VERSION ""

NS_ :

BS_:

BU_: BCMB_AUXM FCIM MRCMA_RSCM SCMJ BCMB_ALCM SCMB_PSM SCMD SCMC HVAC_RCCM MRCMB MRCMA DASM GFM_FTRM BCMB_CAPM DCMH SFMB SFMA SOBDMD_AHCM_FOH TRM GWM _delete BCMB_ABM SODL SCMF RTM RHVAC PDM DCMG DCMF DCME SCMH SCMG HSWM RSM SODR DDM RBM RGTM DSM SCME GENERIC TSTR

BO_ 2015 TesterFunctionalReq_M1: 8 TSTR
 SG_ TesterFunctionalReq : 7|64@0+ (1,0) [0|1.84467E+019] "unitless"  DASM,GFM_FTRM,FCIM,MRCMA_RSCM,SODR,BCMB_AUXM,SODL,SCMB_PSM,SCMC,SCMD,HVAC_RCCM,MRCMA,MRCMB,RHVAC,BCMB_CAPM,BCMB_ALCM,SCMJ,BCMB_ABM,DCME,DCMF,DCMG,DCMH,SFMA,SFMB,SOBDMD_AHCM_FOH,PDM,SCMG,SCMH,TRM,RSM,RTM,GWM,DDM,DSM,HSWM,RBM,RGTM,SCME,SCMF

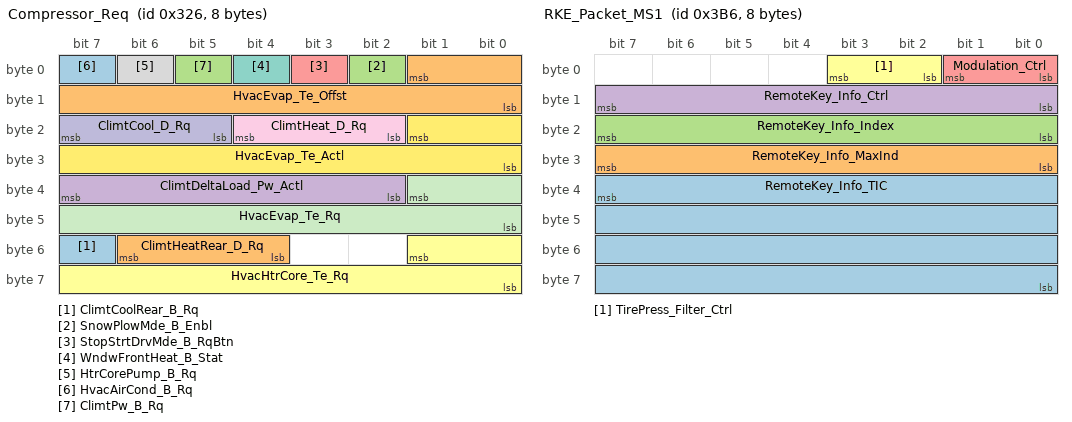
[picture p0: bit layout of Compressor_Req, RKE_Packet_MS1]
BO_ 806 Compressor_Req: 8 HVAC_RCCM
 SG_ ClimtCoolRear_B_Rq : 55|1@0+ (1,0) [0|1] "SED"  GWM
 SG_ ClimtHeatRear_D_Rq : 54|3@0+ (1,0) [0|7] "SED"  GWM
 SG_ SnowPlowMde_B_Enbl : 2|1@0+ (1,0) [0|1] "SED"  SCMG,SCMH,GWM,SCMC,SCMD
 SG_ ClimtDeltaLoad_Pw_Actl : 39|6@0+ (50,-1600) [-1600|1450] "watts"  GWM
 SG_ StopStrtDrvMde_B_RqBtn : 3|1@0+ (1,0) [0|1] "SED"  GWM
 SG_ HvacHtrCore_Te_Rq : 49|10@0+ (0.25,-50) [-50|205.75] "degC"  GWM
 SG_ WndwFrontHeat_B_Stat : 4|1@0+ (1,0) [0|1] "SED"  GWM
 SG_ HtrCorePump_B_Rq : 6|1@0+ (1,0) [0|1] "SED"  GWM
 SG_ ClimtHeat_D_Rq : 20|3@0+ (1,0) [0|7] "SED"  GWM
 SG_ ClimtCool_D_Rq : 23|3@0+ (1,0) [0|7] "SED"  GWM
 SG_ HvacEvap_Te_Rq : 33|10@0+ (0.125,-50) [-50|77.875] "Degrees C"  GWM
 SG_ HvacEvap_Te_Actl : 17|10@0+ (0.125,-50) [-50|77.75] "Degrees C"  GWM
 SG_ HvacAirCond_B_Rq : 7|1@0+ (1,0) [0|1] "SED"  GWM
 SG_ HvacEvap_Te_Offst : 1|10@0+ (0.125,-50) [-50|77.875] "Degrees C"  GWM
 SG_ ClimtPw_B_Rq : 5|1@0+ (1,0) [0|1] "SED"  GWM

BO_ 950 RKE_Packet_MS1: 8 GWM
 SG_ RemoteKey_Info_TIC : 39|32@0+ (1,0) [0|4294967295] "Unitless"  RTM
 SG_ RemoteKey_Info_MaxInd : 31|8@0+ (1,0) [0|255] "Unitless"  RTM
 SG_ RemoteKey_Info_Index : 23|8@0+ (1,0) [0|255] "Unitless"  RTM
 SG_ RemoteKey_Info_Ctrl : 15|8@0+ (1,0) [0|255] "Unitless"  GENERIC
 SG_ Modulation_Ctrl : 1|2@0+ (1,0) [0|3] "SED"  GENERIC
 SG_ TirePress_Filter_Ctrl : 3|2@0+ (1,0) [0|3] "SED"  RTM

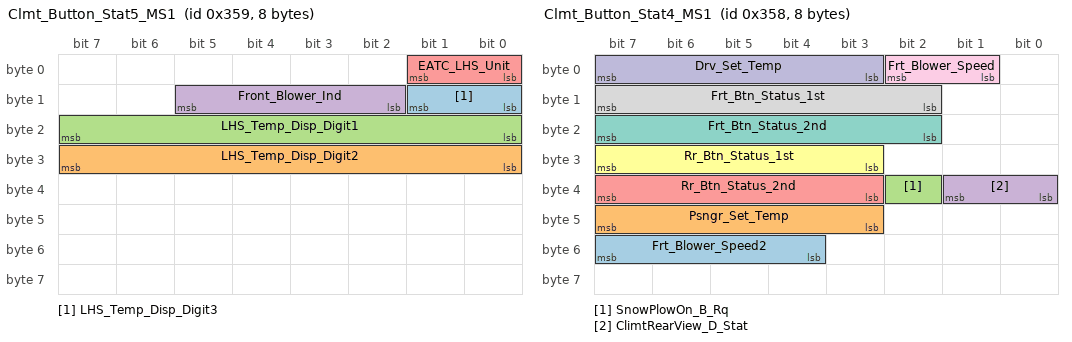
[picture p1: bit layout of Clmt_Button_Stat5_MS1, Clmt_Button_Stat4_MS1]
BO_ 857 Clmt_Button_Stat5_MS1: 8 GWM
 SG_ LHS_Temp_Disp_Digit3 : 9|2@0+ (1,0) [0|3] "SED"  FCIM,HVAC_RCCM
 SG_ LHS_Temp_Disp_Digit2 : 31|8@0+ (1,0) [0|255] "ASCII"  FCIM,HVAC_RCCM
 SG_ LHS_Temp_Disp_Digit1 : 23|8@0+ (1,0) [0|255] "ASCII"  FCIM,HVAC_RCCM
 SG_ Front_Blower_Ind : 13|4@0+ (1,0) [0|15] "SED"  FCIM,HVAC_RCCM
 SG_ EATC_LHS_Unit : 1|2@0+ (1,0) [0|3] "SED"  FCIM,HVAC_RCCM

BO_ 856 Clmt_Button_Stat4_MS1: 8 GWM
 SG_ Frt_Blower_Speed2 : 55|4@0+ (1,0) [0|15] "SED"  HVAC_RCCM,FCIM
 SG_ Psngr_Set_Temp : 47|5@0+ (1,0) [0|31] "SED"  FCIM,HVAC_RCCM
 SG_ SnowPlowOn_B_Rq : 34|1@0+ (1,0) [0|1] "SED"  HVAC_RCCM
 SG_ ClimtRearView_D_Stat : 33|2@0+ (1,0) [0|3] "SED"  FCIM,HVAC_RCCM
 SG_ Rr_Btn_Status_2nd : 39|5@0+ (1,0) [0|31] "SED"  FCIM,HVAC_RCCM
 SG_ Rr_Btn_Status_1st : 31|5@0+ (1,0) [0|31] "SED"  FCIM,HVAC_RCCM
 SG_ Frt_Btn_Status_2nd : 23|6@0+ (1,0) [0|63] "SED"  FCIM,HVAC_RCCM
 SG_ Frt_Btn_Status_1st : 15|6@0+ (1,0) [0|63] "SED"  FCIM,HVAC_RCCM
 SG_ Frt_Blower_Speed : 2|2@0+ (1,0) [0|3] "SED"  FCIM,HVAC_RCCM
 SG_ Drv_Set_Temp : 7|5@0+ (1,0) [0|31] "SED"  FCIM,HVAC_RCCM

BO_ 855 Clmt_Button_Stat3: 8 HVAC_RCCM
 SG_ Rr_Temp_Detents : 63|6@0+ (1,0) [0|63] "SED"  RHVAC,GWM
 SG_ Rr_Power_Btn_Stt : 57|2@0+ (1,0) [0|3] "SED"  RHVAC,GWM
 SG_ Rr_RH_Cond_Seat_Stat : 18|3@0+ (1,0) [0|7] "SED"  RHVAC,GWM
 SG_ Rr_Pnl_Flr_Btn_Stt : 33|2@0+ (1,0) [0|3] "SED"  RHVAC,GWM
 SG_ Rr_LH_Cond_Seat_Stat : 21|3@0+ (1,0) [0|7] "SED"  RHVAC,GWM
 SG_ CC_Rr_Stat_User_Adj : 7|4@0+ (1,0) [0|15] "SED"  RHVAC,GWM
 SG_ Rr_Set_Temp_Units : 41|2@0+ (1,0) [0|3] "SED"  RHVAC,GWM
 SG_ Rr_RHS_Set_Temp_Dig3 : 43|2@0+ (1,0) [0|3] "SED"  RHVAC,GWM
 SG_ Rr_RHS_Set_Temp_Dig2 : 51|4@0+ (1,0) [0|15] "SED"  RHVAC,GWM
 SG_ Rr_RHS_Set_Temp_Dig1 : 55|4@0+ (1,0) [0|15] "SED"  RHVAC,GWM
 SG_ Rr_RH_Htd_Seat_Btn_Stt : 45|2@0+ (1,0) [0|3] "SED"  RHVAC,GWM
 SG_ Rr_RH_Cld_Seat_Btn_Stt : 47|2@0+ (1,0) [0|3] "SED"  RHVAC,GWM
 SG_ Rr_Panel_Btn_Stt : 35|2@0+ (1,0) [0|3] "SED"  RHVAC,GWM
 SG_ Rr_On_Indicator : 2|1@0+ (1,0) [0|1] "SED"  RHVAC,GWM
 SG_ Rr_LHS_Set_Temp_Dig3 : 37|2@0+ (1,0) [0|3] "SED"  RHVAC,GWM
 SG_ Rr_LHS_Set_Temp_Dig2 : 25|4@0+ (1,0) [0|15] "SED"  RHVAC,GWM
 SG_ Rr_LHS_Set_Temp_Dig1 : 29|4@0+ (1,0) [0|15] "SED"  RHVAC,GWM
 SG_ Rr_LH_Htd_Seat_Btn_Stt : 31|2@0+ (1,0) [0|3] "SED"  RHVAC,GWM
 SG_ Rr_LH_Cld_Seat_Btn_Stt : 23|2@0+ (1,0) [0|3] "SED"  RHVAC,GWM
 SG_ Rr_Floor_Btn_Stt : 9|2@0+ (1,0) [0|3] "SED"  RHVAC,GWM
 SG_ Rr_Control_Btn_Stt : 11|2@0+ (1,0) [0|3] "SED"  RHVAC,GWM
 SG_ Rr_Blower_Indicate : 15|4@0+ (1,0) [0|15] "SED"  RHVAC,GWM
 SG_ Rr_AUTO_Btn_Stt : 1|2@0+ (1,0) [0|3] "SED"  RHVAC,GWM

BO_ 854 Clmt_Button_Stat2: 8 HVAC_RCCM
 SG_ Dsp_RotAddrBtnEv_St : 63|4@0+ (1,0) [0|15] "SED"  GWM
 SG_ SelDrvMdeButtn_B_Stat : 55|1@0+ (1,0) [0|1] "SED"  GWM
 SG_ SteEffortButtn_B_Stat : 54|1@0+ (1,0) [0|1] "SED"  GWM
 SG_ LHS_Auto_Seat_Btn_Stt : 59|2@0+ (1,0) [0|3] "SED"  GWM
 SG_ RHS_Auto_Seat_Btn_Stt : 57|2@0+ (1,0) [0|3] "SED"  GWM
 SG_ SelDrvMdeSwtch_D_Stat2 : 51|2@0+ (1,0) [0|3] "SED"  GWM
 SG_ CC_Fr_Stat_User_Adj : 6|3@0+ (1,0) [0|7] "SED"  GWM
 SG_ EngExhMdeQuiet_B_RqDrv : 52|1@0+ (1,0) [0|1] "SED"  GWM
 SG_ LnchCtlSys_B_RqDrv : 53|1@0+ (1,0) [0|1] "SED"  GWM
 SG_ Front_Blower_Indicate : 13|4@0+ (1,0) [0|15] "SED"  GWM
 SG_ CC_Diagnostics_Active : 7|1@0+ (1,0) [0|1] "SED"  GWM
 SG_ RHS_Temp_Display_Digit3 : 3|2@0+ (1,0) [0|3] "SED"  GWM
 SG_ RHS_Temp_Display_Digit2 : 47|8@0+ (1,0) [0|255] "ASCII"  GWM
 SG_ RHS_Temp_Display_Digit1 : 39|8@0+ (1,0) [0|255] "ASCII"  GWM
 SG_ LHS_Temp_Display_Digit3 : 9|2@0+ (1,0) [0|3] "SED"  GWM
 SG_ LHS_Temp_Display_Digit2 : 31|8@0+ (1,0) [0|255] "ASCII"  GWM
 SG_ LHS_Temp_Display_Digit1 : 23|8@0+ (1,0) [0|255] "ASCII"  GWM
 SG_ EATC_RHS_Units : 15|2@0+ (1,0) [0|3] "SED"  GWM
 SG_ EATC_LHS_Units : 1|2@0+ (1,0) [0|3] "SED"  GWM

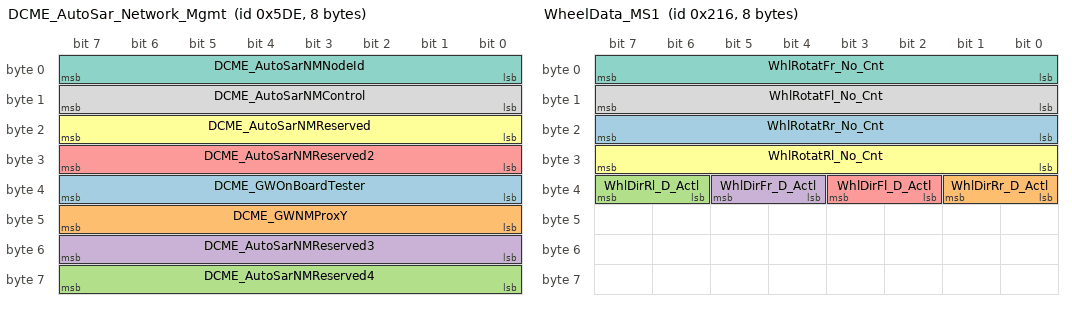
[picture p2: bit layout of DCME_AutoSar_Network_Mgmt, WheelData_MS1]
BO_ 1502 DCME_AutoSar_Network_Mgmt: 8 DCME
 SG_ DCME_GWOnBoardTester : 39|8@0+ (1,0) [0|255] "unitless"  GWM
 SG_ DCME_GWNMProxY : 47|8@0+ (1,0) [0|255] "unitless"  GWM
 SG_ DCME_AutoSarNMReserved4 : 63|8@0+ (1,0) [0|255] "unitless"  GWM
 SG_ DCME_AutoSarNMReserved3 : 55|8@0+ (1,0) [0|255] "unitless"  GWM
 SG_ DCME_AutoSarNMReserved2 : 31|8@0+ (1,0) [0|255] "unitless"  GWM
 SG_ DCME_AutoSarNMReserved : 23|8@0+ (1,0) [0|255] "unitless"  GWM
 SG_ DCME_AutoSarNMNodeId : 7|8@0+ (1,0) [0|255] "unitless"  GWM
 SG_ DCME_AutoSarNMControl : 15|8@0+ (1,0) [0|255] "unitless"  GWM

BO_ 534 WheelData_MS1: 8 GWM
 SG_ WhlRotatRr_No_Cnt : 23|8@0+ (1,0) [0|255] "Unitless"  SODR,SODL
 SG_ WhlDirRr_D_Actl : 33|2@0+ (1,0) [0|3] "SED"  SODR,SODL,GENERIC
 SG_ WhlDirRl_D_Actl : 39|2@0+ (1,0) [0|3] "SED"  SODR,SODL,GENERIC
 SG_ WhlDirFr_D_Actl : 37|2@0+ (1,0) [0|3] "SED"  SODR,SODL,GENERIC
 SG_ WhlDirFl_D_Actl : 35|2@0+ (1,0) [0|3] "SED"  SODR,SODL,GENERIC
 SG_ WhlRotatRl_No_Cnt : 31|8@0+ (1,0) [0|255] "Unitless"  SODR,SODL
 SG_ WhlRotatFr_No_Cnt : 7|8@0+ (1,0) [0|255] "Unitless"  SODR,SODL
 SG_ WhlRotatFl_No_Cnt : 15|8@0+ (1,0) [0|255] "Unitless"  SODR,SODL

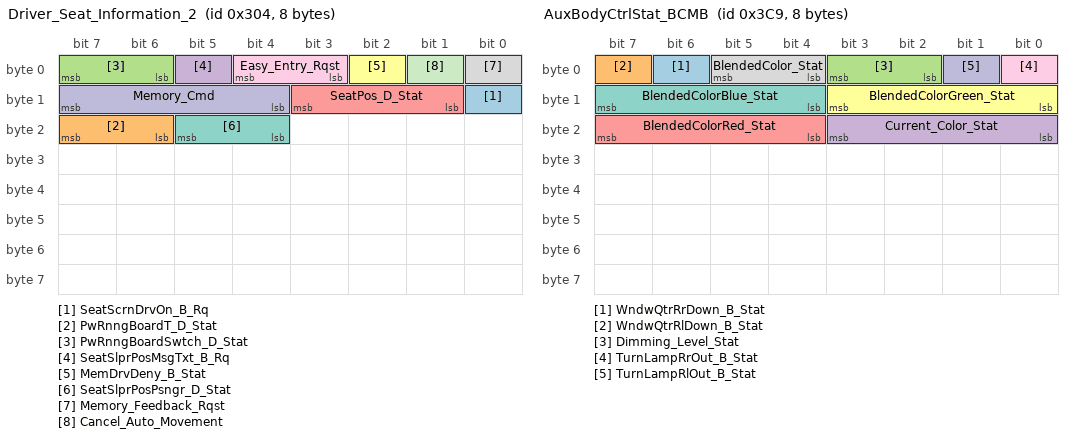
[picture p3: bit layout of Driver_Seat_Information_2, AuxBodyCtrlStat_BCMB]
BO_ 772 Driver_Seat_Information_2: 8 DSM
 SG_ SeatScrnDrvOn_B_Rq : 8|1@0+ (1,0) [0|1] "SED"  GWM
 SG_ PwRnngBoardT_D_Stat : 23|2@0+ (1,0) [0|3] "SED"  GWM
 SG_ PwRnngBoardSwtch_D_Stat : 7|2@0+ (1,0) [0|3] "SED"  GWM
 SG_ SeatSlprPosMsgTxt_B_Rq : 5|1@0+ (1,0) [0|1] "SED"  GWM
 SG_ SeatPos_D_Stat : 11|3@0+ (1,0) [0|7] "SED"  BCMB_CAPM
 SG_ MemDrvDeny_B_Stat : 2|1@0+ (1,0) [0|1] "SED"  GWM
 SG_ SeatSlprPosPsngr_D_Stat : 21|2@0+ (1,0) [0|3] "SED"  GWM
 SG_ Memory_Feedback_Rqst : 0|1@0+ (1,0) [0|1] "SED"  GWM
 SG_ Easy_Entry_Rqst : 4|2@0+ (1,0) [0|3] "SED"  BCMB_CAPM,SCMH,SCMG
 SG_ Memory_Cmd : 15|4@0+ (1,0) [0|15] "SED"  GWM,BCMB_CAPM,SCMH,DDM,PDM,SCMG
 SG_ Cancel_Auto_Movement : 1|1@0+ (1,0) [0|1] "SED"  SCMH,BCMB_CAPM,PDM,DDM,SCMG

BO_ 935 Side_Detect_R_Stat_MS1: 8 SODR
 SG_ LcwaRight_D_Stat : 52|3@0+ (1,0) [0|7] "SED"  GWM
 SG_ LcwaDetctRight1_B_Stat : 41|1@0+ (1,0) [0|1] "SED"  GWM
 SG_ SodInnrRight_D_Stat : 20|2@0+ (1,0) [0|3] "SED"  GWM,SODL
 SG_ RbaCtaRight_D_Stat : 55|3@0+ (1,0) [0|7] "SED"  GWM
 SG_ LcwaDetctRight2_B_Stat : 40|1@0+ (1,0) [0|1] "SED"  GWM
 SG_ CtaInnrRight_D_Stat : 27|2@0+ (1,0) [0|3] "SED"  GWM,SODL
 SG_ CtaAlrtRight2_D_Stat : 30|3@0+ (1,0) [0|7] "SED"  GWM
 SG_ BttRight_D_Stat : 45|3@0+ (1,0) [0|7] "SED"  GWM,SODL
 SG_ BttRight_D_RqDrv : 47|2@0+ (1,0) [0|3] "SED"  GWM,SODL
 SG_ CtaBrkRightMsgTxt_B_Rq : 42|1@0+ (1,0) [0|1] "SED"  GWM
 SG_ CtaRightBrkEnbl_B_Rq : 31|1@0+ (1,0) [0|1] "SED"  GWM,SODL
 SG_ CtaRightBrkDecel_B_Rq : 7|1@0+ (1,0) [0|1] "SED"  GWM,SODL
 SG_ Side_Detect_R_Illum : 39|8@0+ (1,0) [0|255] "Percent"  GWM,DDM,PDM
 SG_ CtaSnsRight_D_Stat : 25|2@0+ (1,0) [0|3] "SED"  GWM,SODL
 SG_ CtaAlrtRight_D_Stat : 8|1@0+ (1,0) [0|1] "SED"  GWM,DDM,PDM
 SG_ CtaRight_D_Stat : 18|3@0+ (1,0) [0|7] "SED"  GWM,SODL
 SG_ SodRight_D_Stat : 15|3@0+ (1,0) [0|7] "SED"  GWM,SODL
 SG_ SodSnsRight_D_Stat : 12|2@0+ (1,0) [0|3] "SED"  GWM,SODL,DDM,PDM
 SG_ SodAlrtRight_D_Stat : 10|2@0+ (1,0) [0|3] "SED"  GWM,DDM,PDM
 SG_ SodDetctRight_D_Stat : 23|3@0+ (1,0) [0|7] "SED"  GWM
 SG_ SodWarnRight_Prd_Rq : 6|7@0+ (1,0) [0|127] "millisecond"  GWM,DDM,PDM

BO_ 934 Side_Detect_L_Stat_MS1: 8 SODL
 SG_ RbaCtaLeft_D_Stat : 55|3@0+ (1,0) [0|7] "SED"  GWM
 SG_ SodInnrLeft_D_Stat : 20|2@0+ (1,0) [0|3] "SED"  GWM,SODR
 SG_ CtaInnrLeft_D_Stat : 27|2@0+ (1,0) [0|3] "SED"  GWM,SODR
 SG_ LcwaLeft_D_Stat : 52|3@0+ (1,0) [0|7] "SED"  GWM
 SG_ LcwaDetctLeft2_B_Stat : 40|1@0+ (1,0) [0|1] "SED"  GWM
 SG_ LcwaDetctLeft1_B_Stat : 41|1@0+ (1,0) [0|1] "SED"  GWM
 SG_ CtaAlrtLeft2_D_Stat : 30|3@0+ (1,0) [0|7] "SED"  GWM
 SG_ CtaBrkLeftMsgTxt_B_Rq : 42|1@0+ (1,0) [0|1] "SED"  GWM
 SG_ CtaLeftBrkDecel_B_Rq : 7|1@0+ (1,0) [0|1] "SED"  GWM,SODR
 SG_ CtaLeftBrkEnbl_B_Rq : 31|1@0+ (1,0) [0|1] "SED"  GWM,SODR
 SG_ Side_Detect_L_Illum : 39|8@0+ (1,0) [0|255] "Percent"  GWM,DDM,PDM
 SG_ BttLeft_D_Stat : 45|3@0+ (1,0) [0|7] "SED"  GWM,SODR
 SG_ BttLeft_D_RqDrv : 47|2@0+ (1,0) [0|3] "SED"  GWM,SODR
 SG_ CtaSnsLeft_D_Stat : 25|2@0+ (1,0) [0|3] "SED"  GWM,SODR
 SG_ SodDetctLeft_D_Stat : 23|3@0+ (1,0) [0|7] "SED"  GWM
 SG_ CtaLeft_D_Stat : 18|3@0+ (1,0) [0|7] "SED"  GWM,SODR
 SG_ CtaAlrtLeft_D_Stat : 8|1@0+ (1,0) [0|1] "SED"  GWM,DDM,PDM
 SG_ SodLeft_D_Stat : 15|3@0+ (1,0) [0|7] "SED"  GWM,SODR
 SG_ SodSnsLeft_D_Stat : 12|2@0+ (1,0) [0|3] "SED"  GWM,SODR,DDM,PDM
 SG_ SodAlrtLeft_D_Stat : 10|2@0+ (1,0) [0|3] "SED"  GWM,DDM,PDM
 SG_ SodWarnLeft_Prd_Rq : 6|7@0+ (1,0) [0|127] "millisecond"  GWM,DDM,PDM

BO_ 969 AuxBodyCtrlStat_BCMB: 8 BCMB_ABM
 SG_ WndwQtrRrDown_B_Stat : 6|1@0+ (1,0) [0|1] "SED"  GWM,MRCMA
 SG_ WndwQtrRlDown_B_Stat : 7|1@0+ (1,0) [0|1] "SED"  GWM,MRCMA
 SG_ Dimming_Level_Stat : 3|2@0+ (1,0) [0|3] "SED"  GWM
 SG_ Current_Color_Stat : 19|4@0+ (1,0) [0|15] "SED"  GWM
 SG_ BlendedColorRed_Stat : 23|4@0+ (1,0) [0|15] "SED"  GWM
 SG_ BlendedColorGreen_Stat : 11|4@0+ (1,0) [0|15] "SED"  GWM
 SG_ BlendedColorBlue_Stat : 15|4@0+ (1,0) [0|15] "SED"  GWM
 SG_ BlendedColor_Stat : 5|2@0+ (1,0) [0|3] "SED"  GWM
 SG_ TurnLampRrOut_B_Stat : 0|1@0+ (1,0) [0|1] "SED"  GWM
 SG_ TurnLampRlOut_B_Stat : 1|1@0+ (1,0) [0|1] "SED"  GWM

BO_ 1070 EngineData_2_MS1: 8 GWM
 SG_ StopStrtStdby_D_Indic_UB : 43|1@0+ (1,0) [0|1] "SED"  FCIM,HVAC_RCCM
 SG_ PassRstrnInd_Req_UB : 42|1@0+ (1,0) [0|1] "SED"  FCIM,HVAC_RCCM
 SG_ HiElPwInhbt_B_Stat_UB : 61|1@0+ (1,0) [0|1] "SED"  DDM,PDM
 SG_ HiElPwInhbt_B_Stat : 47|1@0+ (1,0) [0|1] "SED"  DDM,PDM
 SG_ StopStrtStdby_D_Indic : 46|3@0+ (1,0) [0|7] "SED"  FCIM,HVAC_RCCM
 SG_ CoolantFanStepAct_UB : 2|1@0+ (1,0) [0|1] "SED"  FCIM,HVAC_RCCM
 SG_ CoolantFanStepAct : 7|5@0+ (1,0) [0|31] "Steps"  FCIM,HVAC_RCCM
 SG_ Reserve_UB : 1|1@0+ (1,0) [0|1] "SED"  GENERIC
 SG_ RstrnImpactEvntStatus_UB : 56|1@0+ (1,0) [0|1] "SED"  DDM,PDM,FCIM,GFM_FTRM,SODR,SODL,HVAC_RCCM,DCME,DCMF,DCMG,DCMH,SOBDMD_AHCM_FOH
 SG_ EngAirIn_Te_Actl_UB : 60|1@0+ (1,0) [0|1] "SED"  FCIM,HVAC_RCCM
 SG_ RstrnImpactEvntStatus : 59|3@0+ (1,0) [0|7] "SED"  DDM,PDM,FCIM,GFM_FTRM,SODR,SODL,HVAC_RCCM,DCME,DCMF,DCMG,DCMH,SOBDMD_AHCM_FOH
 SG_ EngAirIn_Te_Actl : 55|10@0+ (0.25,-128) [-128|127.25] "degC"  FCIM,HVAC_RCCM
 SG_ EngAout_N_Actl_UB : 0|1@0+ (1,0) [0|1] "SED"  FCIM,HVAC_RCCM,SOBDMD_AHCM_FOH
 SG_ EngAout_N_Actl : 28|13@0+ (2,0) [0|16382] "rpm"  FCIM,HVAC_RCCM,SOBDMD_AHCM_FOH
 SG_ VehVActlEng_D_Qf : 31|2@0+ (1,0) [0|3] "SED"  FCIM,SCME,SCMF,SODR,SOBDMD_AHCM_FOH,SODL,HVAC_RCCM,MRCMA,MRCMB,DCME,DCMF,DCMG,DCMH,BCMB_CAPM,DSM,RBM,RTM,DDM,PDM
 SG_ Veh_V_ActlEng_UB : 29|1@0+ (1,0) [0|1] "SED"  FCIM,SCME,SCMF,MRCMA_RSCM,SODR,RHVAC,SCMJ,SOBDMD_AHCM_FOH,SODL,HVAC_RCCM,MRCMA,MRCMB,BCMB_ABM,BCMB_ALCM,DCME,DCMF,DCMG,DCMH,BCMB_CAPM,RBM,RGTM,DSM,SCMG,SCMH,DDM,PDM,RTM
 SG_ Veh_V_ActlEng : 15|16@0+ (0.01,0) [0|655.35] "kph"  FCIM,SCME,SCMF,MRCMA_RSCM,SODR,HVAC_RCCM,RHVAC,SCMJ,SOBDMD_AHCM_FOH,SODL,MRCMA,MRCMB,BCMB_ABM,BCMB_ALCM,DCME,DCMF,DCMG,DCMH,BCMB_CAPM,RBM,RGTM,DSM,SCMG,SCMH,DDM,PDM,RTM
 SG_ PassRstrnInd_Req : 41|2@0+ (1,0) [0|3] "SED"  FCIM,HVAC_RCCM

BO_ 1050 Climate_Control_Data: 8 HVAC_RCCM
 SG_ CamraRearBttn_D_Stat : 35|1@0+ (1,0) [0|1] "SED"  GWM
 SG_ TrailCtlSwtch_B_Stat : 16|1@0+ (1,0) [0|1] "SED"  GWM
 SG_ CamraFrntBttn_D_Stat : 8|1@0+ (1,0) [0|1] "SED"  GWM
 SG_ AutoHoldSwtch_D_Stat : 20|2@0+ (1,0) [0|3] "SED"  GWM
 SG_ GlvBoxRleas_No_Actl : 23|3@0+ (1,0) [0|7] "unitless"  GWM
 SG_ EcoInhbt_B_RqHvac : 17|1@0+ (1,0) [0|1] "SED"  GWM
 SG_ LpdbPtc3_B_Rq : 36|1@0+ (1,0) [0|1] "SED"  GWM
 SG_ LpdbPtc2_B_Rq : 37|1@0+ (1,0) [0|1] "SED"  GWM
 SG_ LpdbPtc1_B_Rq : 38|1@0+ (1,0) [0|1] "SED"  GWM
 SG_ LpdbHeatWiprPrk_B_Rq : 39|1@0+ (1,0) [0|1] "SED"  GWM
 SG_ LpdbDfrstRearOn_B_Rq : 24|1@0+ (1,0) [0|1] "SED"  GWM
 SG_ LpdbDfrstFrOn_B_Rq : 25|1@0+ (1,0) [0|1] "SED"  GWM
 SG_ LpdbDfrstFlOn_B_Rq : 26|1@0+ (1,0) [0|1] "SED"  GWM
 SG_ LpdbAuxBlwr_B_Rq : 27|1@0+ (1,0) [0|1] "SED"  GWM
 SG_ PrkAidSwtch_No_Cnt : 31|4@0+ (1,0) [0|15] "Unitless"  GWM
 SG_ PrkAidSwtch_D_RqDrv : 18|1@0+ (1,0) [0|1] "SED"  GWM
 SG_ SteWhlHeat_D_Rq : 13|4@0+ (1,0) [0|15] "SED"  GWM,HSWM
 SG_ MirrorHeatOn_B_Rq : 14|1@0+ (1,0) [0|1] "SED"  GWM,DDM,PDM
 SG_ Remote_Start_QuietMode : 15|1@0+ (1,0) [0|1] "SED"  GWM
 SG_ DrvSlipCtlMde_B_Rq : 9|1@0+ (1,0) [0|1] "SED"  GWM
 SG_ Outside_Air_Temp_Stat : 7|8@0+ (0.5,-40) [-40|86.5] "Degrees C"  GFM_FTRM,RGTM,DCME,DCMF,DCMG,DCMH,GWM,DDM,PDM,SOBDMD_AHCM_FOH

BO_ 1856 TesterPhysicalReqDDM: 8 TSTR
 SG_ TesterPhysicalReqDDM : 7|64@0+ (1,0) [0|1.84467E+019] "unitless"  DDM

BO_ 1864 TesterPhysicalResDDM: 8 DDM
 SG_ TesterPhysicalResDDM : 7|64@0+ (1,0) [0|1.84467E+019] "unitless"  TSTR

BO_ 1937 TesterPhysicalReqTRM: 8 TSTR
 SG_ TesterPhysicalReqTRM : 7|64@0+ (1,0) [0|1.84467E+019] "unitless"  TRM

BO_ 947 BodyInfo_3_MS1: 8 GWM
 SG_ DimmingLvlEvnt_No_Actl : 18|2@0+ (1,0) [0|3] "unitless"  GENERIC
 SG_ DrStatDrvErrCnt_B_Stat : 19|1@0+ (1,0) [0|1] "SED"  GENERIC
 SG_ TurnLghtRightOn_B_Stat : 35|1@0+ (1,0) [0|1] "SED"  GENERIC
 SG_ TurnLghtLeftOn_B_Stat : 54|1@0+ (1,0) [0|1] "SED"  GENERIC
 SG_ Backlit_LED_Status : 23|4@0+ (1,0) [0|15] "SED"  FCIM,DCME,DCMF,DCMG,DCMH,SFMA,SFMB,HVAC_RCCM,RHVAC,DDM,PDM
 SG_ FogLghtRearOn_B_Stat : 1|1@0+ (1,0) [0|1] "SED"  TRM
 SG_ ValetMode_D_Mem : 16|1@0+ (1,0) [0|1] "SED"  RGTM
 SG_ IgnKeyType_D_Actl : 39|4@0+ (1,0) [0|15] "SED"  SODR,SODL,RSM
 SG_ TurnLghtRight_D_Rq : 63|2@0+ (1,0) [0|3] "SED"  BCMB_ABM,RSM,BCMB_ALCM,DDM,PDM,TRM
 SG_ Parklamp_Status : 3|2@0+ (1,0) [0|3] "SED"  FCIM,DCMG,SODR,DCMH,SODL,HVAC_RCCM,RHVAC,TRM,PDM,DDM
 SG_ Litval : 47|8@0+ (1,0) [0|253] "SED"  FCIM,SODR,DCME,DCMF,DCMG,DCMH,SODL,HVAC_RCCM,RHVAC,DDM,PDM
 SG_ Key_In_Ignition_Stat : 11|1@0+ (1,0) [0|1] "SED"  SFMA,SFMB,RSM,BCMB_CAPM,SCMG,SCMH,SCMC,SCMD,DSM,RTM
 SG_ Ignition_Status : 7|4@0+ (1,0) [0|15] "SED"  FCIM,GFM_FTRM,MRCMA_RSCM,SODR,SODL,SFMA,SFMB,SCMB_PSM,SCME,HVAC_RCCM,MRCMA,MRCMB,RHVAC,SCMD,BCMB_ALCM,BCMB_ABM,SCMJ,RSM,DCME,DCMF,DCMG,DCMH,BCMB_CAPM,SCMC,DDM,DSM,HSWM,PDM,RBM,RGTM,RTM,SCMF,SCMG,SCMH,TRM,SOBDMD_AHCM_FOH
 SG_ Dimming_Lvl : 31|8@0+ (1,0) [0|253] "SED"  SFMA,SFMB,DCMG,DCMH,FCIM,HVAC_RCCM,RHVAC,BCMB_ALCM,BCMB_ABM,DDM,PDM
 SG_ Day_Night_Status : 15|2@0+ (1,0) [0|3] "SED"  FCIM,DCMG,DCMH,TRM,HVAC_RCCM,RHVAC,DDM,PDM
 SG_ Remote_Start_Status : 13|2@0+ (1,0) [0|3] "SED"  FCIM,HVAC_RCCM,RHVAC,RSM
 SG_ DrStatTgate_B_Actl : 0|1@0+ (1,0) [0|1] "SED"  FCIM,DDM,PDM,SCMJ,RSM,TRM,HVAC_RCCM
 SG_ DrStatRr_B_Actl : 49|1@0+ (1,0) [0|1] "SED"  MRCMA_RSCM,FCIM,DSM,SODR,SODL,HVAC_RCCM,SCMJ,RGTM,DDM,PDM,DCME,DCMF,DCMG,DCMH,RBM,RSM
 SG_ DrStatRl_B_Actl : 48|1@0+ (1,0) [0|1] "SED"  MRCMA_RSCM,FCIM,DSM,SODR,SODL,HVAC_RCCM,SCMJ,RGTM,DDM,PDM,DCME,DCMF,DCMG,DCMH,RBM,RSM
 SG_ DrStatPsngr_B_Actl : 60|1@0+ (1,0) [0|1] "SED"  MRCMA_RSCM,FCIM,SODR,SCMJ,SCMB_PSM,SODL,RGTM,DDM,PDM,DCME,DCMF,DCMG,DCMH,RBM,RSM,HVAC_RCCM,DSM
 SG_ DrStatInnrTgate_B_Actl : 58|1@0+ (1,0) [0|1] "SED"  FCIM,TRM,DDM,RSM,SCMJ,HVAC_RCCM,GENERIC
 SG_ DrStatHood_B_Actl : 59|1@0+ (1,0) [0|1] "SED"  RSM,GENERIC
 SG_ DrStatDrv_B_Actl : 61|1@0+ (1,0) [0|1] "SED"  MRCMA_RSCM,FCIM,SODR,SODL,RGTM,HVAC_RCCM,DDM,PDM,DCME,DCMF,DCMG,DCMH,RBM,RSM,DSM
 SG_ PrkBrkActv_B_Actl : 55|1@0+ (1,0) [0|1] "SED"  SODR,SODL,GENERIC
 SG_ LifeCycMde_D_Actl : 53|4@0+ (1,0) [0|15] "SED"  FCIM,GFM_FTRM,DSM,MRCMA_RSCM,SCMB_PSM,SCMJ,HVAC_RCCM,RGTM,TRM,RBM,BCMB_ALCM,BCMB_CAPM,RHVAC,DCME,DCMF,DCMG,DCMH,RTM,DDM,PDM,SOBDMD_AHCM_FOH,HSWM
 SG_ Delay_Accy : 57|1@0+ (1,0) [0|1] "SED"  FCIM,GFM_FTRM,MRCMA,MRCMB,BCMB_ALCM,BCMB_ABM,DCME,DCMF,DCMG,DCMH,DDM,PDM
 SG_ FogLghtFrontOn_B_Stat : 56|1@0+ (1,0) [0|1] "SED"  GENERIC
 SG_ TurnLghtLeft_D_Rq : 9|2@0+ (1,0) [0|3] "SED"  BCMB_ABM,RSM,BCMB_ALCM,DDM,PDM,TRM
 SG_ CrashEvnt_D_Stat : 34|2@0+ (1,0) [0|3] "SED"  GFM_FTRM,DDM,PDM,FCIM,DSM,HVAC_RCCM,RBM
 SG_ FuelPmpInhbt_B_Stat : 32|1@0+ (1,0) [0|1] "SED"  FCIM,HVAC_RCCM
 SG_ BodySrvcRqd_B_Rq : 10|1@0+ (1,0) [0|1] "SED"  GENERIC

BO_ 293 ClmtCtrlSeatSet_Stat_v2: 8 SCME
 SG_ ClmtCtrlSeat_SetStat_Psgr : 15|8@0+ (1,0) [0|254] "SED"  FCIM,HVAC_RCCM
 SG_ ClmtCtrlSeat_SetStat_Dvr : 7|8@0+ (1,0) [0|254] "SED"  FCIM,HVAC_RCCM

BO_ 1841 TesterPhysicalReqANT: 8 TSTR
 SG_ TesterPhysicalReqANT : 7|64@0+ (1,0) [0|1.84467E+019] "unitless"  GENERIC

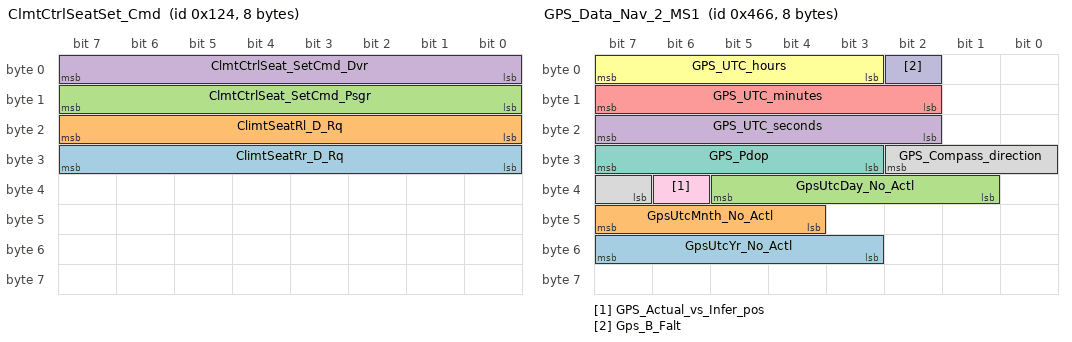
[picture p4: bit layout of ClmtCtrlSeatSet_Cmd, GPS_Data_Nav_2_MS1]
BO_ 292 ClmtCtrlSeatSet_Cmd: 8 HVAC_RCCM
 SG_ ClimtSeatRr_D_Rq : 31|8@0+ (1,0) [0|254] "SED"  SCMF
 SG_ ClimtSeatRl_D_Rq : 23|8@0+ (1,0) [0|254] "SED"  SCME,SCMF
 SG_ ClmtCtrlSeat_SetCmd_Psgr : 15|8@0+ (1,0) [0|254] "SED"  DSM,SCMF,SCME
 SG_ ClmtCtrlSeat_SetCmd_Dvr : 7|8@0+ (1,0) [0|254] "SED"  DSM,SCME

BO_ 1126 GPS_Data_Nav_2_MS1: 8 GWM
 SG_ GpsUtcYr_No_Actl : 55|5@0+ (1,2010) [2010|2040] "Year"  RSM
 SG_ GpsUtcMnth_No_Actl : 47|4@0+ (1,1) [1|15] "Month"  RSM
 SG_ GpsUtcDay_No_Actl : 37|5@0+ (1,1) [1|32] "Day"  RSM
 SG_ GPS_UTC_seconds : 23|6@0+ (1,0) [0|59] "seconds"  RSM
 SG_ GPS_UTC_minutes : 15|6@0+ (1,0) [0|59] "Minutes"  RSM
 SG_ GPS_UTC_hours : 7|5@0+ (1,0) [0|23] "Hours"  RSM
 SG_ GPS_Pdop : 31|5@0+ (0.2,0) [0|5.8] "unitless"  RSM
 SG_ GPS_Compass_direction : 26|4@0+ (1,0) [0|15] "SED"  RSM
 SG_ GPS_Actual_vs_Infer_pos : 38|1@0+ (1,0) [0|1] "SED"  RSM
 SG_ Gps_B_Falt : 2|1@0+ (1,0) [0|1] "SED"  RSM

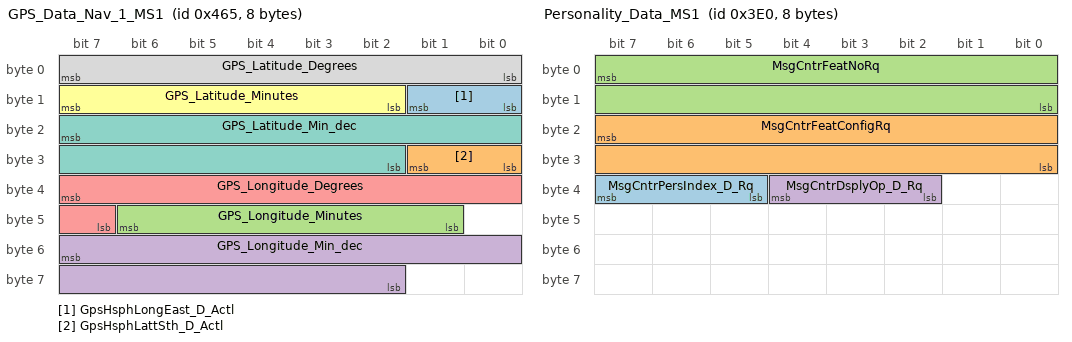
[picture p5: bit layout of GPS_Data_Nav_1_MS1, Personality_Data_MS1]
BO_ 1125 GPS_Data_Nav_1_MS1: 8 GWM
 SG_ GpsHsphLongEast_D_Actl : 9|2@0+ (1,0) [0|3] "SED"  RSM
 SG_ GpsHsphLattSth_D_Actl : 25|2@0+ (1,0) [0|3] "SED"  RSM
 SG_ GPS_Longitude_Minutes : 46|6@0+ (1,0) [0|61] "Minutes"  RSM
 SG_ GPS_Longitude_Min_dec : 55|14@0+ (0.0001,0) [0|1.6381] "Minutes"  RSM
 SG_ GPS_Longitude_Degrees : 39|9@0+ (1,-179) [-179|330] "Degrees"  RSM
 SG_ GPS_Latitude_Minutes : 15|6@0+ (1,0) [0|61] "Minutes"  RSM
 SG_ GPS_Latitude_Min_dec : 23|14@0+ (0.0001,0) [0|1.6381] "Minutes"  RSM
 SG_ GPS_Latitude_Degrees : 7|8@0+ (1,-89) [-89|164] "Degrees"  RSM

BO_ 992 Personality_Data_MS1: 8 GWM
 SG_ MsgCntrPersIndex_D_Rq : 39|3@0+ (1,0) [0|7] "SED"  FCIM,HVAC_RCCM,PDM,BCMB_CAPM,DDM,DSM
 SG_ MsgCntrFeatConfigRq : 23|16@0+ (1,0) [0|65535] "unitless"  FCIM,HVAC_RCCM,PDM,BCMB_CAPM,DDM,DSM
 SG_ MsgCntrFeatNoRq : 7|16@0+ (1,0) [0|65535] "Number"  FCIM,HVAC_RCCM,PDM,BCMB_CAPM,DDM,DSM
 SG_ MsgCntrDsplyOp_D_Rq : 36|3@0+ (1,0) [0|7] "SED"  FCIM,HVAC_RCCM,PDM,BCMB_CAPM,DDM,DSM

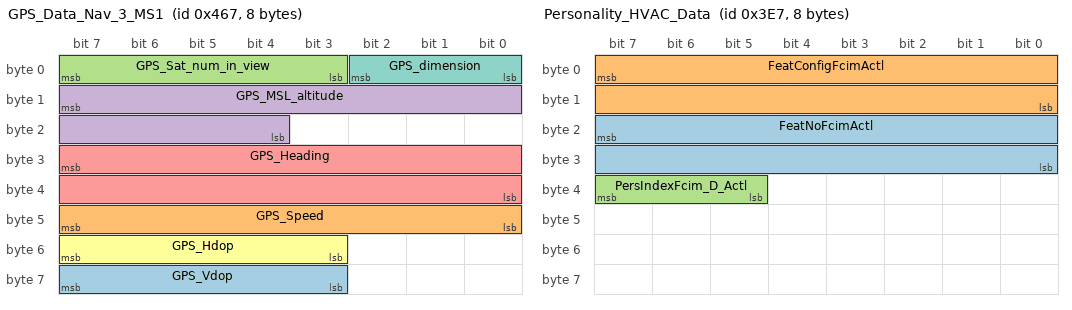
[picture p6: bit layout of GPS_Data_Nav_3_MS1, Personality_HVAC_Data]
BO_ 1127 GPS_Data_Nav_3_MS1: 8 GWM
 SG_ GPS_Vdop : 63|5@0+ (0.2,0) [0|5.8] "unitless"  RSM
 SG_ GPS_Speed : 47|8@0+ (1,0) [0|253] "MPH"  RSM
 SG_ GPS_Sat_num_in_view : 7|5@0+ (1,0) [0|29] "unitless"  RSM
 SG_ GPS_MSL_altitude : 15|12@0+ (10,-20460) [-20460|20470] "feet"  RSM
 SG_ GPS_Heading : 31|16@0+ (0.01,0) [0|655.33] "Degrees"  RSM
 SG_ GPS_Hdop : 55|5@0+ (0.2,0) [0|5.8] "unitless"  RSM
 SG_ GPS_dimension : 2|3@0+ (1,0) [0|7] "SED"  RSM

BO_ 861 HSWheel_CC_Info_Stat: 8 HSWM
 SG_ SteWhlHeat_D_Stat : 7|4@0+ (1,0) [0|15] "SED"  FCIM,GWM,HVAC_RCCM

BO_ 1919 TesterPhysicalResSCMF: 8 SCMF
 SG_ TesterPhysicalResSCMF : 7|64@0+ (1,0) [0|1.84467E+019] "unitless"  TSTR

BO_ 1911 TesterPhysicalReqSCMF: 8 TSTR
 SG_ TesterPhysicalReqSCMF : 7|64@0+ (1,0) [0|1.84467E+019] "unitless"  SCMF

BO_ 999 Personality_HVAC_Data: 8 HVAC_RCCM
 SG_ FeatNoFcimActl : 23|16@0+ (1,0) [0|65535] "Number"  GWM
 SG_ FeatConfigFcimActl : 7|16@0+ (1,0) [0|65535] "Undefined"  GWM
 SG_ PersIndexFcim_D_Actl : 39|3@0+ (1,0) [0|7] "SED"  GWM

BO_ 2027 TesterPhysicalResAHCM: 8 SOBDMD_AHCM_FOH
 SG_ TesterPhysicalResAHCM : 7|64@0+ (1,0) [0|1.84467E+019] "unitless"  TSTR

BO_ 2019 TesterPhysicalReqAHCM: 8 TSTR
 SG_ TesterPhysicalReqAHCM : 7|64@0+ (1,0) [0|1.84467E+019] "unitless"  SOBDMD_AHCM_FOH

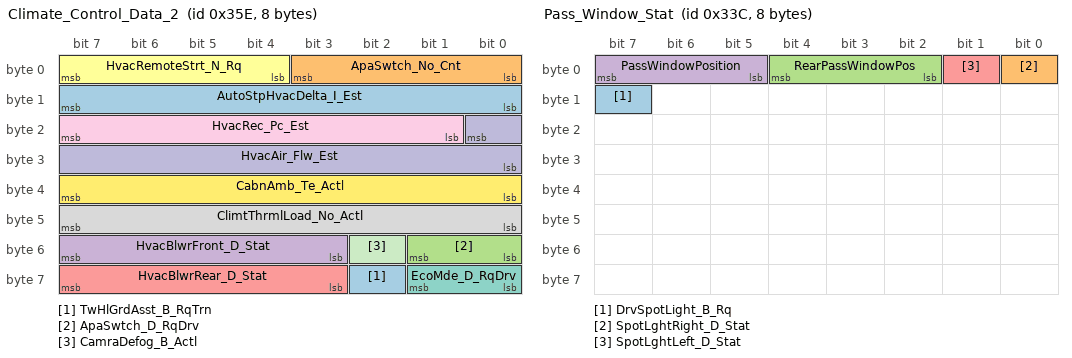
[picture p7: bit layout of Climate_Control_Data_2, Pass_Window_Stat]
BO_ 862 Climate_Control_Data_2: 8 HVAC_RCCM
 SG_ TwHlGrdAsst_B_RqTrn : 58|1@0+ (1,0) [0|1] "SED"  GWM
 SG_ ApaSwtch_No_Cnt : 3|4@0+ (1,0) [0|15] "Unitless"  GWM
 SG_ ApaSwtch_D_RqDrv : 49|2@0+ (1,0) [0|3] "SED"  GWM
 SG_ HvacBlwrFront_D_Stat : 55|5@0+ (1,0) [0|31] "SED"  DSM,DCMG,DCMH,SCME,SCMF,RGTM,GWM
 SG_ HvacBlwrRear_D_Stat : 63|5@0+ (1,0) [0|31] "SED"  DSM,SCME,SCMF,GWM
 SG_ HvacRemoteStrt_N_Rq : 7|4@0+ (100,450) [450|1950] "RPM"  GWM
 SG_ EcoMde_D_RqDrv : 57|2@0+ (1,0) [0|3] "SED"  GWM
 SG_ ClimtThrmlLoad_No_Actl : 47|8@0+ (1,0) [0|254] "unitless"  GWM
 SG_ HvacRec_Pc_Est : 23|7@0+ (1,0) [0|127] "Percent"  GWM
 SG_ HvacAir_Flw_Est : 16|9@0+ (0.5,0) [0|255.5] "liter/second"  GWM
 SG_ CamraDefog_B_Actl : 50|1@0+ (1,0) [0|1] "SED"  GWM
 SG_ CabnAmb_Te_Actl : 39|8@0+ (0.5,-57) [-57|70] "degreesC"  RBM,DSM,SCMJ,SCME,SCMF,RGTM,DCME,DCMF,DCMG,DCMH,SOBDMD_AHCM_FOH,GWM
 SG_ AutoStpHvacDelta_I_Est : 15|8@0+ (1,-192) [-192|62] "ampere"  GWM

BO_ 828 Pass_Window_Stat: 8 PDM
 SG_ DrvSpotLight_B_Rq : 15|1@0+ (1,0) [0|1] "SED"  GWM,DDM
 SG_ SpotLghtRight_D_Stat : 0|1@0+ (1,0) [0|1] "SED"  GWM
 SG_ RearPassWindowPos : 4|3@0+ (1,0) [0|7] "SED"  FCIM,RGTM,HVAC_RCCM,GWM
 SG_ PassWindowPosition : 7|3@0+ (1,0) [0|7] "SED"  FCIM,RGTM,HVAC_RCCM,GWM
 SG_ SpotLghtLeft_D_Stat : 1|1@0+ (1,0) [0|1] "SED"  GWM

BO_ 1894 TesterPhysicalReqRBM: 8 TSTR
 SG_ TesterPhysicalReqRBM : 7|64@0+ (1,0) [0|1.84467E+019] "unitless"  RBM

BO_ 1909 TesterPhysicalReqRGTM: 8 TSTR
 SG_ TesterPhysicalReqRGTM : 7|64@0+ (1,0) [0|1.84467E+019] "unitless"  RGTM

BO_ 1917 TesterPhysicalResRGTM: 8 RGTM
 SG_ TesterPhysicalResRGTM : 7|64@0+ (1,0) [0|1.84467E+019] "unitless"  TSTR

BO_ 1902 TesterPhysicalResRBM: 8 RBM
 SG_ TesterPhysicalResRBM : 7|64@0+ (1,0) [0|1.84467E+019] "unitless"  TSTR

BO_ 1860 TesterPhysicalReqDSM: 8 TSTR
 SG_ TesterPhysicalReqDSM : 7|64@0+ (1,0) [0|1.84467E+019] "unitless"  DSM

BO_ 1868 TesterPhysicalResDSM: 8 DSM
 SG_ TesterPhysicalResDSM : 7|64@0+ (1,0) [0|1.84467E+019] "unitless"  TSTR

BO_ 1918 TesterPhysicalResSCME: 8 SCME
 SG_ TesterPhysicalResSCME : 7|64@0+ (1,0) [0|1.84467E+019] "unitless"  TSTR

BO_ 1910 TesterPhysicalReqSCME: 8 TSTR
 SG_ TesterPhysicalReqSCME : 7|64@0+ (1,0) [0|1.84467E+019] "unitless"  SCME

BO_ 1814 TesterPhysicalReqGWM_M1: 8 TSTR
 SG_ TesterPhysicalReqGWM_M1 : 7|64@0+ (1,0) [0|1.84467E+019] "unitless"  GWM

BO_ 1822 TesterPhysicalResGWM_MS1: 8 GWM
 SG_ TesterPhysicalResGWM_M1 : 7|64@0+ (1,0) [0|1.84467E+019] "unitless"  TSTR

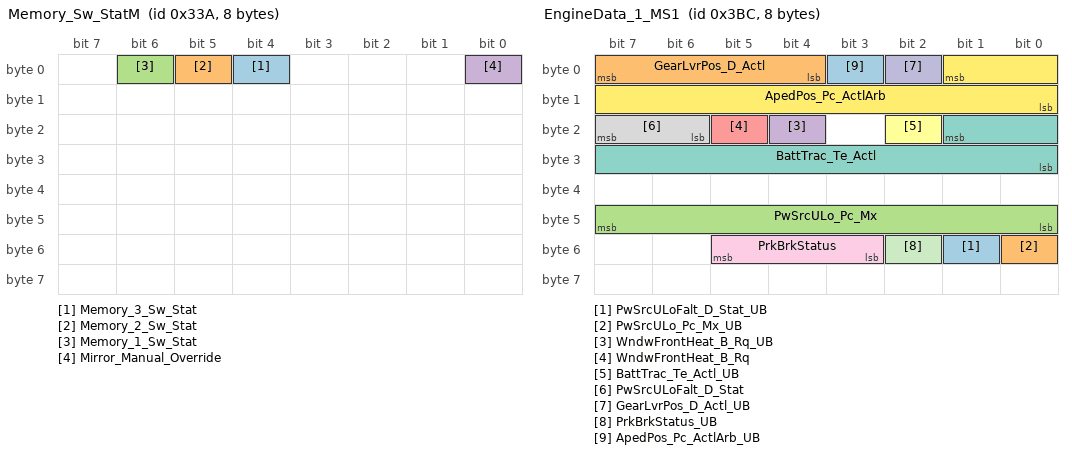
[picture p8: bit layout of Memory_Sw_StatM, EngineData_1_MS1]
BO_ 826 Memory_Sw_StatM: 8 DDM
 SG_ Memory_3_Sw_Stat : 4|1@0+ (1,0) [0|1] "SED"  GENERIC,BCMB_CAPM,DSM
 SG_ Memory_2_Sw_Stat : 5|1@0+ (1,0) [0|1] "SED"  GENERIC,BCMB_CAPM,DSM
 SG_ Memory_1_Sw_Stat : 6|1@0+ (1,0) [0|1] "SED"  GENERIC,BCMB_CAPM,DSM
 SG_ Mirror_Manual_Override : 0|1@0+ (1,0) [0|1] "SED"  GENERIC,BCMB_CAPM,DSM

BO_ 1289 AHCM_Network_MgmtM: 8 SOBDMD_AHCM_FOH
 SG_ AHCM_Network_Mgmt : 7|8@0+ (1,0) [0|254] "unitless"  HVAC_RCCM,GENERIC

BO_ 1098 TrailerInfo_2: 8 TRM
 SG_ TrlrAidSwtch_D_RqDrv : 35|2@0+ (1,0) [0|3] "SED"  GWM
 SG_ TrlrAidCtl_U_RqDrv : 31|12@0+ (0.00125,0) [0|5.11625] "volt"  GWM

BO_ 1326 SFMB_Network_MgmtM: 8 SFMB
 SG_ SFMB_Network_Mgmt : 7|64@0+ (1,0) [0|1.84467440737096E+019] "unitless"  GENERIC

BO_ 1325 SFMA_Network_MgmtM: 8 SFMA
 SG_ SFMA_Network_Mgmt : 7|64@0+ (1,0) [0|1.84467440737096E+019] "unitless"  GENERIC

BO_ 1802 TesterPhysicalResSCMC: 8 SCMC
 SG_ TesterPhysicalResSCMC : 7|64@0+ (1,0) [0|1.84467E+019] "unitless"  TSTR

BO_ 1385 SCMD_Network_MgmtM: 8 SCMD
 SG_ SCMD_Network_Mgmt : 7|64@0+ (1,0) [0|1.84467440737096E+019] "unitless"  GENERIC

BO_ 1306 SCMC_Network_MgmtM: 8 SCMC
 SG_ SCMC_Network_Mgmt : 7|64@0+ (1,0) [0|1.84467440737096E+019] "unitless"  GENERIC

BO_ 1115 RearClimateSeat_Data: 8 SCMF
 SG_ ClimtSeatRr_D_Stat : 15|8@0+ (1,0) [0|254] "SED"  GWM,HVAC_RCCM,RHVAC
 SG_ ClimtSeatRl_D_Stat : 7|8@0+ (1,0) [0|254] "SED"  GWM,HVAC_RCCM,RHVAC

BO_ 853 Clmt_Button_Stat1: 8 HVAC_RCCM
 SG_ MdeMnu_Buttn_Stat : 58|1@0+ (1,0) [0|1] "SED"  GWM
 SG_ Front_AUTO_Blwr_Lvl : 60|2@0+ (1,0) [0|3] "SED"  GWM
 SG_ RearMnu_Buttn_Stat : 48|1@0+ (1,0) [0|1] "SED"  GWM
 SG_ FrontMnu_Buttn_Stat : 49|1@0+ (1,0) [0|1] "SED"  GWM
 SG_ DrvrFcsdMde_Btn_Stt : 57|2@0+ (1,0) [0|3] "SED"  GWM
 SG_ RHS_Cond_Seat_Status : 63|3@0+ (1,0) [0|7] "SED"  GWM
 SG_ LHS_Cond_Seat_Status : 10|3@0+ (1,0) [0|7] "SED"  GWM
 SG_ Htd_Strg_Whl_Status : 27|2@0+ (1,0) [0|3] "SED"  GWM
 SG_ Htd_Strg_Whl_Btn_Stt : 29|2@0+ (1,0) [0|3] "SED"  GWM
 SG_ Defrost_Btn_Stt : 3|2@0+ (1,0) [0|3] "SED"  FCIM,GWM
 SG_ CC_Fr_Btn_User_Adj : 15|5@0+ (1,0) [0|31] "SED"  GWM
 SG_ RHS_Htd_Seat_Btn_Stt : 53|2@0+ (1,0) [0|3] "SED"  GWM
 SG_ RHS_Cld_Seat_Btn_Stt : 55|2@0+ (1,0) [0|3] "SED"  GWM
 SG_ Outside_Btn_Stt : 47|2@0+ (1,0) [0|3] "SED"  GWM
 SG_ LHS_Htd_Seat_Btn_Stt : 39|2@0+ (1,0) [0|3] "SED"  GWM
 SG_ LHS_Cld_Seat_Btn_Stt : 25|2@0+ (1,0) [0|3] "SED"  GWM
 SG_ Htd_Frt_Wsh_Btn_Stt : 31|2@0+ (1,0) [0|3] "SED"  GWM
 SG_ Auto_Recirc_Btn_Stt : 5|2@0+ (1,0) [0|3] "SED"  GWM
 SG_ Recirc_Btn_Stt : 41|2@0+ (1,0) [0|3] "SED"  FCIM,RGTM,GWM
 SG_ Rear_Defrost_Btn_Stt : 43|2@0+ (1,0) [0|3] "SED"  FCIM,GWM
 SG_ My_Temp_Btn_Stt : 33|2@0+ (1,0) [0|3] "SED"  GWM
 SG_ Max_Defrost_Btn_Stt : 35|2@0+ (1,0) [0|3] "SED"  FCIM,GWM
 SG_ Max_AC_Btn_Stt : 37|2@0+ (1,0) [0|3] "SED"  FCIM,GWM
 SG_ Front_AUTO_Label : 19|2@0+ (1,0) [0|3] "SED"  FCIM,GWM
 SG_ Windscreen_Btn_Stt : 51|2@0+ (1,0) [0|3] "SED"  FCIM,GWM
 SG_ Panel_Btn_Stt : 45|2@0+ (1,0) [0|3] "SED"  GWM
 SG_ Front_Power_Btn_Stt : 17|2@0+ (1,0) [0|3] "SED"  FCIM,GWM
 SG_ Front_AUTO_Btn_Stt : 21|2@0+ (1,0) [0|3] "SED"  FCIM,GWM
 SG_ Floor_Btn_Stt : 23|2@0+ (1,0) [0|3] "SED"  GWM
 SG_ Dual_Button_Stt : 1|2@0+ (1,0) [0|3] "SED"  GWM
 SG_ AC_Btn_Stt : 7|2@0+ (1,0) [0|3] "SED"  FCIM,GWM

BO_ 1034 GGCC_Config_Mgmt_ID_1_MS1: 8 GWM
 SG_ VehicleGGCCData : 7|64@0+ (1,0) [0|1.84467E+019] "mixed"  GFM_FTRM,DSM,FCIM,MRCMA_RSCM,SODR,SODL,HVAC_RCCM,TRM,DCME,DCMF,DCMG,DCMH,PDM,SOBDMD_AHCM_FOH,RTM,DDM,GENERIC,RBM,RGTM,SCMF

BO_ 956 EngineData_1_MS1: 8 GWM
 SG_ PwSrcULoFalt_D_Stat_UB : 49|1@0+ (1,0) [0|1] "SED"  FCIM,HVAC_RCCM
 SG_ PwSrcULo_Pc_Mx_UB : 48|1@0+ (1,0) [0|1] "SED"  FCIM,HVAC_RCCM
 SG_ PwSrcULo_Pc_Mx : 47|8@0+ (0.4,0) [0|101.6] "%"  FCIM,HVAC_RCCM
 SG_ WndwFrontHeat_B_Rq_UB : 20|1@0+ (1,0) [0|1] "SED"  FCIM,HVAC_RCCM
 SG_ WndwFrontHeat_B_Rq : 21|1@0+ (1,0) [0|1] "SED"  FCIM,HVAC_RCCM
 SG_ BattTrac_Te_Actl_UB : 18|1@0+ (1,0) [0|1] "SED"  FCIM,HVAC_RCCM
 SG_ BattTrac_Te_Actl : 17|10@0+ (0.5,-50) [-50|460.5] "degC"  FCIM,HVAC_RCCM
 SG_ PwSrcULoFalt_D_Stat : 23|2@0+ (1,0) [0|3] "SED"  FCIM,HVAC_RCCM
 SG_ PrkBrkStatus : 53|3@0+ (1,0) [0|7] "SED"  FCIM,SODR,SODL,HVAC_RCCM
 SG_ GearLvrPos_D_Actl_UB : 2|1@0+ (1,0) [0|1] "SED"  FCIM,SODR,SCMB_PSM,SCMJ,BCMB_CAPM,SODL,HVAC_RCCM,RBM,DCME,DCMF,DCMG,DCMH,RGTM,DSM,SCMG,SCMH,DDM,PDM
 SG_ PrkBrkStatus_UB : 50|1@0+ (1,0) [0|1] "SED"  FCIM,SODR,SODL,HVAC_RCCM
 SG_ ApedPos_Pc_ActlArb : 1|10@0+ (0.1,0) [0|102.3] "%"  FCIM,HVAC_RCCM
 SG_ ApedPos_Pc_ActlArb_UB : 3|1@0+ (1,0) [0|1] "SED"  FCIM,HVAC_RCCM
 SG_ GearLvrPos_D_Actl : 7|4@0+ (1,0) [0|15] "SED"  FCIM,SODR,SCMB_PSM,SCMJ,BCMB_CAPM,SODL,HVAC_RCCM,RBM,DCME,DCMF,DCMG,DCMH,RGTM,DSM,SCMG,SCMH,DDM,PDM

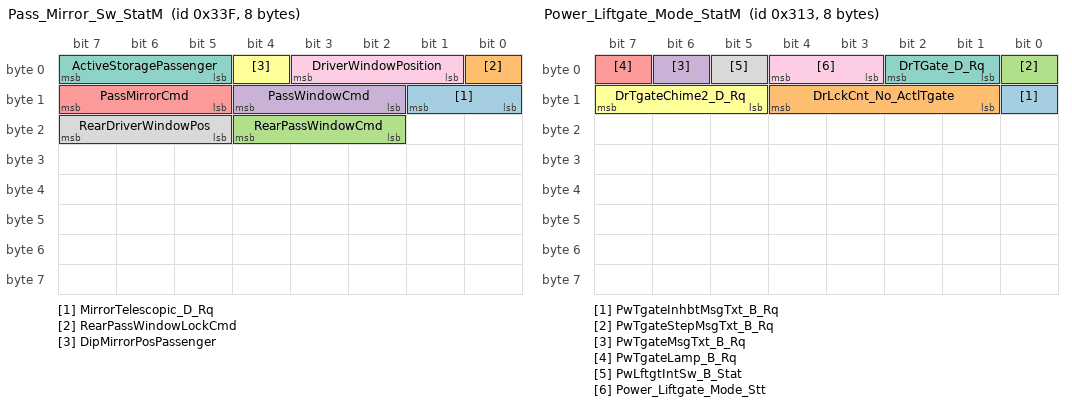
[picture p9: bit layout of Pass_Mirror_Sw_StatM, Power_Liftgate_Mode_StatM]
BO_ 831 Pass_Mirror_Sw_StatM: 8 DDM
 SG_ MirrorTelescopic_D_Rq : 9|2@0+ (1,0) [0|3] "SED"  PDM,GWM
 SG_ RearPassWindowLockCmd : 0|1@0+ (1,0) [0|1] "SED"  GWM,PDM
 SG_ RearPassWindowCmd : 20|3@0+ (1,0) [0|7] "SED"  GWM,PDM
 SG_ PassWindowCmd : 12|3@0+ (1,0) [0|7] "SED"  GWM,PDM
 SG_ PassMirrorCmd : 15|3@0+ (1,0) [0|7] "SED"  GWM,PDM
 SG_ DipMirrorPosPassenger : 4|1@0+ (1,0) [0|1] "SED"  GWM,PDM
 SG_ ActiveStoragePassenger : 7|3@0+ (1,0) [0|7] "SED"  GWM,PDM
 SG_ RearDriverWindowPos : 23|3@0+ (1,0) [0|7] "SED"  FCIM,RGTM,HVAC_RCCM,GWM
 SG_ DriverWindowPosition : 3|3@0+ (1,0) [0|7] "SED"  FCIM,RGTM,HVAC_RCCM,GWM

BO_ 1820 TesterPhysicalResHSWM: 8 HSWM
 SG_ TesterPhysicalResHSWM : 7|64@0+ (1,0) [0|1.84467E+019] "unitless"  TSTR

BO_ 1812 TesterPhysicalReqHSWM: 8 TSTR
 SG_ TesterPhysicalReqHSWM : 7|64@0+ (1,0) [0|1.84467E+019] "unitless"  HSWM

BO_ 787 Power_Liftgate_Mode_StatM: 8 RGTM
 SG_ PwTgateInhbtMsgTxt_B_Rq : 8|1@0+ (1,0) [0|1] "SED"  GENERIC,GWM
 SG_ DrLckCnt_No_ActlTgate : 12|4@0+ (1,0) [0|15] "unitless"  GENERIC,GWM
 SG_ PwTgateStepMsgTxt_B_Rq : 0|1@0+ (1,0) [0|1] "SED"  GWM
 SG_ PwTgateMsgTxt_B_Rq : 6|1@0+ (1,0) [0|1] "SED"  GWM
 SG_ PwTgateLamp_B_Rq : 7|1@0+ (1,0) [0|1] "SED"  GWM
 SG_ DrTgateChime2_D_Rq : 15|3@0+ (1,0) [0|7] "SED"  GENERIC,GWM
 SG_ DrTGate_D_Rq : 2|2@0+ (1,0) [0|3] "SED"  FCIM,HVAC_RCCM,GWM
 SG_ PwLftgtIntSw_B_Stat : 5|1@0+ (1,0) [0|1] "SED"  GENERIC,GWM
 SG_ Power_Liftgate_Mode_Stt : 4|2@0+ (1,0) [0|3] "SED"  GENERIC,GWM

BO_TX_BU_ 806 : FCIM,HVAC_RCCM;
BO_TX_BU_ 855 : FCIM,HVAC_RCCM;
BO_TX_BU_ 854 : FCIM,HVAC_RCCM;
BO_TX_BU_ 1050 : FCIM,HVAC_RCCM;
BO_TX_BU_ 293 : DSM,SCME;
BO_TX_BU_ 292 : FCIM,HVAC_RCCM;
BO_TX_BU_ 999 : FCIM,HVAC_RCCM;
BO_TX_BU_ 862 : FCIM,HVAC_RCCM;
BO_TX_BU_ 787 : GWM,RGTM;
CM_ BO_ 2015 "OBDII Request ($7DF) messages are for FNOS 1.0.1 only.
Diagnostic Functional Addressing ($7DF) and Dual Rate Periodic messages are for FNOS I3 only.";
CM_ SG_ 857 LHS_Temp_Disp_Digit3 "Added for MY 08";
CM_ SG_ 857 LHS_Temp_Disp_Digit2 "Added for MY 08";
CM_ SG_ 857 LHS_Temp_Disp_Digit1 "Added for MY 08";
CM_ SG_ 857 EATC_LHS_Unit "Added for MY 08";
CM_ SG_ 854 RHS_Temp_Display_Digit3 "Added for MY 08";
CM_ SG_ 854 RHS_Temp_Display_Digit2 "Added for MY 08";
CM_ SG_ 854 RHS_Temp_Display_Digit1 "Added for MY 08";
CM_ SG_ 854 LHS_Temp_Display_Digit3 "Added for MY 08";
CM_ SG_ 854 LHS_Temp_Display_Digit2 "Added for MY 08";
CM_ SG_ 854 LHS_Temp_Display_Digit1 "Added for MY 08";
CM_ SG_ 854 EATC_RHS_Units "Added for MY 08";
CM_ SG_ 854 EATC_LHS_Units "Added for MY 08";
CM_ SG_ 534 WhlRotatRr_No_Cnt "DCR 1833 to update Tx from GWM to EP100ms. Wheel Count signals are used by complex algorithm to determine Tire Pressure by Location & can't change from 20msec. (jweinfur)";
CM_ SG_ 534 WhlRotatRl_No_Cnt "DCR 1833 to update Tx from GWM to EP100ms. Wheel Count signals are used by complex algorithm to determine Tire Pressure by Location & can't change from 20msec. (jweinfur)";
CM_ SG_ 534 WhlRotatFr_No_Cnt "DCR 1833 to update Tx from GWM to EP100ms. Wheel Count signals are used by complex algorithm to determine Tire Pressure by Location & can't change from 20msec. (jweinfur)";
CM_ SG_ 534 WhlRotatFl_No_Cnt "DCR 1833 to update Tx from GWM to EP100ms. Wheel Count signals are used by complex algorithm to determine Tire Pressure by Location & can't change from 20msec. (jweinfur)";
CM_ SG_ 772 Memory_Feedback_Rqst "Updated to 1 bit for CGEA, Not backwards compatible";
CM_ SG_ 969 TurnLampRrOut_B_Stat "Signal not transmitted on vehicles without a BCMB module.";
CM_ SG_ 969 TurnLampRlOut_B_Stat "Signal not transmitted on vehicles without a BCMB module.";
CM_ SG_ 1070 HiElPwInhbt_B_Stat "Signal not transmitted on HEV programs";
CM_ SG_ 1070 Reserve_UB "Reserve for legacy VehVActlEng_D_Qf";
CM_ SG_ 1050 Outside_Air_Temp_Stat "Filtered value, i.e. same as disply for customer";
CM_ SG_ 947 Dimming_Lvl "Refer to Vehicle Interior Illum Dimming Ctrl Sys Eng Spec, Table 2

";
CM_ SG_ 947 PrkBrkActv_B_Actl "Signal not transmitted on vehicles with electric park brake. ";
CM_ BO_ 1126 "HS3 APIM Sync Gen3 Tx 0x463.  FrameGateway to 0x466 on HS1, HS2, HS3 and MS1.";
CM_ BO_ 1125 "HS3 APIM Sync Gen3 Tx 0x462.  FrameGateway to 0x465 on HS1, HS2, HS3 and MS1.";
CM_ BO_ 1127 "HS3 APIM Sync Gen3 Tx 0x464.  FrameGateway to 0x467 on HS1, HS2, HS3 and MS1.";
CM_ BO_ 828 "Set GenSigSendType = NoSigSendType (Cyclic) for the following signals, D.Card 3/31/08
Driver_Lock_Sw_Stat
";
CM_ SG_ 1034 VehicleGGCCData "RCMGenSigTimeout=6000";
BA_DEF_ BO_  "FrameRouting" STRING ;
BA_DEF_ BO_  "FrameGatewayNetwork" STRING ;
BA_DEF_ BO_  "NetworkInitialization" ENUM  "No","Yes";
BA_DEF_ BO_  "FrameGatewayId" HEX 0 1407;
BA_DEF_ BO_  "EventRateOfChange" INT 10 10000;
BA_DEF_ BO_  "GenMsgStartDelayTime" INT 0 10000;
BA_DEF_ BO_  "GenMsgNrOfRepetition" INT 0 100;
BA_DEF_ BO_  "GenMsgDelayTime" INT 0 1000;
BA_DEF_ BO_  "GenMsgCycleTime" INT 0 100000;
BA_DEF_ BO_  "GenMsgSendType" ENUM  "FixedPeriodic","Event","EnabledPeriodic","NotUsed","NotUsed","EventPeriodic","NotUsed","NotUsed","NoMsgSendType";
BA_DEF_ SG_  "U_CD764_MY2022_Tx" ENUM  "No","Yes";
BA_DEF_ SG_  "U_U55X_MY2022_Tx" ENUM  "No","Yes";
BA_DEF_ SG_  "U_CD542_MY2021_Tx" ENUM  "No","Yes";
BA_DEF_ SG_  "ECGUsedTxSignal" ENUM  "No","Yes";
BA_DEF_ SG_  "U_T6_MCA_MY2020_Tx" ENUM  "No","Yes";
BA_DEF_ SG_  "U_P702_MY2021_Tx" ENUM  "No","Yes";
BA_DEF_ SG_  "U_CX727_MY2021_Tx" ENUM  "No","Yes";
BA_DEF_ SG_  "U_CD764_MY2022_Rx" ENUM  "No","Yes";
BA_DEF_ SG_  "U_U55X_MY2022_Rx" ENUM  "No","Yes";
BA_DEF_ SG_  "U_CD542_MY2021_Rx" ENUM  "No","Yes";
BA_DEF_ SG_  "ECGUsedRxSignal" ENUM  "No","Yes";
BA_DEF_ SG_  "U_T6_MCA_MY2020_Rx" ENUM  "No","Yes";
BA_DEF_ SG_  "U_P702_MY2021_Rx" ENUM  "No","Yes";
BA_DEF_ SG_  "U_CX727_MY2021_Rx" ENUM  "No","Yes";
BA_DEF_ SG_  "GenSigStartValue" HEX 0 268435455;
BA_DEF_ SG_  "MetaData" ENUM  "No","Yes";
BA_DEF_ SG_  "ContentDependant" ENUM  "No","Yes";
BA_DEF_ SG_  "GenSigStartValueInteger" INT 0 1000000000;
BA_DEF_ SG_  "UsedOnPgmDBC" ENUM  "No","Yes";
BA_DEF_ SG_  "WakeupSignal" ENUM  "No","Yes";
BA_DEF_ SG_  "GenSigInactiveValue" INT 0 100000;
BA_DEF_ SG_  "GenSigSendType" ENUM  "Cyclic","OnWrite","vector_leerstring","OnChange","vector_leerstring","IfActive","vector_leerstring","NoSigSendType";
BA_DEF_ BO_  "OvtpPushApplication" ENUM  "FALSE","TRUE";
BA_DEF_ BO_  "SCP_FreshnessValueLength" INT 0 512;
BA_DEF_ BO_  "SCP_FreshnessValueTxLength" INT 0 512;
BA_DEF_ BO_  "SCP_AuthInfoTxLength" INT 0 512;
BA_DEF_ BO_  "GenMsgRoutingTimeoutTime" INT 0 5000;
BA_DEF_ BO_  "MessageGateway" ENUM  "No","Yes";
BA_DEF_ BO_  "NmAsrMessage" ENUM  "No","Yes";
BA_DEF_ BO_  "DiagState" ENUM  "No","Yes";
BA_DEF_ BO_  "TpTxIndex" INT 0 536870911;
BA_DEF_ BO_  "DiagRequest" ENUM  "No","Yes";
BA_DEF_ BO_  "DiagResponse" ENUM  "No","Yes";
BA_DEF_ BO_  "NmMessage" ENUM  "No","Yes";
BA_DEF_ BO_  "GenMsgILSupport" ENUM  "No","Yes";
BA_DEF_DEF_  "FrameRouting" "";
BA_DEF_DEF_  "FrameGatewayNetwork" "NONE";
BA_DEF_DEF_  "NetworkInitialization" "Yes";
BA_DEF_DEF_  "FrameGatewayId" 0;
BA_DEF_DEF_  "EventRateOfChange" 10000;
BA_DEF_DEF_  "GenMsgStartDelayTime" 0;
BA_DEF_DEF_  "GenMsgNrOfRepetition" 1;
BA_DEF_DEF_  "GenMsgDelayTime" 20;
BA_DEF_DEF_  "GenMsgCycleTime" 0;
BA_DEF_DEF_  "GenMsgSendType" "NoMsgSendType";
BA_DEF_DEF_  "U_CD764_MY2022_Tx" "No";
BA_DEF_DEF_  "U_U55X_MY2022_Tx" "No";
BA_DEF_DEF_  "U_CD542_MY2021_Tx" "No";
BA_DEF_DEF_  "ECGUsedTxSignal" "No";
BA_DEF_DEF_  "U_T6_MCA_MY2020_Tx" "No";
BA_DEF_DEF_  "U_P702_MY2021_Tx" "No";
BA_DEF_DEF_  "U_CX727_MY2021_Tx" "No";
BA_DEF_DEF_  "U_CD764_MY2022_Rx" "No";
BA_DEF_DEF_  "U_U55X_MY2022_Rx" "No";
BA_DEF_DEF_  "U_CD542_MY2021_Rx" "No";
BA_DEF_DEF_  "ECGUsedRxSignal" "No";
BA_DEF_DEF_  "U_T6_MCA_MY2020_Rx" "No";
BA_DEF_DEF_  "U_P702_MY2021_Rx" "No";
BA_DEF_DEF_  "U_CX727_MY2021_Rx" "No";
BA_DEF_DEF_  "GenSigStartValue" 0;
BA_DEF_DEF_  "MetaData" "No";
BA_DEF_DEF_  "ContentDependant" "No";
BA_DEF_DEF_  "GenSigStartValueInteger" 0;
BA_DEF_DEF_  "UsedOnPgmDBC" "Yes";
BA_DEF_DEF_  "WakeupSignal" "No";
BA_DEF_DEF_  "GenSigInactiveValue" 0;
BA_DEF_DEF_  "GenSigSendType" "NoSigSendType";
BA_DEF_DEF_  "OvtpPushApplication" "FALSE";
BA_DEF_DEF_  "SCP_FreshnessValueLength" 64;
BA_DEF_DEF_  "SCP_FreshnessValueTxLength" 11;
BA_DEF_DEF_  "SCP_AuthInfoTxLength" 53;
BA_DEF_DEF_  "GenMsgRoutingTimeoutTime" 0;
BA_DEF_DEF_  "MessageGateway" "No";
BA_DEF_DEF_  "NmAsrMessage" "No";
BA_DEF_DEF_  "DiagState" "No";
BA_DEF_DEF_  "TpTxIndex" 0;
BA_DEF_DEF_  "DiagRequest" "No";
BA_DEF_DEF_  "DiagResponse" "No";
BA_DEF_DEF_  "NmMessage" "No";
BA_DEF_DEF_  "GenMsgILSupport" "Yes";
BA_ "NetworkInitialization" BO_ 2015 0;
BA_ "GenMsgDelayTime" BO_ 2015 0;
BA_ "GenMsgSendType" BO_ 2015 1;
BA_ "DiagState" BO_ 2015 1;
BA_ "GenMsgILSupport" BO_ 2015 0;
BA_ "GenMsgCycleTime" BO_ 806 100;
BA_ "GenMsgSendType" BO_ 806 0;
BA_ "FrameRouting" BO_ 950 "HS1_CAN,0x3B6;";
BA_ "FrameGatewayNetwork" BO_ 950 "HS1_CAN";
BA_ "FrameGatewayId" BO_ 950 950;
BA_ "FrameRouting" BO_ 857 "HS3_CAN,0x363;";
BA_ "FrameGatewayNetwork" BO_ 857 "HS3_CAN";
BA_ "FrameGatewayId" BO_ 857 867;
BA_ "FrameRouting" BO_ 856 "HS3_CAN,0x362;";
BA_ "FrameGatewayNetwork" BO_ 856 "HS3_CAN";
BA_ "FrameGatewayId" BO_ 856 866;
BA_ "GenMsgCycleTime" BO_ 855 1000;
BA_ "GenMsgSendType" BO_ 855 5;
BA_ "GenMsgCycleTime" BO_ 854 1000;
BA_ "GenMsgSendType" BO_ 854 5;
BA_ "NetworkInitialization" BO_ 1502 0;
BA_ "GenMsgCycleTime" BO_ 1502 1000;
BA_ "GenMsgSendType" BO_ 1502 0;
BA_ "NmAsrMessage" BO_ 1502 1;
BA_ "GenMsgILSupport" BO_ 1502 0;
BA_ "GenMsgDelayTime" BO_ 534 10;
BA_ "GenMsgCycleTime" BO_ 534 100;
BA_ "GenMsgSendType" BO_ 534 0;
BA_ "GenMsgRoutingTimeoutTime" BO_ 534 60;
BA_ "MessageGateway" BO_ 534 1;
BA_ "GenMsgCycleTime" BO_ 772 1000;
BA_ "GenMsgSendType" BO_ 772 5;
BA_ "GenMsgCycleTime" BO_ 935 200;
BA_ "GenMsgSendType" BO_ 935 5;
BA_ "GenMsgCycleTime" BO_ 934 200;
BA_ "GenMsgSendType" BO_ 934 5;
BA_ "GenMsgCycleTime" BO_ 969 1000;
BA_ "GenMsgSendType" BO_ 969 5;
BA_ "GenMsgCycleTime" BO_ 1070 100;
BA_ "GenMsgSendType" BO_ 1070 5;
BA_ "GenMsgCycleTime" BO_ 1050 1000;
BA_ "GenMsgSendType" BO_ 1050 5;
BA_ "NetworkInitialization" BO_ 1856 0;
BA_ "GenMsgDelayTime" BO_ 1856 0;
BA_ "GenMsgSendType" BO_ 1856 1;
BA_ "DiagRequest" BO_ 1856 1;
BA_ "GenMsgILSupport" BO_ 1856 0;
BA_ "NetworkInitialization" BO_ 1864 0;
BA_ "GenMsgDelayTime" BO_ 1864 0;
BA_ "GenMsgSendType" BO_ 1864 1;
BA_ "DiagResponse" BO_ 1864 1;
BA_ "GenMsgILSupport" BO_ 1864 0;
BA_ "NetworkInitialization" BO_ 1937 0;
BA_ "GenMsgDelayTime" BO_ 1937 0;
BA_ "GenMsgSendType" BO_ 1937 1;
BA_ "DiagRequest" BO_ 1937 1;
BA_ "GenMsgILSupport" BO_ 1937 0;
BA_ "FrameRouting" BO_ 947 "HS1_CAN,0x3B3;";
BA_ "FrameGatewayNetwork" BO_ 947 "HS1_CAN";
BA_ "FrameGatewayId" BO_ 947 947;
BA_ "GenMsgCycleTime" BO_ 293 1000;
BA_ "GenMsgSendType" BO_ 293 5;
BA_ "NetworkInitialization" BO_ 1841 0;
BA_ "GenMsgDelayTime" BO_ 1841 0;
BA_ "GenMsgSendType" BO_ 1841 1;
BA_ "DiagRequest" BO_ 1841 1;
BA_ "GenMsgILSupport" BO_ 1841 0;
BA_ "GenMsgCycleTime" BO_ 292 1000;
BA_ "GenMsgSendType" BO_ 292 5;
BA_ "FrameRouting" BO_ 1126 "HS3_CAN,0x463;";
BA_ "FrameGatewayNetwork" BO_ 1126 "HS3_CAN";
BA_ "FrameGatewayId" BO_ 1126 1123;
BA_ "FrameRouting" BO_ 1125 "HS3_CAN,0x462;";
BA_ "FrameGatewayNetwork" BO_ 1125 "HS3_CAN";
BA_ "FrameGatewayId" BO_ 1125 1122;
BA_ "FrameRouting" BO_ 992 "HS3_CAN,0x3E0;";
BA_ "FrameGatewayNetwork" BO_ 992 "HS3_CAN";
BA_ "FrameGatewayId" BO_ 992 992;
BA_ "FrameRouting" BO_ 1127 "HS3_CAN,0x464;";
BA_ "FrameGatewayNetwork" BO_ 1127 "HS3_CAN";
BA_ "FrameGatewayId" BO_ 1127 1124;
BA_ "GenMsgCycleTime" BO_ 861 1000;
BA_ "GenMsgSendType" BO_ 861 5;
BA_ "NetworkInitialization" BO_ 1919 0;
BA_ "GenMsgDelayTime" BO_ 1919 0;
BA_ "GenMsgSendType" BO_ 1919 1;
BA_ "DiagResponse" BO_ 1919 1;
BA_ "GenMsgILSupport" BO_ 1919 0;
BA_ "NetworkInitialization" BO_ 1911 0;
BA_ "GenMsgDelayTime" BO_ 1911 0;
BA_ "GenMsgSendType" BO_ 1911 1;
BA_ "DiagRequest" BO_ 1911 1;
BA_ "GenMsgILSupport" BO_ 1911 0;
BA_ "GenMsgCycleTime" BO_ 999 1000;
BA_ "GenMsgSendType" BO_ 999 5;
BA_ "NetworkInitialization" BO_ 2027 0;
BA_ "GenMsgDelayTime" BO_ 2027 0;
BA_ "GenMsgSendType" BO_ 2027 1;
BA_ "DiagResponse" BO_ 2027 1;
BA_ "GenMsgILSupport" BO_ 2027 0;
BA_ "NetworkInitialization" BO_ 2019 0;
BA_ "GenMsgDelayTime" BO_ 2019 0;
BA_ "GenMsgSendType" BO_ 2019 1;
BA_ "DiagRequest" BO_ 2019 1;
BA_ "GenMsgILSupport" BO_ 2019 0;
BA_ "GenMsgCycleTime" BO_ 862 1000;
BA_ "GenMsgSendType" BO_ 862 5;
BA_ "GenMsgCycleTime" BO_ 828 1000;
BA_ "GenMsgSendType" BO_ 828 5;
BA_ "NetworkInitialization" BO_ 1894 0;
BA_ "GenMsgDelayTime" BO_ 1894 0;
BA_ "GenMsgSendType" BO_ 1894 1;
BA_ "DiagRequest" BO_ 1894 1;
BA_ "GenMsgILSupport" BO_ 1894 0;
BA_ "NetworkInitialization" BO_ 1909 0;
BA_ "GenMsgDelayTime" BO_ 1909 0;
BA_ "GenMsgSendType" BO_ 1909 1;
BA_ "DiagRequest" BO_ 1909 1;
BA_ "GenMsgILSupport" BO_ 1909 0;
BA_ "NetworkInitialization" BO_ 1917 0;
BA_ "GenMsgDelayTime" BO_ 1917 0;
BA_ "GenMsgSendType" BO_ 1917 1;
BA_ "DiagResponse" BO_ 1917 1;
BA_ "GenMsgILSupport" BO_ 1917 0;
BA_ "NetworkInitialization" BO_ 1902 0;
BA_ "GenMsgDelayTime" BO_ 1902 0;
BA_ "GenMsgSendType" BO_ 1902 1;
BA_ "DiagResponse" BO_ 1902 1;
BA_ "GenMsgILSupport" BO_ 1902 0;
BA_ "NetworkInitialization" BO_ 1860 0;
BA_ "GenMsgDelayTime" BO_ 1860 0;
BA_ "GenMsgSendType" BO_ 1860 1;
BA_ "DiagRequest" BO_ 1860 1;
BA_ "GenMsgILSupport" BO_ 1860 0;
BA_ "NetworkInitialization" BO_ 1868 0;
BA_ "GenMsgDelayTime" BO_ 1868 0;
BA_ "GenMsgSendType" BO_ 1868 1;
BA_ "DiagResponse" BO_ 1868 1;
BA_ "GenMsgILSupport" BO_ 1868 0;
BA_ "NetworkInitialization" BO_ 1918 0;
BA_ "GenMsgDelayTime" BO_ 1918 0;
BA_ "GenMsgSendType" BO_ 1918 1;
BA_ "DiagResponse" BO_ 1918 1;
BA_ "GenMsgILSupport" BO_ 1918 0;
BA_ "NetworkInitialization" BO_ 1910 0;
BA_ "GenMsgDelayTime" BO_ 1910 0;
BA_ "GenMsgSendType" BO_ 1910 1;
BA_ "DiagRequest" BO_ 1910 1;
BA_ "GenMsgILSupport" BO_ 1910 0;
BA_ "NetworkInitialization" BO_ 1814 0;
BA_ "GenMsgDelayTime" BO_ 1814 0;
BA_ "GenMsgSendType" BO_ 1814 1;
BA_ "DiagRequest" BO_ 1814 1;
BA_ "GenMsgILSupport" BO_ 1814 0;
BA_ "NetworkInitialization" BO_ 1822 0;
BA_ "GenMsgDelayTime" BO_ 1822 0;
BA_ "GenMsgSendType" BO_ 1822 1;
BA_ "DiagResponse" BO_ 1822 1;
BA_ "GenMsgILSupport" BO_ 1822 0;
BA_ "GenMsgStartDelayTime" BO_ 826 100;
BA_ "GenMsgCycleTime" BO_ 826 100;
BA_ "GenMsgSendType" BO_ 826 5;
BA_ "GenMsgSendType" BO_ 1289 1;
BA_ "NmMessage" BO_ 1289 1;
BA_ "GenMsgILSupport" BO_ 1289 0;
BA_ "GenMsgCycleTime" BO_ 1098 50;
BA_ "GenMsgSendType" BO_ 1098 0;
BA_ "GenMsgSendType" BO_ 1326 1;
BA_ "NmMessage" BO_ 1326 1;
BA_ "GenMsgILSupport" BO_ 1326 0;
BA_ "GenMsgSendType" BO_ 1325 1;
BA_ "NmMessage" BO_ 1325 1;
BA_ "GenMsgILSupport" BO_ 1325 0;
BA_ "NetworkInitialization" BO_ 1802 0;
BA_ "GenMsgDelayTime" BO_ 1802 0;
BA_ "GenMsgSendType" BO_ 1802 1;
BA_ "DiagResponse" BO_ 1802 1;
BA_ "GenMsgILSupport" BO_ 1802 0;
BA_ "GenMsgSendType" BO_ 1385 1;
BA_ "NmMessage" BO_ 1385 1;
BA_ "GenMsgILSupport" BO_ 1385 0;
BA_ "GenMsgSendType" BO_ 1306 1;
BA_ "NmMessage" BO_ 1306 1;
BA_ "GenMsgILSupport" BO_ 1306 0;
BA_ "GenMsgCycleTime" BO_ 1115 1000;
BA_ "GenMsgSendType" BO_ 1115 5;
BA_ "GenMsgCycleTime" BO_ 853 1000;
BA_ "GenMsgSendType" BO_ 853 5;
BA_ "FrameRouting" BO_ 1034 "HS1_CAN,0x40A;";
BA_ "FrameGatewayNetwork" BO_ 1034 "HS1_CAN";
BA_ "FrameGatewayId" BO_ 1034 1034;
BA_ "GenMsgCycleTime" BO_ 956 50;
BA_ "GenMsgSendType" BO_ 956 0;
BA_ "GenMsgStartDelayTime" BO_ 831 200;
BA_ "GenMsgCycleTime" BO_ 831 1000;
BA_ "GenMsgSendType" BO_ 831 5;
BA_ "NetworkInitialization" BO_ 1820 0;
BA_ "GenMsgDelayTime" BO_ 1820 0;
BA_ "GenMsgSendType" BO_ 1820 1;
BA_ "DiagResponse" BO_ 1820 1;
BA_ "GenMsgILSupport" BO_ 1820 0;
BA_ "NetworkInitialization" BO_ 1812 0;
BA_ "GenMsgDelayTime" BO_ 1812 0;
BA_ "GenMsgSendType" BO_ 1812 1;
BA_ "DiagRequest" BO_ 1812 1;
BA_ "GenMsgILSupport" BO_ 1812 0;
BA_ "GenMsgCycleTime" BO_ 787 1000;
BA_ "GenMsgSendType" BO_ 787 5;
BA_ "ECGUsedRxSignal" SG_ 2015 TesterFunctionalReq 1;
BA_ "U_CD764_MY2022_Rx" SG_ 2015 TesterFunctionalReq 1;
BA_ "U_CD542_MY2021_Rx" SG_ 2015 TesterFunctionalReq 1;
BA_ "U_T6_MCA_MY2020_Rx" SG_ 2015 TesterFunctionalReq 1;
BA_ "U_CX727_MY2021_Rx" SG_ 2015 TesterFunctionalReq 1;
BA_ "U_P702_MY2021_Rx" SG_ 2015 TesterFunctionalReq 1;
BA_ "U_U55X_MY2022_Rx" SG_ 2015 TesterFunctionalReq 1;
BA_ "GenSigSendType" SG_ 2015 TesterFunctionalReq 3;
BA_ "GenSigSendType" SG_ 806 ClimtCoolRear_B_Rq 3;
BA_ "GenSigSendType" SG_ 806 ClimtHeatRear_D_Rq 3;
BA_ "U_CD764_MY2022_Tx" SG_ 806 SnowPlowMde_B_Enbl 1;
BA_ "U_U55X_MY2022_Tx" SG_ 806 SnowPlowMde_B_Enbl 1;
BA_ "U_CD542_MY2021_Tx" SG_ 806 SnowPlowMde_B_Enbl 1;
BA_ "U_T6_MCA_MY2020_Tx" SG_ 806 SnowPlowMde_B_Enbl 1;
BA_ "U_P702_MY2021_Tx" SG_ 806 SnowPlowMde_B_Enbl 1;
BA_ "U_CD764_MY2022_Rx" SG_ 806 SnowPlowMde_B_Enbl 1;
BA_ "U_P702_MY2021_Rx" SG_ 806 SnowPlowMde_B_Enbl 1;
BA_ "U_U55X_MY2022_Rx" SG_ 806 SnowPlowMde_B_Enbl 1;
BA_ "U_CD764_MY2022_Tx" SG_ 806 ClimtDeltaLoad_Pw_Actl 1;
BA_ "U_U55X_MY2022_Tx" SG_ 806 ClimtDeltaLoad_Pw_Actl 1;
BA_ "U_CD542_MY2021_Tx" SG_ 806 ClimtDeltaLoad_Pw_Actl 1;
BA_ "U_T6_MCA_MY2020_Tx" SG_ 806 ClimtDeltaLoad_Pw_Actl 1;
BA_ "U_CX727_MY2021_Tx" SG_ 806 ClimtDeltaLoad_Pw_Actl 1;
BA_ "GenSigStartValueInteger" SG_ 806 ClimtDeltaLoad_Pw_Actl 32;
BA_ "U_CD764_MY2022_Tx" SG_ 806 StopStrtDrvMde_B_RqBtn 1;
BA_ "U_U55X_MY2022_Tx" SG_ 806 StopStrtDrvMde_B_RqBtn 1;
BA_ "U_CD542_MY2021_Tx" SG_ 806 StopStrtDrvMde_B_RqBtn 1;
BA_ "U_T6_MCA_MY2020_Tx" SG_ 806 StopStrtDrvMde_B_RqBtn 1;
BA_ "U_CX727_MY2021_Tx" SG_ 806 StopStrtDrvMde_B_RqBtn 1;
BA_ "U_CD764_MY2022_Tx" SG_ 806 HvacHtrCore_Te_Rq 1;
BA_ "U_U55X_MY2022_Tx" SG_ 806 HvacHtrCore_Te_Rq 1;
BA_ "U_CD542_MY2021_Tx" SG_ 806 HvacHtrCore_Te_Rq 1;
BA_ "U_T6_MCA_MY2020_Tx" SG_ 806 HvacHtrCore_Te_Rq 1;
BA_ "U_CX727_MY2021_Tx" SG_ 806 HvacHtrCore_Te_Rq 1;
BA_ "U_CD764_MY2022_Tx" SG_ 806 WndwFrontHeat_B_Stat 1;
BA_ "U_U55X_MY2022_Tx" SG_ 806 WndwFrontHeat_B_Stat 1;
BA_ "U_CD542_MY2021_Tx" SG_ 806 WndwFrontHeat_B_Stat 1;
BA_ "U_T6_MCA_MY2020_Tx" SG_ 806 WndwFrontHeat_B_Stat 1;
BA_ "U_CX727_MY2021_Tx" SG_ 806 WndwFrontHeat_B_Stat 1;
BA_ "U_CX727_MY2021_Tx" SG_ 806 HtrCorePump_B_Rq 1;
BA_ "U_CD764_MY2022_Tx" SG_ 806 ClimtHeat_D_Rq 1;
BA_ "U_U55X_MY2022_Tx" SG_ 806 ClimtHeat_D_Rq 1;
BA_ "U_CD542_MY2021_Tx" SG_ 806 ClimtHeat_D_Rq 1;
BA_ "U_T6_MCA_MY2020_Tx" SG_ 806 ClimtHeat_D_Rq 1;
BA_ "U_P702_MY2021_Tx" SG_ 806 ClimtHeat_D_Rq 1;
BA_ "U_CX727_MY2021_Tx" SG_ 806 ClimtHeat_D_Rq 1;
BA_ "U_CD764_MY2022_Tx" SG_ 806 ClimtCool_D_Rq 1;
BA_ "U_U55X_MY2022_Tx" SG_ 806 ClimtCool_D_Rq 1;
BA_ "U_CD542_MY2021_Tx" SG_ 806 ClimtCool_D_Rq 1;
BA_ "U_T6_MCA_MY2020_Tx" SG_ 806 ClimtCool_D_Rq 1;
BA_ "U_P702_MY2021_Tx" SG_ 806 ClimtCool_D_Rq 1;
BA_ "U_CX727_MY2021_Tx" SG_ 806 ClimtCool_D_Rq 1;
BA_ "U_CD764_MY2022_Tx" SG_ 806 HvacEvap_Te_Rq 1;
BA_ "U_U55X_MY2022_Tx" SG_ 806 HvacEvap_Te_Rq 1;
BA_ "U_CD542_MY2021_Tx" SG_ 806 HvacEvap_Te_Rq 1;
BA_ "U_T6_MCA_MY2020_Tx" SG_ 806 HvacEvap_Te_Rq 1;
BA_ "U_P702_MY2021_Tx" SG_ 806 HvacEvap_Te_Rq 1;
BA_ "U_CX727_MY2021_Tx" SG_ 806 HvacEvap_Te_Rq 1;
BA_ "GenSigStartValueInteger" SG_ 806 HvacEvap_Te_Rq 400;
BA_ "U_CD764_MY2022_Tx" SG_ 806 HvacEvap_Te_Actl 1;
BA_ "U_U55X_MY2022_Tx" SG_ 806 HvacEvap_Te_Actl 1;
BA_ "U_CD542_MY2021_Tx" SG_ 806 HvacEvap_Te_Actl 1;
BA_ "U_T6_MCA_MY2020_Tx" SG_ 806 HvacEvap_Te_Actl 1;
BA_ "U_P702_MY2021_Tx" SG_ 806 HvacEvap_Te_Actl 1;
BA_ "U_CX727_MY2021_Tx" SG_ 806 HvacEvap_Te_Actl 1;
BA_ "GenSigStartValueInteger" SG_ 806 HvacEvap_Te_Actl 400;
BA_ "U_CD764_MY2022_Tx" SG_ 806 HvacAirCond_B_Rq 1;
BA_ "U_U55X_MY2022_Tx" SG_ 806 HvacAirCond_B_Rq 1;
BA_ "U_CD542_MY2021_Tx" SG_ 806 HvacAirCond_B_Rq 1;
BA_ "U_T6_MCA_MY2020_Tx" SG_ 806 HvacAirCond_B_Rq 1;
BA_ "U_P702_MY2021_Tx" SG_ 806 HvacAirCond_B_Rq 1;
BA_ "U_CX727_MY2021_Tx" SG_ 806 HvacAirCond_B_Rq 1;
BA_ "U_CD764_MY2022_Tx" SG_ 806 HvacEvap_Te_Offst 1;
BA_ "U_U55X_MY2022_Tx" SG_ 806 HvacEvap_Te_Offst 1;
BA_ "U_CD542_MY2021_Tx" SG_ 806 HvacEvap_Te_Offst 1;
BA_ "U_T6_MCA_MY2020_Tx" SG_ 806 HvacEvap_Te_Offst 1;
BA_ "U_P702_MY2021_Tx" SG_ 806 HvacEvap_Te_Offst 1;
BA_ "U_CX727_MY2021_Tx" SG_ 806 HvacEvap_Te_Offst 1;
BA_ "GenSigStartValueInteger" SG_ 806 HvacEvap_Te_Offst 400;
BA_ "U_CD764_MY2022_Tx" SG_ 806 ClimtPw_B_Rq 1;
BA_ "U_U55X_MY2022_Tx" SG_ 806 ClimtPw_B_Rq 1;
BA_ "U_CD542_MY2021_Tx" SG_ 806 ClimtPw_B_Rq 1;
BA_ "U_T6_MCA_MY2020_Tx" SG_ 806 ClimtPw_B_Rq 1;
BA_ "U_CX727_MY2021_Tx" SG_ 806 ClimtPw_B_Rq 1;
BA_ "U_U55X_MY2022_Rx" SG_ 950 RemoteKey_Info_TIC 1;
BA_ "U_T6_MCA_MY2020_Rx" SG_ 950 RemoteKey_Info_TIC 1;
BA_ "U_P702_MY2021_Rx" SG_ 950 RemoteKey_Info_TIC 1;
BA_ "U_CX727_MY2021_Rx" SG_ 950 RemoteKey_Info_TIC 1;
BA_ "U_U55X_MY2022_Rx" SG_ 950 RemoteKey_Info_MaxInd 1;
BA_ "U_T6_MCA_MY2020_Rx" SG_ 950 RemoteKey_Info_MaxInd 1;
BA_ "U_P702_MY2021_Rx" SG_ 950 RemoteKey_Info_MaxInd 1;
BA_ "U_CX727_MY2021_Rx" SG_ 950 RemoteKey_Info_MaxInd 1;
BA_ "U_U55X_MY2022_Rx" SG_ 950 RemoteKey_Info_Index 1;
BA_ "U_T6_MCA_MY2020_Rx" SG_ 950 RemoteKey_Info_Index 1;
BA_ "U_P702_MY2021_Rx" SG_ 950 RemoteKey_Info_Index 1;
BA_ "U_CX727_MY2021_Rx" SG_ 950 RemoteKey_Info_Index 1;
BA_ "U_U55X_MY2022_Rx" SG_ 950 TirePress_Filter_Ctrl 1;
BA_ "U_T6_MCA_MY2020_Rx" SG_ 950 TirePress_Filter_Ctrl 1;
BA_ "U_P702_MY2021_Rx" SG_ 950 TirePress_Filter_Ctrl 1;
BA_ "U_CX727_MY2021_Rx" SG_ 950 TirePress_Filter_Ctrl 1;
BA_ "GenSigStartValue" SG_ 950 TirePress_Filter_Ctrl 2;
BA_ "GenSigStartValueInteger" SG_ 950 TirePress_Filter_Ctrl 2;
BA_ "U_CD764_MY2022_Rx" SG_ 857 LHS_Temp_Disp_Digit3 1;
BA_ "U_U55X_MY2022_Rx" SG_ 857 LHS_Temp_Disp_Digit3 1;
BA_ "U_CD542_MY2021_Rx" SG_ 857 LHS_Temp_Disp_Digit3 1;
BA_ "U_T6_MCA_MY2020_Rx" SG_ 857 LHS_Temp_Disp_Digit3 1;
BA_ "U_CX727_MY2021_Rx" SG_ 857 LHS_Temp_Disp_Digit3 1;
BA_ "U_CD764_MY2022_Rx" SG_ 857 LHS_Temp_Disp_Digit2 1;
BA_ "U_U55X_MY2022_Rx" SG_ 857 LHS_Temp_Disp_Digit2 1;
BA_ "U_CD542_MY2021_Rx" SG_ 857 LHS_Temp_Disp_Digit2 1;
BA_ "U_T6_MCA_MY2020_Rx" SG_ 857 LHS_Temp_Disp_Digit2 1;
BA_ "U_CX727_MY2021_Rx" SG_ 857 LHS_Temp_Disp_Digit2 1;
BA_ "U_CD764_MY2022_Rx" SG_ 857 LHS_Temp_Disp_Digit1 1;
BA_ "U_U55X_MY2022_Rx" SG_ 857 LHS_Temp_Disp_Digit1 1;
BA_ "U_CD542_MY2021_Rx" SG_ 857 LHS_Temp_Disp_Digit1 1;
BA_ "U_T6_MCA_MY2020_Rx" SG_ 857 LHS_Temp_Disp_Digit1 1;
BA_ "U_CX727_MY2021_Rx" SG_ 857 LHS_Temp_Disp_Digit1 1;
BA_ "U_CD764_MY2022_Rx" SG_ 857 Front_Blower_Ind 1;
BA_ "U_U55X_MY2022_Rx" SG_ 857 Front_Blower_Ind 1;
BA_ "U_CD542_MY2021_Rx" SG_ 857 Front_Blower_Ind 1;
BA_ "U_T6_MCA_MY2020_Rx" SG_ 857 Front_Blower_Ind 1;
BA_ "U_CX727_MY2021_Rx" SG_ 857 Front_Blower_Ind 1;
BA_ "GenSigStartValue" SG_ 857 Front_Blower_Ind 15;
BA_ "GenSigStartValueInteger" SG_ 857 Front_Blower_Ind 15;
BA_ "U_CD764_MY2022_Rx" SG_ 857 EATC_LHS_Unit 1;
BA_ "U_U55X_MY2022_Rx" SG_ 857 EATC_LHS_Unit 1;
BA_ "U_CD542_MY2021_Rx" SG_ 857 EATC_LHS_Unit 1;
BA_ "U_T6_MCA_MY2020_Rx" SG_ 857 EATC_LHS_Unit 1;
BA_ "U_CX727_MY2021_Rx" SG_ 857 EATC_LHS_Unit 1;
BA_ "U_CD764_MY2022_Rx" SG_ 856 Frt_Blower_Speed2 1;
BA_ "U_U55X_MY2022_Rx" SG_ 856 Frt_Blower_Speed2 1;
BA_ "U_CD542_MY2021_Rx" SG_ 856 Frt_Blower_Speed2 1;
BA_ "U_T6_MCA_MY2020_Rx" SG_ 856 Frt_Blower_Speed2 1;
BA_ "U_CD764_MY2022_Rx" SG_ 856 Psngr_Set_Temp 1;
BA_ "U_U55X_MY2022_Rx" SG_ 856 Psngr_Set_Temp 1;
BA_ "U_CD542_MY2021_Rx" SG_ 856 Psngr_Set_Temp 1;
BA_ "U_T6_MCA_MY2020_Rx" SG_ 856 Psngr_Set_Temp 1;
BA_ "U_CD764_MY2022_Rx" SG_ 856 SnowPlowOn_B_Rq 1;
BA_ "U_U55X_MY2022_Rx" SG_ 856 SnowPlowOn_B_Rq 1;
BA_ "U_CD542_MY2021_Rx" SG_ 856 SnowPlowOn_B_Rq 1;
BA_ "U_T6_MCA_MY2020_Rx" SG_ 856 SnowPlowOn_B_Rq 1;
BA_ "U_CD764_MY2022_Rx" SG_ 856 Rr_Btn_Status_2nd 1;
BA_ "U_U55X_MY2022_Rx" SG_ 856 Rr_Btn_Status_2nd 1;
BA_ "U_CD542_MY2021_Rx" SG_ 856 Rr_Btn_Status_2nd 1;
BA_ "U_T6_MCA_MY2020_Rx" SG_ 856 Rr_Btn_Status_2nd 1;
BA_ "U_CD764_MY2022_Rx" SG_ 856 Rr_Btn_Status_1st 1;
BA_ "U_U55X_MY2022_Rx" SG_ 856 Rr_Btn_Status_1st 1;
BA_ "U_CD542_MY2021_Rx" SG_ 856 Rr_Btn_Status_1st 1;
BA_ "U_T6_MCA_MY2020_Rx" SG_ 856 Rr_Btn_Status_1st 1;
BA_ "U_CD764_MY2022_Rx" SG_ 856 Frt_Btn_Status_2nd 1;
BA_ "U_U55X_MY2022_Rx" SG_ 856 Frt_Btn_Status_2nd 1;
BA_ "U_CD542_MY2021_Rx" SG_ 856 Frt_Btn_Status_2nd 1;
BA_ "U_T6_MCA_MY2020_Rx" SG_ 856 Frt_Btn_Status_2nd 1;
BA_ "U_P702_MY2021_Rx" SG_ 856 Frt_Btn_Status_2nd 1;
BA_ "U_CX727_MY2021_Rx" SG_ 856 Frt_Btn_Status_2nd 1;
BA_ "U_CD764_MY2022_Rx" SG_ 856 Frt_Btn_Status_1st 1;
BA_ "U_U55X_MY2022_Rx" SG_ 856 Frt_Btn_Status_1st 1;
BA_ "U_CD542_MY2021_Rx" SG_ 856 Frt_Btn_Status_1st 1;
BA_ "U_T6_MCA_MY2020_Rx" SG_ 856 Frt_Btn_Status_1st 1;
BA_ "U_P702_MY2021_Rx" SG_ 856 Frt_Btn_Status_1st 1;
BA_ "U_CX727_MY2021_Rx" SG_ 856 Frt_Btn_Status_1st 1;
BA_ "U_CD764_MY2022_Rx" SG_ 856 Frt_Blower_Speed 1;
BA_ "U_U55X_MY2022_Rx" SG_ 856 Frt_Blower_Speed 1;
BA_ "U_CD542_MY2021_Rx" SG_ 856 Frt_Blower_Speed 1;
BA_ "U_T6_MCA_MY2020_Rx" SG_ 856 Frt_Blower_Speed 1;
BA_ "U_P702_MY2021_Rx" SG_ 856 Frt_Blower_Speed 1;
BA_ "U_CX727_MY2021_Rx" SG_ 856 Frt_Blower_Speed 1;
BA_ "U_CD764_MY2022_Rx" SG_ 856 Drv_Set_Temp 1;
BA_ "U_U55X_MY2022_Rx" SG_ 856 Drv_Set_Temp 1;
BA_ "U_CD542_MY2021_Rx" SG_ 856 Drv_Set_Temp 1;
BA_ "U_T6_MCA_MY2020_Rx" SG_ 856 Drv_Set_Temp 1;
BA_ "U_P702_MY2021_Rx" SG_ 856 Drv_Set_Temp 1;
BA_ "U_CX727_MY2021_Rx" SG_ 856 Drv_Set_Temp 1;
BA_ "U_T6_MCA_MY2020_Tx" SG_ 855 Rr_Temp_Detents 1;
BA_ "U_U55X_MY2022_Tx" SG_ 855 Rr_Temp_Detents 1;
BA_ "U_CD542_MY2021_Tx" SG_ 855 Rr_Temp_Detents 1;
BA_ "U_U55X_MY2022_Rx" SG_ 855 Rr_Temp_Detents 1;
BA_ "U_T6_MCA_MY2020_Rx" SG_ 855 Rr_Temp_Detents 1;
BA_ "GenSigSendType" SG_ 855 Rr_Temp_Detents 3;
BA_ "U_T6_MCA_MY2020_Tx" SG_ 855 Rr_Power_Btn_Stt 1;
BA_ "U_U55X_MY2022_Tx" SG_ 855 Rr_Power_Btn_Stt 1;
BA_ "U_CD542_MY2021_Tx" SG_ 855 Rr_Power_Btn_Stt 1;
BA_ "U_U55X_MY2022_Rx" SG_ 855 Rr_Power_Btn_Stt 1;
BA_ "U_T6_MCA_MY2020_Rx" SG_ 855 Rr_Power_Btn_Stt 1;
BA_ "GenSigSendType" SG_ 855 Rr_Power_Btn_Stt 3;
BA_ "GenSigStartValue" SG_ 855 Rr_Power_Btn_Stt 2;
BA_ "GenSigStartValueInteger" SG_ 855 Rr_Power_Btn_Stt 2;
BA_ "U_T6_MCA_MY2020_Tx" SG_ 855 Rr_RH_Cond_Seat_Stat 1;
BA_ "U_U55X_MY2022_Tx" SG_ 855 Rr_RH_Cond_Seat_Stat 1;
BA_ "U_CD542_MY2021_Tx" SG_ 855 Rr_RH_Cond_Seat_Stat 1;
BA_ "U_U55X_MY2022_Rx" SG_ 855 Rr_RH_Cond_Seat_Stat 1;
BA_ "U_T6_MCA_MY2020_Rx" SG_ 855 Rr_RH_Cond_Seat_Stat 1;
BA_ "GenSigSendType" SG_ 855 Rr_RH_Cond_Seat_Stat 3;
BA_ "U_T6_MCA_MY2020_Tx" SG_ 855 Rr_Pnl_Flr_Btn_Stt 1;
BA_ "U_U55X_MY2022_Tx" SG_ 855 Rr_Pnl_Flr_Btn_Stt 1;
BA_ "U_CD542_MY2021_Tx" SG_ 855 Rr_Pnl_Flr_Btn_Stt 1;
BA_ "U_U55X_MY2022_Rx" SG_ 855 Rr_Pnl_Flr_Btn_Stt 1;
BA_ "U_T6_MCA_MY2020_Rx" SG_ 855 Rr_Pnl_Flr_Btn_Stt 1;
BA_ "GenSigSendType" SG_ 855 Rr_Pnl_Flr_Btn_Stt 3;
BA_ "GenSigStartValue" SG_ 855 Rr_Pnl_Flr_Btn_Stt 2;
BA_ "GenSigStartValueInteger" SG_ 855 Rr_Pnl_Flr_Btn_Stt 2;
BA_ "U_T6_MCA_MY2020_Tx" SG_ 855 Rr_LH_Cond_Seat_Stat 1;
BA_ "U_U55X_MY2022_Tx" SG_ 855 Rr_LH_Cond_Seat_Stat 1;
BA_ "U_CD542_MY2021_Tx" SG_ 855 Rr_LH_Cond_Seat_Stat 1;
BA_ "U_U55X_MY2022_Rx" SG_ 855 Rr_LH_Cond_Seat_Stat 1;
BA_ "U_T6_MCA_MY2020_Rx" SG_ 855 Rr_LH_Cond_Seat_Stat 1;
BA_ "GenSigSendType" SG_ 855 Rr_LH_Cond_Seat_Stat 3;
BA_ "U_T6_MCA_MY2020_Tx" SG_ 855 CC_Rr_Stat_User_Adj 1;
BA_ "U_U55X_MY2022_Tx" SG_ 855 CC_Rr_Stat_User_Adj 1;
BA_ "U_CD542_MY2021_Tx" SG_ 855 CC_Rr_Stat_User_Adj 1;
BA_ "U_U55X_MY2022_Rx" SG_ 855 CC_Rr_Stat_User_Adj 1;
BA_ "U_T6_MCA_MY2020_Rx" SG_ 855 CC_Rr_Stat_User_Adj 1;
BA_ "GenSigSendType" SG_ 855 CC_Rr_Stat_User_Adj 3;
BA_ "U_T6_MCA_MY2020_Tx" SG_ 855 Rr_Set_Temp_Units 1;
BA_ "U_U55X_MY2022_Tx" SG_ 855 Rr_Set_Temp_Units 1;
BA_ "U_CD542_MY2021_Tx" SG_ 855 Rr_Set_Temp_Units 1;
BA_ "U_U55X_MY2022_Rx" SG_ 855 Rr_Set_Temp_Units 1;
BA_ "U_T6_MCA_MY2020_Rx" SG_ 855 Rr_Set_Temp_Units 1;
BA_ "GenSigSendType" SG_ 855 Rr_Set_Temp_Units 3;
BA_ "GenSigStartValue" SG_ 855 Rr_Set_Temp_Units 2;
BA_ "GenSigStartValueInteger" SG_ 855 Rr_Set_Temp_Units 2;
BA_ "U_T6_MCA_MY2020_Tx" SG_ 855 Rr_RHS_Set_Temp_Dig3 1;
BA_ "U_U55X_MY2022_Tx" SG_ 855 Rr_RHS_Set_Temp_Dig3 1;
BA_ "U_CD542_MY2021_Tx" SG_ 855 Rr_RHS_Set_Temp_Dig3 1;
BA_ "U_U55X_MY2022_Rx" SG_ 855 Rr_RHS_Set_Temp_Dig3 1;
BA_ "GenSigSendType" SG_ 855 Rr_RHS_Set_Temp_Dig3 3;
BA_ "GenSigStartValue" SG_ 855 Rr_RHS_Set_Temp_Dig3 2;
BA_ "GenSigStartValueInteger" SG_ 855 Rr_RHS_Set_Temp_Dig3 2;
BA_ "U_T6_MCA_MY2020_Tx" SG_ 855 Rr_RHS_Set_Temp_Dig2 1;
BA_ "U_U55X_MY2022_Tx" SG_ 855 Rr_RHS_Set_Temp_Dig2 1;
BA_ "U_CD542_MY2021_Tx" SG_ 855 Rr_RHS_Set_Temp_Dig2 1;
BA_ "U_U55X_MY2022_Rx" SG_ 855 Rr_RHS_Set_Temp_Dig2 1;
BA_ "GenSigSendType" SG_ 855 Rr_RHS_Set_Temp_Dig2 3;
BA_ "GenSigStartValue" SG_ 855 Rr_RHS_Set_Temp_Dig2 15;
BA_ "GenSigStartValueInteger" SG_ 855 Rr_RHS_Set_Temp_Dig2 15;
BA_ "U_T6_MCA_MY2020_Tx" SG_ 855 Rr_RHS_Set_Temp_Dig1 1;
BA_ "U_U55X_MY2022_Tx" SG_ 855 Rr_RHS_Set_Temp_Dig1 1;
BA_ "U_CD542_MY2021_Tx" SG_ 855 Rr_RHS_Set_Temp_Dig1 1;
BA_ "U_U55X_MY2022_Rx" SG_ 855 Rr_RHS_Set_Temp_Dig1 1;
BA_ "GenSigSendType" SG_ 855 Rr_RHS_Set_Temp_Dig1 3;
BA_ "GenSigStartValue" SG_ 855 Rr_RHS_Set_Temp_Dig1 15;
BA_ "GenSigStartValueInteger" SG_ 855 Rr_RHS_Set_Temp_Dig1 15;
BA_ "U_T6_MCA_MY2020_Tx" SG_ 855 Rr_RH_Htd_Seat_Btn_Stt 1;
BA_ "U_U55X_MY2022_Tx" SG_ 855 Rr_RH_Htd_Seat_Btn_Stt 1;
BA_ "U_CD542_MY2021_Tx" SG_ 855 Rr_RH_Htd_Seat_Btn_Stt 1;
BA_ "U_U55X_MY2022_Rx" SG_ 855 Rr_RH_Htd_Seat_Btn_Stt 1;
BA_ "U_T6_MCA_MY2020_Rx" SG_ 855 Rr_RH_Htd_Seat_Btn_Stt 1;
BA_ "GenSigSendType" SG_ 855 Rr_RH_Htd_Seat_Btn_Stt 3;
BA_ "GenSigStartValue" SG_ 855 Rr_RH_Htd_Seat_Btn_Stt 2;
BA_ "GenSigStartValueInteger" SG_ 855 Rr_RH_Htd_Seat_Btn_Stt 2;
BA_ "U_T6_MCA_MY2020_Tx" SG_ 855 Rr_RH_Cld_Seat_Btn_Stt 1;
BA_ "U_U55X_MY2022_Tx" SG_ 855 Rr_RH_Cld_Seat_Btn_Stt 1;
BA_ "U_CD542_MY2021_Tx" SG_ 855 Rr_RH_Cld_Seat_Btn_Stt 1;
BA_ "U_U55X_MY2022_Rx" SG_ 855 Rr_RH_Cld_Seat_Btn_Stt 1;
BA_ "GenSigSendType" SG_ 855 Rr_RH_Cld_Seat_Btn_Stt 3;
BA_ "GenSigStartValue" SG_ 855 Rr_RH_Cld_Seat_Btn_Stt 2;
BA_ "GenSigStartValueInteger" SG_ 855 Rr_RH_Cld_Seat_Btn_Stt 2;
BA_ "U_T6_MCA_MY2020_Tx" SG_ 855 Rr_Panel_Btn_Stt 1;
BA_ "U_U55X_MY2022_Tx" SG_ 855 Rr_Panel_Btn_Stt 1;
BA_ "U_CD542_MY2021_Tx" SG_ 855 Rr_Panel_Btn_Stt 1;
BA_ "U_U55X_MY2022_Rx" SG_ 855 Rr_Panel_Btn_Stt 1;
BA_ "U_T6_MCA_MY2020_Rx" SG_ 855 Rr_Panel_Btn_Stt 1;
BA_ "GenSigSendType" SG_ 855 Rr_Panel_Btn_Stt 3;
BA_ "GenSigStartValue" SG_ 855 Rr_Panel_Btn_Stt 2;
BA_ "GenSigStartValueInteger" SG_ 855 Rr_Panel_Btn_Stt 2;
BA_ "U_T6_MCA_MY2020_Tx" SG_ 855 Rr_On_Indicator 1;
BA_ "U_U55X_MY2022_Tx" SG_ 855 Rr_On_Indicator 1;
BA_ "U_CD542_MY2021_Tx" SG_ 855 Rr_On_Indicator 1;
BA_ "U_U55X_MY2022_Rx" SG_ 855 Rr_On_Indicator 1;
BA_ "U_T6_MCA_MY2020_Rx" SG_ 855 Rr_On_Indicator 1;
BA_ "GenSigSendType" SG_ 855 Rr_On_Indicator 3;
BA_ "U_T6_MCA_MY2020_Tx" SG_ 855 Rr_LHS_Set_Temp_Dig3 1;
BA_ "U_U55X_MY2022_Tx" SG_ 855 Rr_LHS_Set_Temp_Dig3 1;
BA_ "U_CD542_MY2021_Tx" SG_ 855 Rr_LHS_Set_Temp_Dig3 1;
BA_ "U_U55X_MY2022_Rx" SG_ 855 Rr_LHS_Set_Temp_Dig3 1;
BA_ "GenSigSendType" SG_ 855 Rr_LHS_Set_Temp_Dig3 3;
BA_ "GenSigStartValue" SG_ 855 Rr_LHS_Set_Temp_Dig3 2;
BA_ "GenSigStartValueInteger" SG_ 855 Rr_LHS_Set_Temp_Dig3 2;
BA_ "U_T6_MCA_MY2020_Tx" SG_ 855 Rr_LHS_Set_Temp_Dig2 1;
BA_ "U_U55X_MY2022_Tx" SG_ 855 Rr_LHS_Set_Temp_Dig2 1;
BA_ "U_CD542_MY2021_Tx" SG_ 855 Rr_LHS_Set_Temp_Dig2 1;
BA_ "U_U55X_MY2022_Rx" SG_ 855 Rr_LHS_Set_Temp_Dig2 1;
BA_ "GenSigSendType" SG_ 855 Rr_LHS_Set_Temp_Dig2 3;
BA_ "GenSigStartValue" SG_ 855 Rr_LHS_Set_Temp_Dig2 15;
BA_ "GenSigStartValueInteger" SG_ 855 Rr_LHS_Set_Temp_Dig2 15;
BA_ "U_U55X_MY2022_Tx" SG_ 855 Rr_LHS_Set_Temp_Dig1 1;
BA_ "U_CD542_MY2021_Tx" SG_ 855 Rr_LHS_Set_Temp_Dig1 1;
BA_ "U_T6_MCA_MY2020_Tx" SG_ 855 Rr_LHS_Set_Temp_Dig1 1;
BA_ "U_U55X_MY2022_Rx" SG_ 855 Rr_LHS_Set_Temp_Dig1 1;
BA_ "GenSigSendType" SG_ 855 Rr_LHS_Set_Temp_Dig1 3;
BA_ "GenSigStartValue" SG_ 855 Rr_LHS_Set_Temp_Dig1 15;
BA_ "GenSigStartValueInteger" SG_ 855 Rr_LHS_Set_Temp_Dig1 15;
BA_ "U_T6_MCA_MY2020_Tx" SG_ 855 Rr_LH_Htd_Seat_Btn_Stt 1;
BA_ "U_U55X_MY2022_Tx" SG_ 855 Rr_LH_Htd_Seat_Btn_Stt 1;
BA_ "U_CD542_MY2021_Tx" SG_ 855 Rr_LH_Htd_Seat_Btn_Stt 1;
BA_ "U_U55X_MY2022_Rx" SG_ 855 Rr_LH_Htd_Seat_Btn_Stt 1;
BA_ "U_T6_MCA_MY2020_Rx" SG_ 855 Rr_LH_Htd_Seat_Btn_Stt 1;
BA_ "GenSigSendType" SG_ 855 Rr_LH_Htd_Seat_Btn_Stt 3;
BA_ "GenSigStartValue" SG_ 855 Rr_LH_Htd_Seat_Btn_Stt 2;
BA_ "GenSigStartValueInteger" SG_ 855 Rr_LH_Htd_Seat_Btn_Stt 2;
BA_ "U_T6_MCA_MY2020_Tx" SG_ 855 Rr_LH_Cld_Seat_Btn_Stt 1;
BA_ "U_U55X_MY2022_Tx" SG_ 855 Rr_LH_Cld_Seat_Btn_Stt 1;
BA_ "U_CD542_MY2021_Tx" SG_ 855 Rr_LH_Cld_Seat_Btn_Stt 1;
BA_ "U_U55X_MY2022_Rx" SG_ 855 Rr_LH_Cld_Seat_Btn_Stt 1;
BA_ "GenSigSendType" SG_ 855 Rr_LH_Cld_Seat_Btn_Stt 3;
BA_ "GenSigStartValue" SG_ 855 Rr_LH_Cld_Seat_Btn_Stt 2;
BA_ "GenSigStartValueInteger" SG_ 855 Rr_LH_Cld_Seat_Btn_Stt 2;
BA_ "U_T6_MCA_MY2020_Tx" SG_ 855 Rr_Floor_Btn_Stt 1;
BA_ "U_U55X_MY2022_Tx" SG_ 855 Rr_Floor_Btn_Stt 1;
BA_ "U_CD542_MY2021_Tx" SG_ 855 Rr_Floor_Btn_Stt 1;
BA_ "U_U55X_MY2022_Rx" SG_ 855 Rr_Floor_Btn_Stt 1;
BA_ "U_T6_MCA_MY2020_Rx" SG_ 855 Rr_Floor_Btn_Stt 1;
BA_ "GenSigSendType" SG_ 855 Rr_Floor_Btn_Stt 3;
BA_ "GenSigStartValue" SG_ 855 Rr_Floor_Btn_Stt 2;
BA_ "GenSigStartValueInteger" SG_ 855 Rr_Floor_Btn_Stt 2;
BA_ "U_T6_MCA_MY2020_Tx" SG_ 855 Rr_Control_Btn_Stt 1;
BA_ "U_U55X_MY2022_Tx" SG_ 855 Rr_Control_Btn_Stt 1;
BA_ "U_CD542_MY2021_Tx" SG_ 855 Rr_Control_Btn_Stt 1;
BA_ "U_U55X_MY2022_Rx" SG_ 855 Rr_Control_Btn_Stt 1;
BA_ "U_T6_MCA_MY2020_Rx" SG_ 855 Rr_Control_Btn_Stt 1;
BA_ "GenSigSendType" SG_ 855 Rr_Control_Btn_Stt 3;
BA_ "GenSigStartValue" SG_ 855 Rr_Control_Btn_Stt 2;
BA_ "GenSigStartValueInteger" SG_ 855 Rr_Control_Btn_Stt 2;
BA_ "U_T6_MCA_MY2020_Tx" SG_ 855 Rr_Blower_Indicate 1;
BA_ "U_U55X_MY2022_Tx" SG_ 855 Rr_Blower_Indicate 1;
BA_ "U_CD542_MY2021_Tx" SG_ 855 Rr_Blower_Indicate 1;
BA_ "U_U55X_MY2022_Rx" SG_ 855 Rr_Blower_Indicate 1;
BA_ "U_T6_MCA_MY2020_Rx" SG_ 855 Rr_Blower_Indicate 1;
BA_ "GenSigSendType" SG_ 855 Rr_Blower_Indicate 3;
BA_ "GenSigStartValue" SG_ 855 Rr_Blower_Indicate 15;
BA_ "GenSigStartValueInteger" SG_ 855 Rr_Blower_Indicate 15;
BA_ "U_T6_MCA_MY2020_Tx" SG_ 855 Rr_AUTO_Btn_Stt 1;
BA_ "U_U55X_MY2022_Tx" SG_ 855 Rr_AUTO_Btn_Stt 1;
BA_ "U_CD542_MY2021_Tx" SG_ 855 Rr_AUTO_Btn_Stt 1;
BA_ "U_U55X_MY2022_Rx" SG_ 855 Rr_AUTO_Btn_Stt 1;
BA_ "GenSigSendType" SG_ 855 Rr_AUTO_Btn_Stt 3;
BA_ "GenSigStartValue" SG_ 855 Rr_AUTO_Btn_Stt 2;
BA_ "GenSigStartValueInteger" SG_ 855 Rr_AUTO_Btn_Stt 2;
BA_ "GenSigSendType" SG_ 854 Dsp_RotAddrBtnEv_St 3;
BA_ "GenSigStartValue" SG_ 854 Dsp_RotAddrBtnEv_St 7;
BA_ "GenSigStartValueInteger" SG_ 854 Dsp_RotAddrBtnEv_St 7;
BA_ "U_U55X_MY2022_Tx" SG_ 854 SelDrvMdeButtn_B_Stat 1;
BA_ "U_CD542_MY2021_Tx" SG_ 854 SelDrvMdeButtn_B_Stat 1;
BA_ "U_T6_MCA_MY2020_Tx" SG_ 854 SelDrvMdeButtn_B_Stat 1;
BA_ "U_CX727_MY2021_Tx" SG_ 854 SelDrvMdeButtn_B_Stat 1;
BA_ "GenSigSendType" SG_ 854 SelDrvMdeButtn_B_Stat 3;
BA_ "U_T6_MCA_MY2020_Tx" SG_ 854 SteEffortButtn_B_Stat 1;
BA_ "GenSigSendType" SG_ 854 SteEffortButtn_B_Stat 3;
BA_ "U_CD764_MY2022_Tx" SG_ 854 LHS_Auto_Seat_Btn_Stt 1;
BA_ "U_CD542_MY2021_Tx" SG_ 854 LHS_Auto_Seat_Btn_Stt 1;
BA_ "U_U55X_MY2022_Tx" SG_ 854 LHS_Auto_Seat_Btn_Stt 1;
BA_ "U_T6_MCA_MY2020_Tx" SG_ 854 LHS_Auto_Seat_Btn_Stt 1;
BA_ "GenSigSendType" SG_ 854 LHS_Auto_Seat_Btn_Stt 3;
BA_ "GenSigStartValue" SG_ 854 LHS_Auto_Seat_Btn_Stt 2;
BA_ "U_CD764_MY2022_Tx" SG_ 854 RHS_Auto_Seat_Btn_Stt 1;
BA_ "U_CD542_MY2021_Tx" SG_ 854 RHS_Auto_Seat_Btn_Stt 1;
BA_ "U_U55X_MY2022_Tx" SG_ 854 RHS_Auto_Seat_Btn_Stt 1;
BA_ "U_T6_MCA_MY2020_Tx" SG_ 854 RHS_Auto_Seat_Btn_Stt 1;
BA_ "GenSigSendType" SG_ 854 RHS_Auto_Seat_Btn_Stt 3;
BA_ "GenSigStartValue" SG_ 854 RHS_Auto_Seat_Btn_Stt 2;
BA_ "U_U55X_MY2022_Tx" SG_ 854 SelDrvMdeSwtch_D_Stat2 1;
BA_ "U_CD542_MY2021_Tx" SG_ 854 SelDrvMdeSwtch_D_Stat2 1;
BA_ "U_T6_MCA_MY2020_Tx" SG_ 854 SelDrvMdeSwtch_D_Stat2 1;
BA_ "U_CX727_MY2021_Tx" SG_ 854 SelDrvMdeSwtch_D_Stat2 1;
BA_ "GenSigSendType" SG_ 854 SelDrvMdeSwtch_D_Stat2 3;
BA_ "U_CD764_MY2022_Tx" SG_ 854 CC_Fr_Stat_User_Adj 1;
BA_ "U_U55X_MY2022_Tx" SG_ 854 CC_Fr_Stat_User_Adj 1;
BA_ "U_CD542_MY2021_Tx" SG_ 854 CC_Fr_Stat_User_Adj 1;
BA_ "U_T6_MCA_MY2020_Tx" SG_ 854 CC_Fr_Stat_User_Adj 1;
BA_ "U_P702_MY2021_Tx" SG_ 854 CC_Fr_Stat_User_Adj 1;
BA_ "U_CX727_MY2021_Tx" SG_ 854 CC_Fr_Stat_User_Adj 1;
BA_ "GenSigSendType" SG_ 854 CC_Fr_Stat_User_Adj 3;
BA_ "GenSigSendType" SG_ 854 EngExhMdeQuiet_B_RqDrv 3;
BA_ "GenSigSendType" SG_ 854 LnchCtlSys_B_RqDrv 3;
BA_ "U_CD764_MY2022_Tx" SG_ 854 Front_Blower_Indicate 1;
BA_ "U_U55X_MY2022_Tx" SG_ 854 Front_Blower_Indicate 1;
BA_ "U_CD542_MY2021_Tx" SG_ 854 Front_Blower_Indicate 1;
BA_ "U_T6_MCA_MY2020_Tx" SG_ 854 Front_Blower_Indicate 1;
BA_ "U_P702_MY2021_Tx" SG_ 854 Front_Blower_Indicate 1;
BA_ "U_CX727_MY2021_Tx" SG_ 854 Front_Blower_Indicate 1;
BA_ "GenSigSendType" SG_ 854 Front_Blower_Indicate 3;
BA_ "GenSigStartValue" SG_ 854 Front_Blower_Indicate 15;
BA_ "GenSigStartValueInteger" SG_ 854 Front_Blower_Indicate 15;
BA_ "U_CD764_MY2022_Tx" SG_ 854 CC_Diagnostics_Active 1;
BA_ "U_U55X_MY2022_Tx" SG_ 854 CC_Diagnostics_Active 1;
BA_ "U_CD542_MY2021_Tx" SG_ 854 CC_Diagnostics_Active 1;
BA_ "U_T6_MCA_MY2020_Tx" SG_ 854 CC_Diagnostics_Active 1;
BA_ "U_P702_MY2021_Tx" SG_ 854 CC_Diagnostics_Active 1;
BA_ "U_CX727_MY2021_Tx" SG_ 854 CC_Diagnostics_Active 1;
BA_ "GenSigSendType" SG_ 854 CC_Diagnostics_Active 3;
BA_ "U_CD764_MY2022_Tx" SG_ 854 RHS_Temp_Display_Digit3 1;
BA_ "U_U55X_MY2022_Tx" SG_ 854 RHS_Temp_Display_Digit3 1;
BA_ "U_CD542_MY2021_Tx" SG_ 854 RHS_Temp_Display_Digit3 1;
BA_ "U_T6_MCA_MY2020_Tx" SG_ 854 RHS_Temp_Display_Digit3 1;
BA_ "U_P702_MY2021_Tx" SG_ 854 RHS_Temp_Display_Digit3 1;
BA_ "U_CX727_MY2021_Tx" SG_ 854 RHS_Temp_Display_Digit3 1;
BA_ "GenSigSendType" SG_ 854 RHS_Temp_Display_Digit3 3;
BA_ "U_CD764_MY2022_Tx" SG_ 854 RHS_Temp_Display_Digit2 1;
BA_ "U_U55X_MY2022_Tx" SG_ 854 RHS_Temp_Display_Digit2 1;
BA_ "U_CD542_MY2021_Tx" SG_ 854 RHS_Temp_Display_Digit2 1;
BA_ "U_T6_MCA_MY2020_Tx" SG_ 854 RHS_Temp_Display_Digit2 1;
BA_ "U_P702_MY2021_Tx" SG_ 854 RHS_Temp_Display_Digit2 1;
BA_ "U_CX727_MY2021_Tx" SG_ 854 RHS_Temp_Display_Digit2 1;
BA_ "GenSigSendType" SG_ 854 RHS_Temp_Display_Digit2 3;
BA_ "U_CD764_MY2022_Tx" SG_ 854 RHS_Temp_Display_Digit1 1;
BA_ "U_U55X_MY2022_Tx" SG_ 854 RHS_Temp_Display_Digit1 1;
BA_ "U_CD542_MY2021_Tx" SG_ 854 RHS_Temp_Display_Digit1 1;
BA_ "U_T6_MCA_MY2020_Tx" SG_ 854 RHS_Temp_Display_Digit1 1;
BA_ "U_P702_MY2021_Tx" SG_ 854 RHS_Temp_Display_Digit1 1;
BA_ "U_CX727_MY2021_Tx" SG_ 854 RHS_Temp_Display_Digit1 1;
BA_ "GenSigSendType" SG_ 854 RHS_Temp_Display_Digit1 3;
BA_ "U_CD764_MY2022_Tx" SG_ 854 LHS_Temp_Display_Digit3 1;
BA_ "U_U55X_MY2022_Tx" SG_ 854 LHS_Temp_Display_Digit3 1;
BA_ "U_CD542_MY2021_Tx" SG_ 854 LHS_Temp_Display_Digit3 1;
BA_ "U_T6_MCA_MY2020_Tx" SG_ 854 LHS_Temp_Display_Digit3 1;
BA_ "U_P702_MY2021_Tx" SG_ 854 LHS_Temp_Display_Digit3 1;
BA_ "U_CX727_MY2021_Tx" SG_ 854 LHS_Temp_Display_Digit3 1;
BA_ "GenSigSendType" SG_ 854 LHS_Temp_Display_Digit3 3;
BA_ "U_CD764_MY2022_Tx" SG_ 854 LHS_Temp_Display_Digit2 1;
BA_ "U_U55X_MY2022_Tx" SG_ 854 LHS_Temp_Display_Digit2 1;
BA_ "U_CD542_MY2021_Tx" SG_ 854 LHS_Temp_Display_Digit2 1;
BA_ "U_T6_MCA_MY2020_Tx" SG_ 854 LHS_Temp_Display_Digit2 1;
BA_ "U_P702_MY2021_Tx" SG_ 854 LHS_Temp_Display_Digit2 1;
BA_ "U_CX727_MY2021_Tx" SG_ 854 LHS_Temp_Display_Digit2 1;
BA_ "GenSigSendType" SG_ 854 LHS_Temp_Display_Digit2 3;
BA_ "U_CD764_MY2022_Tx" SG_ 854 LHS_Temp_Display_Digit1 1;
BA_ "U_U55X_MY2022_Tx" SG_ 854 LHS_Temp_Display_Digit1 1;
BA_ "U_CD542_MY2021_Tx" SG_ 854 LHS_Temp_Display_Digit1 1;
BA_ "U_T6_MCA_MY2020_Tx" SG_ 854 LHS_Temp_Display_Digit1 1;
BA_ "U_P702_MY2021_Tx" SG_ 854 LHS_Temp_Display_Digit1 1;
BA_ "U_CX727_MY2021_Tx" SG_ 854 LHS_Temp_Display_Digit1 1;
BA_ "GenSigSendType" SG_ 854 LHS_Temp_Display_Digit1 3;
BA_ "U_CD764_MY2022_Tx" SG_ 854 EATC_RHS_Units 1;
BA_ "U_U55X_MY2022_Tx" SG_ 854 EATC_RHS_Units 1;
BA_ "U_CD542_MY2021_Tx" SG_ 854 EATC_RHS_Units 1;
BA_ "U_T6_MCA_MY2020_Tx" SG_ 854 EATC_RHS_Units 1;
BA_ "U_P702_MY2021_Tx" SG_ 854 EATC_RHS_Units 1;
BA_ "U_CX727_MY2021_Tx" SG_ 854 EATC_RHS_Units 1;
BA_ "GenSigSendType" SG_ 854 EATC_RHS_Units 3;
BA_ "U_CD764_MY2022_Tx" SG_ 854 EATC_LHS_Units 1;
BA_ "U_U55X_MY2022_Tx" SG_ 854 EATC_LHS_Units 1;
BA_ "U_CD542_MY2021_Tx" SG_ 854 EATC_LHS_Units 1;
BA_ "U_T6_MCA_MY2020_Tx" SG_ 854 EATC_LHS_Units 1;
BA_ "U_P702_MY2021_Tx" SG_ 854 EATC_LHS_Units 1;
BA_ "U_CX727_MY2021_Tx" SG_ 854 EATC_LHS_Units 1;
BA_ "GenSigSendType" SG_ 854 EATC_LHS_Units 3;
BA_ "GenSigStartValue" SG_ 1502 DCME_GWOnBoardTester 255;
BA_ "ContentDependant" SG_ 1502 DCME_GWOnBoardTester 1;
BA_ "GenSigStartValueInteger" SG_ 1502 DCME_GWOnBoardTester 255;
BA_ "GenSigStartValue" SG_ 1502 DCME_GWNMProxY 255;
BA_ "ContentDependant" SG_ 1502 DCME_GWNMProxY 1;
BA_ "GenSigStartValueInteger" SG_ 1502 DCME_GWNMProxY 255;
BA_ "GenSigStartValue" SG_ 1502 DCME_AutoSarNMReserved4 255;
BA_ "ContentDependant" SG_ 1502 DCME_AutoSarNMReserved4 1;
BA_ "GenSigStartValueInteger" SG_ 1502 DCME_AutoSarNMReserved4 255;
BA_ "GenSigStartValue" SG_ 1502 DCME_AutoSarNMReserved3 255;
BA_ "ContentDependant" SG_ 1502 DCME_AutoSarNMReserved3 1;
BA_ "GenSigStartValueInteger" SG_ 1502 DCME_AutoSarNMReserved3 255;
BA_ "GenSigStartValue" SG_ 1502 DCME_AutoSarNMReserved2 255;
BA_ "ContentDependant" SG_ 1502 DCME_AutoSarNMReserved2 1;
BA_ "GenSigStartValueInteger" SG_ 1502 DCME_AutoSarNMReserved2 255;
BA_ "GenSigStartValue" SG_ 1502 DCME_AutoSarNMReserved 255;
BA_ "ContentDependant" SG_ 1502 DCME_AutoSarNMReserved 1;
BA_ "GenSigStartValueInteger" SG_ 1502 DCME_AutoSarNMReserved 255;
BA_ "GenSigStartValue" SG_ 1502 DCME_AutoSarNMNodeId 222;
BA_ "ContentDependant" SG_ 1502 DCME_AutoSarNMNodeId 1;
BA_ "GenSigStartValueInteger" SG_ 1502 DCME_AutoSarNMNodeId 222;
BA_ "ContentDependant" SG_ 1502 DCME_AutoSarNMControl 1;
BA_ "U_CX727_MY2021_Rx" SG_ 534 WhlDirFr_D_Actl 1;
BA_ "U_T6_MCA_MY2020_Rx" SG_ 534 WhlRotatFr_No_Cnt 1;
BA_ "U_CX727_MY2021_Rx" SG_ 534 WhlRotatFr_No_Cnt 1;
BA_ "U_CD764_MY2022_Tx" SG_ 772 SeatScrnDrvOn_B_Rq 1;
BA_ "U_U55X_MY2022_Tx" SG_ 772 SeatScrnDrvOn_B_Rq 1;
BA_ "U_CD542_MY2021_Tx" SG_ 772 SeatScrnDrvOn_B_Rq 1;
BA_ "U_T6_MCA_MY2020_Tx" SG_ 772 SeatScrnDrvOn_B_Rq 1;
BA_ "U_P702_MY2021_Tx" SG_ 772 SeatScrnDrvOn_B_Rq 1;
BA_ "U_CX727_MY2021_Tx" SG_ 772 SeatScrnDrvOn_B_Rq 1;
BA_ "GenSigSendType" SG_ 772 SeatScrnDrvOn_B_Rq 3;
BA_ "WakeupSignal" SG_ 772 SeatScrnDrvOn_B_Rq 1;
BA_ "U_U55X_MY2022_Tx" SG_ 772 PwRnngBoardT_D_Stat 1;
BA_ "GenSigSendType" SG_ 772 PwRnngBoardT_D_Stat 3;
BA_ "U_U55X_MY2022_Tx" SG_ 772 PwRnngBoardSwtch_D_Stat 1;
BA_ "GenSigSendType" SG_ 772 PwRnngBoardSwtch_D_Stat 3;
BA_ "U_U55X_MY2022_Tx" SG_ 772 SeatSlprPosMsgTxt_B_Rq 1;
BA_ "U_CD542_MY2021_Tx" SG_ 772 SeatSlprPosMsgTxt_B_Rq 1;
BA_ "U_T6_MCA_MY2020_Tx" SG_ 772 SeatSlprPosMsgTxt_B_Rq 1;
BA_ "GenSigSendType" SG_ 772 SeatSlprPosMsgTxt_B_Rq 3;
BA_ "U_CD764_MY2022_Tx" SG_ 772 SeatPos_D_Stat 1;
BA_ "U_U55X_MY2022_Tx" SG_ 772 SeatPos_D_Stat 1;
BA_ "U_T6_MCA_MY2020_Tx" SG_ 772 SeatPos_D_Stat 1;
BA_ "U_U55X_MY2022_Rx" SG_ 772 SeatPos_D_Stat 1;
BA_ "GenSigSendType" SG_ 772 SeatPos_D_Stat 3;
BA_ "U_CD764_MY2022_Tx" SG_ 772 MemDrvDeny_B_Stat 1;
BA_ "U_U55X_MY2022_Tx" SG_ 772 MemDrvDeny_B_Stat 1;
BA_ "U_CD542_MY2021_Tx" SG_ 772 MemDrvDeny_B_Stat 1;
BA_ "U_T6_MCA_MY2020_Tx" SG_ 772 MemDrvDeny_B_Stat 1;
BA_ "U_P702_MY2021_Tx" SG_ 772 MemDrvDeny_B_Stat 1;
BA_ "U_CX727_MY2021_Tx" SG_ 772 MemDrvDeny_B_Stat 1;
BA_ "GenSigSendType" SG_ 772 MemDrvDeny_B_Stat 3;
BA_ "U_U55X_MY2022_Tx" SG_ 772 SeatSlprPosPsngr_D_Stat 1;
BA_ "U_CD542_MY2021_Tx" SG_ 772 SeatSlprPosPsngr_D_Stat 1;
BA_ "U_T6_MCA_MY2020_Tx" SG_ 772 SeatSlprPosPsngr_D_Stat 1;
BA_ "GenSigSendType" SG_ 772 SeatSlprPosPsngr_D_Stat 3;
BA_ "U_CD764_MY2022_Tx" SG_ 772 Memory_Feedback_Rqst 1;
BA_ "U_U55X_MY2022_Tx" SG_ 772 Memory_Feedback_Rqst 1;
BA_ "U_CD542_MY2021_Tx" SG_ 772 Memory_Feedback_Rqst 1;
BA_ "U_T6_MCA_MY2020_Tx" SG_ 772 Memory_Feedback_Rqst 1;
BA_ "U_P702_MY2021_Tx" SG_ 772 Memory_Feedback_Rqst 1;
BA_ "U_CX727_MY2021_Tx" SG_ 772 Memory_Feedback_Rqst 1;
BA_ "GenSigSendType" SG_ 772 Memory_Feedback_Rqst 3;
BA_ "WakeupSignal" SG_ 772 Memory_Feedback_Rqst 1;
BA_ "U_CD764_MY2022_Tx" SG_ 772 Easy_Entry_Rqst 1;
BA_ "U_U55X_MY2022_Tx" SG_ 772 Easy_Entry_Rqst 1;
BA_ "U_CD542_MY2021_Tx" SG_ 772 Easy_Entry_Rqst 1;
BA_ "U_T6_MCA_MY2020_Tx" SG_ 772 Easy_Entry_Rqst 1;
BA_ "U_P702_MY2021_Tx" SG_ 772 Easy_Entry_Rqst 1;
BA_ "U_CX727_MY2021_Tx" SG_ 772 Easy_Entry_Rqst 1;
BA_ "U_CD764_MY2022_Rx" SG_ 772 Easy_Entry_Rqst 1;
BA_ "U_U55X_MY2022_Rx" SG_ 772 Easy_Entry_Rqst 1;
BA_ "U_P702_MY2021_Rx" SG_ 772 Easy_Entry_Rqst 1;
BA_ "GenSigSendType" SG_ 772 Easy_Entry_Rqst 3;
BA_ "WakeupSignal" SG_ 772 Easy_Entry_Rqst 1;
BA_ "U_CD764_MY2022_Tx" SG_ 772 Memory_Cmd 1;
BA_ "U_U55X_MY2022_Tx" SG_ 772 Memory_Cmd 1;
BA_ "U_CD542_MY2021_Tx" SG_ 772 Memory_Cmd 1;
BA_ "U_T6_MCA_MY2020_Tx" SG_ 772 Memory_Cmd 1;
BA_ "U_P702_MY2021_Tx" SG_ 772 Memory_Cmd 1;
BA_ "U_CX727_MY2021_Tx" SG_ 772 Memory_Cmd 1;
BA_ "U_CD542_MY2021_Rx" SG_ 772 Memory_Cmd 1;
BA_ "U_CX727_MY2021_Rx" SG_ 772 Memory_Cmd 1;
BA_ "U_T6_MCA_MY2020_Rx" SG_ 772 Memory_Cmd 1;
BA_ "U_CD764_MY2022_Rx" SG_ 772 Memory_Cmd 1;
BA_ "U_U55X_MY2022_Rx" SG_ 772 Memory_Cmd 1;
BA_ "U_P702_MY2021_Rx" SG_ 772 Memory_Cmd 1;
BA_ "GenSigSendType" SG_ 772 Memory_Cmd 3;
BA_ "WakeupSignal" SG_ 772 Memory_Cmd 1;
BA_ "U_CD764_MY2022_Tx" SG_ 772 Cancel_Auto_Movement 1;
BA_ "U_U55X_MY2022_Tx" SG_ 772 Cancel_Auto_Movement 1;
BA_ "U_CD542_MY2021_Tx" SG_ 772 Cancel_Auto_Movement 1;
BA_ "U_T6_MCA_MY2020_Tx" SG_ 772 Cancel_Auto_Movement 1;
BA_ "U_P702_MY2021_Tx" SG_ 772 Cancel_Auto_Movement 1;
BA_ "U_CX727_MY2021_Tx" SG_ 772 Cancel_Auto_Movement 1;
BA_ "U_CD542_MY2021_Rx" SG_ 772 Cancel_Auto_Movement 1;
BA_ "U_T6_MCA_MY2020_Rx" SG_ 772 Cancel_Auto_Movement 1;
BA_ "U_CX727_MY2021_Rx" SG_ 772 Cancel_Auto_Movement 1;
BA_ "U_CD764_MY2022_Rx" SG_ 772 Cancel_Auto_Movement 1;
BA_ "U_U55X_MY2022_Rx" SG_ 772 Cancel_Auto_Movement 1;
BA_ "U_P702_MY2021_Rx" SG_ 772 Cancel_Auto_Movement 1;
BA_ "GenSigSendType" SG_ 772 Cancel_Auto_Movement 3;
BA_ "WakeupSignal" SG_ 772 Cancel_Auto_Movement 1;
BA_ "U_T6_MCA_MY2020_Tx" SG_ 935 SodInnrRight_D_Stat 1;
BA_ "U_T6_MCA_MY2020_Rx" SG_ 935 SodInnrRight_D_Stat 1;
BA_ "U_T6_MCA_MY2020_Tx" SG_ 935 CtaInnrRight_D_Stat 1;
BA_ "U_T6_MCA_MY2020_Rx" SG_ 935 CtaInnrRight_D_Stat 1;
BA_ "U_T6_MCA_MY2020_Tx" SG_ 935 CtaAlrtRight2_D_Stat 1;
BA_ "GenSigSendType" SG_ 935 CtaAlrtRight2_D_Stat 3;
BA_ "GenSigSendType" SG_ 935 BttRight_D_Stat 3;
BA_ "GenSigSendType" SG_ 935 BttRight_D_RqDrv 3;
BA_ "GenSigSendType" SG_ 935 CtaBrkRightMsgTxt_B_Rq 3;
BA_ "GenSigSendType" SG_ 935 CtaRightBrkEnbl_B_Rq 3;
BA_ "GenSigSendType" SG_ 935 CtaRightBrkDecel_B_Rq 3;
BA_ "U_T6_MCA_MY2020_Tx" SG_ 935 Side_Detect_R_Illum 1;
BA_ "U_CX727_MY2021_Rx" SG_ 935 Side_Detect_R_Illum 1;
BA_ "U_CD764_MY2022_Rx" SG_ 935 Side_Detect_R_Illum 1;
BA_ "U_U55X_MY2022_Rx" SG_ 935 Side_Detect_R_Illum 1;
BA_ "U_CD542_MY2021_Rx" SG_ 935 Side_Detect_R_Illum 1;
BA_ "U_T6_MCA_MY2020_Rx" SG_ 935 Side_Detect_R_Illum 1;
BA_ "U_P702_MY2021_Rx" SG_ 935 Side_Detect_R_Illum 1;
BA_ "GenSigSendType" SG_ 935 Side_Detect_R_Illum 3;
BA_ "GenSigStartValue" SG_ 935 Side_Detect_R_Illum 100;
BA_ "GenSigStartValueInteger" SG_ 935 Side_Detect_R_Illum 100;
BA_ "U_T6_MCA_MY2020_Tx" SG_ 935 CtaSnsRight_D_Stat 1;
BA_ "U_T6_MCA_MY2020_Rx" SG_ 935 CtaSnsRight_D_Stat 1;
BA_ "GenSigSendType" SG_ 935 CtaSnsRight_D_Stat 3;
BA_ "U_T6_MCA_MY2020_Tx" SG_ 935 CtaAlrtRight_D_Stat 1;
BA_ "U_CX727_MY2021_Rx" SG_ 935 CtaAlrtRight_D_Stat 1;
BA_ "U_CD764_MY2022_Rx" SG_ 935 CtaAlrtRight_D_Stat 1;
BA_ "U_U55X_MY2022_Rx" SG_ 935 CtaAlrtRight_D_Stat 1;
BA_ "U_CD542_MY2021_Rx" SG_ 935 CtaAlrtRight_D_Stat 1;
BA_ "U_T6_MCA_MY2020_Rx" SG_ 935 CtaAlrtRight_D_Stat 1;
BA_ "U_P702_MY2021_Rx" SG_ 935 CtaAlrtRight_D_Stat 1;
BA_ "GenSigSendType" SG_ 935 CtaAlrtRight_D_Stat 3;
BA_ "U_T6_MCA_MY2020_Tx" SG_ 935 CtaRight_D_Stat 1;
BA_ "U_T6_MCA_MY2020_Rx" SG_ 935 CtaRight_D_Stat 1;
BA_ "GenSigSendType" SG_ 935 CtaRight_D_Stat 3;
BA_ "U_T6_MCA_MY2020_Tx" SG_ 935 SodRight_D_Stat 1;
BA_ "U_T6_MCA_MY2020_Rx" SG_ 935 SodRight_D_Stat 1;
BA_ "GenSigSendType" SG_ 935 SodRight_D_Stat 3;
BA_ "GenSigStartValue" SG_ 935 SodRight_D_Stat 2;
BA_ "GenSigStartValueInteger" SG_ 935 SodRight_D_Stat 2;
BA_ "U_T6_MCA_MY2020_Tx" SG_ 935 SodSnsRight_D_Stat 1;
BA_ "U_CX727_MY2021_Rx" SG_ 935 SodSnsRight_D_Stat 1;
BA_ "U_CD764_MY2022_Rx" SG_ 935 SodSnsRight_D_Stat 1;
BA_ "U_U55X_MY2022_Rx" SG_ 935 SodSnsRight_D_Stat 1;
BA_ "U_CD542_MY2021_Rx" SG_ 935 SodSnsRight_D_Stat 1;
BA_ "U_T6_MCA_MY2020_Rx" SG_ 935 SodSnsRight_D_Stat 1;
BA_ "U_P702_MY2021_Rx" SG_ 935 SodSnsRight_D_Stat 1;
BA_ "GenSigSendType" SG_ 935 SodSnsRight_D_Stat 3;
BA_ "U_T6_MCA_MY2020_Tx" SG_ 935 SodAlrtRight_D_Stat 1;
BA_ "U_CX727_MY2021_Rx" SG_ 935 SodAlrtRight_D_Stat 1;
BA_ "U_CD764_MY2022_Rx" SG_ 935 SodAlrtRight_D_Stat 1;
BA_ "U_U55X_MY2022_Rx" SG_ 935 SodAlrtRight_D_Stat 1;
BA_ "U_CD542_MY2021_Rx" SG_ 935 SodAlrtRight_D_Stat 1;
BA_ "U_T6_MCA_MY2020_Rx" SG_ 935 SodAlrtRight_D_Stat 1;
BA_ "U_P702_MY2021_Rx" SG_ 935 SodAlrtRight_D_Stat 1;
BA_ "GenSigSendType" SG_ 935 SodAlrtRight_D_Stat 3;
BA_ "U_T6_MCA_MY2020_Tx" SG_ 935 SodDetctRight_D_Stat 1;
BA_ "GenSigSendType" SG_ 935 SodDetctRight_D_Stat 3;
BA_ "U_T6_MCA_MY2020_Tx" SG_ 935 SodWarnRight_Prd_Rq 1;
BA_ "U_CX727_MY2021_Rx" SG_ 935 SodWarnRight_Prd_Rq 1;
BA_ "U_CD764_MY2022_Rx" SG_ 935 SodWarnRight_Prd_Rq 1;
BA_ "U_U55X_MY2022_Rx" SG_ 935 SodWarnRight_Prd_Rq 1;
BA_ "U_CD542_MY2021_Rx" SG_ 935 SodWarnRight_Prd_Rq 1;
BA_ "U_T6_MCA_MY2020_Rx" SG_ 935 SodWarnRight_Prd_Rq 1;
BA_ "U_P702_MY2021_Rx" SG_ 935 SodWarnRight_Prd_Rq 1;
BA_ "GenSigSendType" SG_ 935 SodWarnRight_Prd_Rq 3;
BA_ "GenSigStartValue" SG_ 935 SodWarnRight_Prd_Rq 14;
BA_ "GenSigStartValueInteger" SG_ 935 SodWarnRight_Prd_Rq 14;
BA_ "GenSigSendType" SG_ 934 RbaCtaLeft_D_Stat 3;
BA_ "U_T6_MCA_MY2020_Tx" SG_ 934 SodInnrLeft_D_Stat 1;
BA_ "U_T6_MCA_MY2020_Rx" SG_ 934 SodInnrLeft_D_Stat 1;
BA_ "GenSigSendType" SG_ 934 SodInnrLeft_D_Stat 3;
BA_ "U_T6_MCA_MY2020_Tx" SG_ 934 CtaInnrLeft_D_Stat 1;
BA_ "U_T6_MCA_MY2020_Rx" SG_ 934 CtaInnrLeft_D_Stat 1;
BA_ "GenSigSendType" SG_ 934 CtaInnrLeft_D_Stat 3;
BA_ "GenSigSendType" SG_ 934 LcwaLeft_D_Stat 3;
BA_ "GenSigSendType" SG_ 934 LcwaDetctLeft2_B_Stat 3;
BA_ "GenSigSendType" SG_ 934 LcwaDetctLeft1_B_Stat 3;
BA_ "U_T6_MCA_MY2020_Tx" SG_ 934 CtaAlrtLeft2_D_Stat 1;
BA_ "GenSigSendType" SG_ 934 CtaAlrtLeft2_D_Stat 3;
BA_ "GenSigSendType" SG_ 934 CtaBrkLeftMsgTxt_B_Rq 3;
BA_ "GenSigSendType" SG_ 934 CtaLeftBrkDecel_B_Rq 3;
BA_ "GenSigSendType" SG_ 934 CtaLeftBrkEnbl_B_Rq 3;
BA_ "U_T6_MCA_MY2020_Tx" SG_ 934 Side_Detect_L_Illum 1;
BA_ "U_CX727_MY2021_Rx" SG_ 934 Side_Detect_L_Illum 1;
BA_ "U_CD764_MY2022_Rx" SG_ 934 Side_Detect_L_Illum 1;
BA_ "U_U55X_MY2022_Rx" SG_ 934 Side_Detect_L_Illum 1;
BA_ "U_CD542_MY2021_Rx" SG_ 934 Side_Detect_L_Illum 1;
BA_ "U_T6_MCA_MY2020_Rx" SG_ 934 Side_Detect_L_Illum 1;
BA_ "U_P702_MY2021_Rx" SG_ 934 Side_Detect_L_Illum 1;
BA_ "GenSigStartValue" SG_ 934 Side_Detect_L_Illum 100;
BA_ "GenSigStartValueInteger" SG_ 934 Side_Detect_L_Illum 100;
BA_ "GenSigSendType" SG_ 934 BttLeft_D_Stat 3;
BA_ "GenSigSendType" SG_ 934 BttLeft_D_RqDrv 3;
BA_ "U_T6_MCA_MY2020_Tx" SG_ 934 CtaSnsLeft_D_Stat 1;
BA_ "U_T6_MCA_MY2020_Rx" SG_ 934 CtaSnsLeft_D_Stat 1;
BA_ "GenSigSendType" SG_ 934 CtaSnsLeft_D_Stat 3;
BA_ "U_T6_MCA_MY2020_Tx" SG_ 934 SodDetctLeft_D_Stat 1;
BA_ "GenSigSendType" SG_ 934 SodDetctLeft_D_Stat 3;
BA_ "U_T6_MCA_MY2020_Tx" SG_ 934 CtaLeft_D_Stat 1;
BA_ "U_T6_MCA_MY2020_Rx" SG_ 934 CtaLeft_D_Stat 1;
BA_ "GenSigSendType" SG_ 934 CtaLeft_D_Stat 3;
BA_ "U_T6_MCA_MY2020_Tx" SG_ 934 CtaAlrtLeft_D_Stat 1;
BA_ "U_CX727_MY2021_Rx" SG_ 934 CtaAlrtLeft_D_Stat 1;
BA_ "U_CD764_MY2022_Rx" SG_ 934 CtaAlrtLeft_D_Stat 1;
BA_ "U_U55X_MY2022_Rx" SG_ 934 CtaAlrtLeft_D_Stat 1;
BA_ "U_CD542_MY2021_Rx" SG_ 934 CtaAlrtLeft_D_Stat 1;
BA_ "U_T6_MCA_MY2020_Rx" SG_ 934 CtaAlrtLeft_D_Stat 1;
BA_ "U_P702_MY2021_Rx" SG_ 934 CtaAlrtLeft_D_Stat 1;
BA_ "GenSigSendType" SG_ 934 CtaAlrtLeft_D_Stat 3;
BA_ "U_T6_MCA_MY2020_Tx" SG_ 934 SodLeft_D_Stat 1;
BA_ "U_T6_MCA_MY2020_Rx" SG_ 934 SodLeft_D_Stat 1;
BA_ "GenSigSendType" SG_ 934 SodLeft_D_Stat 3;
BA_ "GenSigStartValue" SG_ 934 SodLeft_D_Stat 2;
BA_ "GenSigStartValueInteger" SG_ 934 SodLeft_D_Stat 2;
BA_ "U_T6_MCA_MY2020_Tx" SG_ 934 SodSnsLeft_D_Stat 1;
BA_ "U_CX727_MY2021_Rx" SG_ 934 SodSnsLeft_D_Stat 1;
BA_ "U_CD764_MY2022_Rx" SG_ 934 SodSnsLeft_D_Stat 1;
BA_ "U_U55X_MY2022_Rx" SG_ 934 SodSnsLeft_D_Stat 1;
BA_ "U_CD542_MY2021_Rx" SG_ 934 SodSnsLeft_D_Stat 1;
BA_ "U_T6_MCA_MY2020_Rx" SG_ 934 SodSnsLeft_D_Stat 1;
BA_ "U_P702_MY2021_Rx" SG_ 934 SodSnsLeft_D_Stat 1;
BA_ "GenSigSendType" SG_ 934 SodSnsLeft_D_Stat 3;
BA_ "U_T6_MCA_MY2020_Tx" SG_ 934 SodAlrtLeft_D_Stat 1;
BA_ "U_CX727_MY2021_Rx" SG_ 934 SodAlrtLeft_D_Stat 1;
BA_ "U_CD764_MY2022_Rx" SG_ 934 SodAlrtLeft_D_Stat 1;
BA_ "U_U55X_MY2022_Rx" SG_ 934 SodAlrtLeft_D_Stat 1;
BA_ "U_CD542_MY2021_Rx" SG_ 934 SodAlrtLeft_D_Stat 1;
BA_ "U_T6_MCA_MY2020_Rx" SG_ 934 SodAlrtLeft_D_Stat 1;
BA_ "U_P702_MY2021_Rx" SG_ 934 SodAlrtLeft_D_Stat 1;
BA_ "GenSigSendType" SG_ 934 SodAlrtLeft_D_Stat 3;
BA_ "U_T6_MCA_MY2020_Tx" SG_ 934 SodWarnLeft_Prd_Rq 1;
BA_ "U_CX727_MY2021_Rx" SG_ 934 SodWarnLeft_Prd_Rq 1;
BA_ "U_CD764_MY2022_Rx" SG_ 934 SodWarnLeft_Prd_Rq 1;
BA_ "U_U55X_MY2022_Rx" SG_ 934 SodWarnLeft_Prd_Rq 1;
BA_ "U_CD542_MY2021_Rx" SG_ 934 SodWarnLeft_Prd_Rq 1;
BA_ "U_T6_MCA_MY2020_Rx" SG_ 934 SodWarnLeft_Prd_Rq 1;
BA_ "U_P702_MY2021_Rx" SG_ 934 SodWarnLeft_Prd_Rq 1;
BA_ "GenSigStartValue" SG_ 934 SodWarnLeft_Prd_Rq 14;
BA_ "GenSigStartValueInteger" SG_ 934 SodWarnLeft_Prd_Rq 14;
BA_ "GenSigSendType" SG_ 969 WndwQtrRrDown_B_Stat 3;
BA_ "GenSigSendType" SG_ 969 WndwQtrRlDown_B_Stat 3;
BA_ "GenSigSendType" SG_ 969 Dimming_Level_Stat 3;
BA_ "GenSigSendType" SG_ 969 Current_Color_Stat 3;
BA_ "GenSigStartValue" SG_ 969 Current_Color_Stat 8;
BA_ "GenSigStartValueInteger" SG_ 969 Current_Color_Stat 8;
BA_ "GenSigSendType" SG_ 969 BlendedColorRed_Stat 3;
BA_ "GenSigSendType" SG_ 969 BlendedColorGreen_Stat 3;
BA_ "GenSigSendType" SG_ 969 BlendedColorBlue_Stat 3;
BA_ "GenSigSendType" SG_ 969 BlendedColor_Stat 3;
BA_ "GenSigStartValue" SG_ 969 BlendedColor_Stat 2;
BA_ "GenSigStartValueInteger" SG_ 969 BlendedColor_Stat 2;
BA_ "GenSigSendType" SG_ 969 TurnLampRrOut_B_Stat 3;
BA_ "ContentDependant" SG_ 969 TurnLampRrOut_B_Stat 1;
BA_ "WakeupSignal" SG_ 969 TurnLampRrOut_B_Stat 1;
BA_ "GenSigSendType" SG_ 969 TurnLampRlOut_B_Stat 3;
BA_ "ContentDependant" SG_ 969 TurnLampRlOut_B_Stat 1;
BA_ "WakeupSignal" SG_ 969 TurnLampRlOut_B_Stat 1;
BA_ "U_U55X_MY2022_Rx" SG_ 1070 StopStrtStdby_D_Indic_UB 1;
BA_ "U_T6_MCA_MY2020_Rx" SG_ 1070 StopStrtStdby_D_Indic_UB 1;
BA_ "U_CD764_MY2022_Rx" SG_ 1070 StopStrtStdby_D_Indic_UB 1;
BA_ "U_CX727_MY2021_Rx" SG_ 1070 StopStrtStdby_D_Indic_UB 1;
BA_ "U_CD764_MY2022_Rx" SG_ 1070 PassRstrnInd_Req_UB 1;
BA_ "U_U55X_MY2022_Rx" SG_ 1070 PassRstrnInd_Req_UB 1;
BA_ "U_CD542_MY2021_Rx" SG_ 1070 PassRstrnInd_Req_UB 1;
BA_ "U_T6_MCA_MY2020_Rx" SG_ 1070 PassRstrnInd_Req_UB 1;
BA_ "U_CX727_MY2021_Rx" SG_ 1070 HiElPwInhbt_B_Stat_UB 1;
BA_ "U_CD764_MY2022_Rx" SG_ 1070 HiElPwInhbt_B_Stat_UB 1;
BA_ "U_U55X_MY2022_Rx" SG_ 1070 HiElPwInhbt_B_Stat_UB 1;
BA_ "U_CD542_MY2021_Rx" SG_ 1070 HiElPwInhbt_B_Stat_UB 1;
BA_ "U_T6_MCA_MY2020_Rx" SG_ 1070 HiElPwInhbt_B_Stat_UB 1;
BA_ "U_P702_MY2021_Rx" SG_ 1070 HiElPwInhbt_B_Stat_UB 1;
BA_ "U_CX727_MY2021_Rx" SG_ 1070 HiElPwInhbt_B_Stat 1;
BA_ "U_CD764_MY2022_Rx" SG_ 1070 HiElPwInhbt_B_Stat 1;
BA_ "U_U55X_MY2022_Rx" SG_ 1070 HiElPwInhbt_B_Stat 1;
BA_ "U_CD542_MY2021_Rx" SG_ 1070 HiElPwInhbt_B_Stat 1;
BA_ "U_T6_MCA_MY2020_Rx" SG_ 1070 HiElPwInhbt_B_Stat 1;
BA_ "U_P702_MY2021_Rx" SG_ 1070 HiElPwInhbt_B_Stat 1;
BA_ "GenSigSendType" SG_ 1070 HiElPwInhbt_B_Stat 3;
BA_ "ContentDependant" SG_ 1070 HiElPwInhbt_B_Stat 1;
BA_ "U_U55X_MY2022_Rx" SG_ 1070 StopStrtStdby_D_Indic 1;
BA_ "U_T6_MCA_MY2020_Rx" SG_ 1070 StopStrtStdby_D_Indic 1;
BA_ "U_CD764_MY2022_Rx" SG_ 1070 StopStrtStdby_D_Indic 1;
BA_ "U_CX727_MY2021_Rx" SG_ 1070 StopStrtStdby_D_Indic 1;
BA_ "GenSigSendType" SG_ 1070 StopStrtStdby_D_Indic 3;
BA_ "U_CD764_MY2022_Rx" SG_ 1070 CoolantFanStepAct_UB 1;
BA_ "U_U55X_MY2022_Rx" SG_ 1070 CoolantFanStepAct_UB 1;
BA_ "U_CD542_MY2021_Rx" SG_ 1070 CoolantFanStepAct_UB 1;
BA_ "U_T6_MCA_MY2020_Rx" SG_ 1070 CoolantFanStepAct_UB 1;
BA_ "U_P702_MY2021_Rx" SG_ 1070 CoolantFanStepAct_UB 1;
BA_ "U_CX727_MY2021_Rx" SG_ 1070 CoolantFanStepAct_UB 1;
BA_ "U_CD764_MY2022_Rx" SG_ 1070 CoolantFanStepAct 1;
BA_ "U_U55X_MY2022_Rx" SG_ 1070 CoolantFanStepAct 1;
BA_ "U_CD542_MY2021_Rx" SG_ 1070 CoolantFanStepAct 1;
BA_ "U_T6_MCA_MY2020_Rx" SG_ 1070 CoolantFanStepAct 1;
BA_ "U_P702_MY2021_Rx" SG_ 1070 CoolantFanStepAct 1;
BA_ "U_CX727_MY2021_Rx" SG_ 1070 CoolantFanStepAct 1;
BA_ "GenSigSendType" SG_ 1070 CoolantFanStepAct 3;
BA_ "U_CD764_MY2022_Rx" SG_ 1070 RstrnImpactEvntStatus_UB 1;
BA_ "U_U55X_MY2022_Rx" SG_ 1070 RstrnImpactEvntStatus_UB 1;
BA_ "U_CD542_MY2021_Rx" SG_ 1070 RstrnImpactEvntStatus_UB 1;
BA_ "U_T6_MCA_MY2020_Rx" SG_ 1070 RstrnImpactEvntStatus_UB 1;
BA_ "U_P702_MY2021_Rx" SG_ 1070 RstrnImpactEvntStatus_UB 1;
BA_ "U_CX727_MY2021_Rx" SG_ 1070 RstrnImpactEvntStatus_UB 1;
BA_ "U_CD764_MY2022_Rx" SG_ 1070 EngAirIn_Te_Actl_UB 1;
BA_ "U_U55X_MY2022_Rx" SG_ 1070 EngAirIn_Te_Actl_UB 1;
BA_ "U_CD542_MY2021_Rx" SG_ 1070 EngAirIn_Te_Actl_UB 1;
BA_ "U_T6_MCA_MY2020_Rx" SG_ 1070 EngAirIn_Te_Actl_UB 1;
BA_ "U_P702_MY2021_Rx" SG_ 1070 EngAirIn_Te_Actl_UB 1;
BA_ "U_CX727_MY2021_Rx" SG_ 1070 EngAirIn_Te_Actl_UB 1;
BA_ "U_CD764_MY2022_Rx" SG_ 1070 RstrnImpactEvntStatus 1;
BA_ "U_U55X_MY2022_Rx" SG_ 1070 RstrnImpactEvntStatus 1;
BA_ "U_CD542_MY2021_Rx" SG_ 1070 RstrnImpactEvntStatus 1;
BA_ "U_T6_MCA_MY2020_Rx" SG_ 1070 RstrnImpactEvntStatus 1;
BA_ "U_P702_MY2021_Rx" SG_ 1070 RstrnImpactEvntStatus 1;
BA_ "U_CX727_MY2021_Rx" SG_ 1070 RstrnImpactEvntStatus 1;
BA_ "GenSigSendType" SG_ 1070 RstrnImpactEvntStatus 3;
BA_ "WakeupSignal" SG_ 1070 RstrnImpactEvntStatus 1;
BA_ "U_CD764_MY2022_Rx" SG_ 1070 EngAirIn_Te_Actl 1;
BA_ "U_U55X_MY2022_Rx" SG_ 1070 EngAirIn_Te_Actl 1;
BA_ "U_CD542_MY2021_Rx" SG_ 1070 EngAirIn_Te_Actl 1;
BA_ "U_T6_MCA_MY2020_Rx" SG_ 1070 EngAirIn_Te_Actl 1;
BA_ "U_P702_MY2021_Rx" SG_ 1070 EngAirIn_Te_Actl 1;
BA_ "U_CX727_MY2021_Rx" SG_ 1070 EngAirIn_Te_Actl 1;
BA_ "U_CD764_MY2022_Rx" SG_ 1070 EngAout_N_Actl_UB 1;
BA_ "U_U55X_MY2022_Rx" SG_ 1070 EngAout_N_Actl_UB 1;
BA_ "U_CD542_MY2021_Rx" SG_ 1070 EngAout_N_Actl_UB 1;
BA_ "U_T6_MCA_MY2020_Rx" SG_ 1070 EngAout_N_Actl_UB 1;
BA_ "U_P702_MY2021_Rx" SG_ 1070 EngAout_N_Actl_UB 1;
BA_ "U_CX727_MY2021_Rx" SG_ 1070 EngAout_N_Actl_UB 1;
BA_ "U_CD764_MY2022_Rx" SG_ 1070 EngAout_N_Actl 1;
BA_ "U_U55X_MY2022_Rx" SG_ 1070 EngAout_N_Actl 1;
BA_ "U_CD542_MY2021_Rx" SG_ 1070 EngAout_N_Actl 1;
BA_ "U_T6_MCA_MY2020_Rx" SG_ 1070 EngAout_N_Actl 1;
BA_ "U_P702_MY2021_Rx" SG_ 1070 EngAout_N_Actl 1;
BA_ "U_CX727_MY2021_Rx" SG_ 1070 EngAout_N_Actl 1;
BA_ "U_CX727_MY2021_Rx" SG_ 1070 VehVActlEng_D_Qf 1;
BA_ "U_CD764_MY2022_Rx" SG_ 1070 VehVActlEng_D_Qf 1;
BA_ "U_U55X_MY2022_Rx" SG_ 1070 VehVActlEng_D_Qf 1;
BA_ "U_CD542_MY2021_Rx" SG_ 1070 VehVActlEng_D_Qf 1;
BA_ "U_T6_MCA_MY2020_Rx" SG_ 1070 VehVActlEng_D_Qf 1;
BA_ "U_P702_MY2021_Rx" SG_ 1070 VehVActlEng_D_Qf 1;
BA_ "MetaData" SG_ 1070 VehVActlEng_D_Qf 1;
BA_ "U_CD764_MY2022_Rx" SG_ 1070 Veh_V_ActlEng_UB 1;
BA_ "U_U55X_MY2022_Rx" SG_ 1070 Veh_V_ActlEng_UB 1;
BA_ "U_CD542_MY2021_Rx" SG_ 1070 Veh_V_ActlEng_UB 1;
BA_ "U_T6_MCA_MY2020_Rx" SG_ 1070 Veh_V_ActlEng_UB 1;
BA_ "U_P702_MY2021_Rx" SG_ 1070 Veh_V_ActlEng_UB 1;
BA_ "U_CX727_MY2021_Rx" SG_ 1070 Veh_V_ActlEng_UB 1;
BA_ "U_CD764_MY2022_Rx" SG_ 1070 Veh_V_ActlEng 1;
BA_ "U_U55X_MY2022_Rx" SG_ 1070 Veh_V_ActlEng 1;
BA_ "U_CD542_MY2021_Rx" SG_ 1070 Veh_V_ActlEng 1;
BA_ "U_T6_MCA_MY2020_Rx" SG_ 1070 Veh_V_ActlEng 1;
BA_ "U_P702_MY2021_Rx" SG_ 1070 Veh_V_ActlEng 1;
BA_ "U_CX727_MY2021_Rx" SG_ 1070 Veh_V_ActlEng 1;
BA_ "U_U55X_MY2022_Rx" SG_ 1070 PassRstrnInd_Req 1;
BA_ "U_CD542_MY2021_Rx" SG_ 1070 PassRstrnInd_Req 1;
BA_ "U_T6_MCA_MY2020_Rx" SG_ 1070 PassRstrnInd_Req 1;
BA_ "GenSigSendType" SG_ 1070 PassRstrnInd_Req 3;
BA_ "GenSigStartValue" SG_ 1070 PassRstrnInd_Req 3;
BA_ "GenSigStartValueInteger" SG_ 1070 PassRstrnInd_Req 3;
BA_ "U_CD542_MY2021_Tx" SG_ 1050 CamraRearBttn_D_Stat 1;
BA_ "U_T6_MCA_MY2020_Tx" SG_ 1050 CamraRearBttn_D_Stat 1;
BA_ "GenSigSendType" SG_ 1050 CamraRearBttn_D_Stat 3;
BA_ "GenSigSendType" SG_ 1050 TrailCtlSwtch_B_Stat 3;
BA_ "U_U55X_MY2022_Tx" SG_ 1050 CamraFrntBttn_D_Stat 1;
BA_ "U_CD542_MY2021_Tx" SG_ 1050 CamraFrntBttn_D_Stat 1;
BA_ "U_T6_MCA_MY2020_Tx" SG_ 1050 CamraFrntBttn_D_Stat 1;
BA_ "U_CX727_MY2021_Tx" SG_ 1050 CamraFrntBttn_D_Stat 1;
BA_ "GenSigSendType" SG_ 1050 CamraFrntBttn_D_Stat 3;
BA_ "U_U55X_MY2022_Tx" SG_ 1050 AutoHoldSwtch_D_Stat 1;
BA_ "U_CD542_MY2021_Tx" SG_ 1050 AutoHoldSwtch_D_Stat 1;
BA_ "U_T6_MCA_MY2020_Tx" SG_ 1050 AutoHoldSwtch_D_Stat 1;
BA_ "U_CX727_MY2021_Tx" SG_ 1050 AutoHoldSwtch_D_Stat 1;
BA_ "GenSigSendType" SG_ 1050 AutoHoldSwtch_D_Stat 3;
BA_ "GenSigSendType" SG_ 1050 GlvBoxRleas_No_Actl 3;
BA_ "WakeupSignal" SG_ 1050 GlvBoxRleas_No_Actl 1;
BA_ "U_CD764_MY2022_Tx" SG_ 1050 EcoInhbt_B_RqHvac 1;
BA_ "U_U55X_MY2022_Tx" SG_ 1050 EcoInhbt_B_RqHvac 1;
BA_ "U_CD542_MY2021_Tx" SG_ 1050 EcoInhbt_B_RqHvac 1;
BA_ "U_T6_MCA_MY2020_Tx" SG_ 1050 EcoInhbt_B_RqHvac 1;
BA_ "U_CX727_MY2021_Tx" SG_ 1050 EcoInhbt_B_RqHvac 1;
BA_ "GenSigSendType" SG_ 1050 EcoInhbt_B_RqHvac 3;
BA_ "U_CD764_MY2022_Tx" SG_ 1050 LpdbPtc3_B_Rq 1;
BA_ "U_U55X_MY2022_Tx" SG_ 1050 LpdbPtc3_B_Rq 1;
BA_ "U_CD542_MY2021_Tx" SG_ 1050 LpdbPtc3_B_Rq 1;
BA_ "U_T6_MCA_MY2020_Tx" SG_ 1050 LpdbPtc3_B_Rq 1;
BA_ "U_CX727_MY2021_Tx" SG_ 1050 LpdbPtc3_B_Rq 1;
BA_ "GenSigSendType" SG_ 1050 LpdbPtc3_B_Rq 3;
BA_ "U_CD764_MY2022_Tx" SG_ 1050 LpdbPtc2_B_Rq 1;
BA_ "U_U55X_MY2022_Tx" SG_ 1050 LpdbPtc2_B_Rq 1;
BA_ "U_CD542_MY2021_Tx" SG_ 1050 LpdbPtc2_B_Rq 1;
BA_ "U_T6_MCA_MY2020_Tx" SG_ 1050 LpdbPtc2_B_Rq 1;
BA_ "U_CX727_MY2021_Tx" SG_ 1050 LpdbPtc2_B_Rq 1;
BA_ "GenSigSendType" SG_ 1050 LpdbPtc2_B_Rq 3;
BA_ "U_CD764_MY2022_Tx" SG_ 1050 LpdbPtc1_B_Rq 1;
BA_ "U_U55X_MY2022_Tx" SG_ 1050 LpdbPtc1_B_Rq 1;
BA_ "U_CD542_MY2021_Tx" SG_ 1050 LpdbPtc1_B_Rq 1;
BA_ "U_T6_MCA_MY2020_Tx" SG_ 1050 LpdbPtc1_B_Rq 1;
BA_ "U_CX727_MY2021_Tx" SG_ 1050 LpdbPtc1_B_Rq 1;
BA_ "GenSigSendType" SG_ 1050 LpdbPtc1_B_Rq 3;
BA_ "U_CD764_MY2022_Tx" SG_ 1050 LpdbHeatWiprPrk_B_Rq 1;
BA_ "U_U55X_MY2022_Tx" SG_ 1050 LpdbHeatWiprPrk_B_Rq 1;
BA_ "U_CD542_MY2021_Tx" SG_ 1050 LpdbHeatWiprPrk_B_Rq 1;
BA_ "U_T6_MCA_MY2020_Tx" SG_ 1050 LpdbHeatWiprPrk_B_Rq 1;
BA_ "U_CX727_MY2021_Tx" SG_ 1050 LpdbHeatWiprPrk_B_Rq 1;
BA_ "GenSigSendType" SG_ 1050 LpdbHeatWiprPrk_B_Rq 3;
BA_ "U_CD764_MY2022_Tx" SG_ 1050 LpdbDfrstRearOn_B_Rq 1;
BA_ "U_U55X_MY2022_Tx" SG_ 1050 LpdbDfrstRearOn_B_Rq 1;
BA_ "U_CD542_MY2021_Tx" SG_ 1050 LpdbDfrstRearOn_B_Rq 1;
BA_ "U_T6_MCA_MY2020_Tx" SG_ 1050 LpdbDfrstRearOn_B_Rq 1;
BA_ "U_CX727_MY2021_Tx" SG_ 1050 LpdbDfrstRearOn_B_Rq 1;
BA_ "GenSigSendType" SG_ 1050 LpdbDfrstRearOn_B_Rq 3;
BA_ "U_CD764_MY2022_Tx" SG_ 1050 LpdbDfrstFrOn_B_Rq 1;
BA_ "U_U55X_MY2022_Tx" SG_ 1050 LpdbDfrstFrOn_B_Rq 1;
BA_ "U_CD542_MY2021_Tx" SG_ 1050 LpdbDfrstFrOn_B_Rq 1;
BA_ "U_T6_MCA_MY2020_Tx" SG_ 1050 LpdbDfrstFrOn_B_Rq 1;
BA_ "U_CX727_MY2021_Tx" SG_ 1050 LpdbDfrstFrOn_B_Rq 1;
BA_ "GenSigSendType" SG_ 1050 LpdbDfrstFrOn_B_Rq 3;
BA_ "U_CD764_MY2022_Tx" SG_ 1050 LpdbDfrstFlOn_B_Rq 1;
BA_ "U_U55X_MY2022_Tx" SG_ 1050 LpdbDfrstFlOn_B_Rq 1;
BA_ "U_CD542_MY2021_Tx" SG_ 1050 LpdbDfrstFlOn_B_Rq 1;
BA_ "U_T6_MCA_MY2020_Tx" SG_ 1050 LpdbDfrstFlOn_B_Rq 1;
BA_ "U_CX727_MY2021_Tx" SG_ 1050 LpdbDfrstFlOn_B_Rq 1;
BA_ "GenSigSendType" SG_ 1050 LpdbDfrstFlOn_B_Rq 3;
BA_ "U_CD764_MY2022_Tx" SG_ 1050 LpdbAuxBlwr_B_Rq 1;
BA_ "U_U55X_MY2022_Tx" SG_ 1050 LpdbAuxBlwr_B_Rq 1;
BA_ "U_CD542_MY2021_Tx" SG_ 1050 LpdbAuxBlwr_B_Rq 1;
BA_ "U_T6_MCA_MY2020_Tx" SG_ 1050 LpdbAuxBlwr_B_Rq 1;
BA_ "U_CX727_MY2021_Tx" SG_ 1050 LpdbAuxBlwr_B_Rq 1;
BA_ "GenSigSendType" SG_ 1050 LpdbAuxBlwr_B_Rq 3;
BA_ "GenSigSendType" SG_ 1050 PrkAidSwtch_No_Cnt 3;
BA_ "U_T6_MCA_MY2020_Tx" SG_ 1050 PrkAidSwtch_D_RqDrv 1;
BA_ "GenSigSendType" SG_ 1050 PrkAidSwtch_D_RqDrv 3;
BA_ "U_CD764_MY2022_Tx" SG_ 1050 SteWhlHeat_D_Rq 1;
BA_ "U_U55X_MY2022_Tx" SG_ 1050 SteWhlHeat_D_Rq 1;
BA_ "U_CD542_MY2021_Tx" SG_ 1050 SteWhlHeat_D_Rq 1;
BA_ "U_T6_MCA_MY2020_Tx" SG_ 1050 SteWhlHeat_D_Rq 1;
BA_ "U_P702_MY2021_Tx" SG_ 1050 SteWhlHeat_D_Rq 1;
BA_ "U_CX727_MY2021_Tx" SG_ 1050 SteWhlHeat_D_Rq 1;
BA_ "GenSigSendType" SG_ 1050 SteWhlHeat_D_Rq 3;
BA_ "U_CD764_MY2022_Tx" SG_ 1050 MirrorHeatOn_B_Rq 1;
BA_ "U_U55X_MY2022_Tx" SG_ 1050 MirrorHeatOn_B_Rq 1;
BA_ "U_CD542_MY2021_Tx" SG_ 1050 MirrorHeatOn_B_Rq 1;
BA_ "U_T6_MCA_MY2020_Tx" SG_ 1050 MirrorHeatOn_B_Rq 1;
BA_ "U_P702_MY2021_Tx" SG_ 1050 MirrorHeatOn_B_Rq 1;
BA_ "U_CX727_MY2021_Tx" SG_ 1050 MirrorHeatOn_B_Rq 1;
BA_ "U_CX727_MY2021_Rx" SG_ 1050 MirrorHeatOn_B_Rq 1;
BA_ "U_CD764_MY2022_Rx" SG_ 1050 MirrorHeatOn_B_Rq 1;
BA_ "U_U55X_MY2022_Rx" SG_ 1050 MirrorHeatOn_B_Rq 1;
BA_ "U_CD542_MY2021_Rx" SG_ 1050 MirrorHeatOn_B_Rq 1;
BA_ "U_T6_MCA_MY2020_Rx" SG_ 1050 MirrorHeatOn_B_Rq 1;
BA_ "U_P702_MY2021_Rx" SG_ 1050 MirrorHeatOn_B_Rq 1;
BA_ "GenSigSendType" SG_ 1050 MirrorHeatOn_B_Rq 3;
BA_ "U_CD764_MY2022_Tx" SG_ 1050 Remote_Start_QuietMode 1;
BA_ "U_U55X_MY2022_Tx" SG_ 1050 Remote_Start_QuietMode 1;
BA_ "U_CD542_MY2021_Tx" SG_ 1050 Remote_Start_QuietMode 1;
BA_ "U_T6_MCA_MY2020_Tx" SG_ 1050 Remote_Start_QuietMode 1;
BA_ "U_P702_MY2021_Tx" SG_ 1050 Remote_Start_QuietMode 1;
BA_ "U_CX727_MY2021_Tx" SG_ 1050 Remote_Start_QuietMode 1;
BA_ "GenSigSendType" SG_ 1050 Remote_Start_QuietMode 3;
BA_ "GenSigSendType" SG_ 1050 DrvSlipCtlMde_B_Rq 3;
BA_ "U_CD764_MY2022_Tx" SG_ 1050 Outside_Air_Temp_Stat 1;
BA_ "U_U55X_MY2022_Tx" SG_ 1050 Outside_Air_Temp_Stat 1;
BA_ "U_CD542_MY2021_Tx" SG_ 1050 Outside_Air_Temp_Stat 1;
BA_ "U_T6_MCA_MY2020_Tx" SG_ 1050 Outside_Air_Temp_Stat 1;
BA_ "U_P702_MY2021_Tx" SG_ 1050 Outside_Air_Temp_Stat 1;
BA_ "U_CX727_MY2021_Tx" SG_ 1050 Outside_Air_Temp_Stat 1;
BA_ "U_CX727_MY2021_Rx" SG_ 1050 Outside_Air_Temp_Stat 1;
BA_ "U_CD764_MY2022_Rx" SG_ 1050 Outside_Air_Temp_Stat 1;
BA_ "U_U55X_MY2022_Rx" SG_ 1050 Outside_Air_Temp_Stat 1;
BA_ "U_CD542_MY2021_Rx" SG_ 1050 Outside_Air_Temp_Stat 1;
BA_ "U_T6_MCA_MY2020_Rx" SG_ 1050 Outside_Air_Temp_Stat 1;
BA_ "U_P702_MY2021_Rx" SG_ 1050 Outside_Air_Temp_Stat 1;
BA_ "GenSigSendType" SG_ 1050 Outside_Air_Temp_Stat 3;
BA_ "GenSigStartValue" SG_ 1050 Outside_Air_Temp_Stat 254;
BA_ "GenSigStartValueInteger" SG_ 1050 Outside_Air_Temp_Stat 254;
BA_ "U_CD764_MY2022_Rx" SG_ 1856 TesterPhysicalReqDDM 1;
BA_ "U_U55X_MY2022_Rx" SG_ 1856 TesterPhysicalReqDDM 1;
BA_ "U_CD542_MY2021_Rx" SG_ 1856 TesterPhysicalReqDDM 1;
BA_ "U_T6_MCA_MY2020_Rx" SG_ 1856 TesterPhysicalReqDDM 1;
BA_ "U_P702_MY2021_Rx" SG_ 1856 TesterPhysicalReqDDM 1;
BA_ "U_CX727_MY2021_Rx" SG_ 1856 TesterPhysicalReqDDM 1;
BA_ "GenSigSendType" SG_ 1856 TesterPhysicalReqDDM 3;
BA_ "U_CD764_MY2022_Tx" SG_ 1864 TesterPhysicalResDDM 1;
BA_ "U_U55X_MY2022_Tx" SG_ 1864 TesterPhysicalResDDM 1;
BA_ "U_CD542_MY2021_Tx" SG_ 1864 TesterPhysicalResDDM 1;
BA_ "U_T6_MCA_MY2020_Tx" SG_ 1864 TesterPhysicalResDDM 1;
BA_ "U_P702_MY2021_Tx" SG_ 1864 TesterPhysicalResDDM 1;
BA_ "U_CX727_MY2021_Tx" SG_ 1864 TesterPhysicalResDDM 1;
BA_ "GenSigSendType" SG_ 1864 TesterPhysicalResDDM 3;
BA_ "U_CD542_MY2021_Rx" SG_ 1937 TesterPhysicalReqTRM 1;
BA_ "U_T6_MCA_MY2020_Rx" SG_ 1937 TesterPhysicalReqTRM 1;
BA_ "U_P702_MY2021_Rx" SG_ 1937 TesterPhysicalReqTRM 1;
BA_ "GenSigSendType" SG_ 1937 TesterPhysicalReqTRM 3;
BA_ "WakeupSignal" SG_ 947 DimmingLvlEvnt_No_Actl 1;
BA_ "U_CX727_MY2021_Rx" SG_ 947 Backlit_LED_Status 1;
BA_ "U_CD764_MY2022_Rx" SG_ 947 Backlit_LED_Status 1;
BA_ "U_U55X_MY2022_Rx" SG_ 947 Backlit_LED_Status 1;
BA_ "U_CD542_MY2021_Rx" SG_ 947 Backlit_LED_Status 1;
BA_ "U_T6_MCA_MY2020_Rx" SG_ 947 Backlit_LED_Status 1;
BA_ "U_P702_MY2021_Rx" SG_ 947 Backlit_LED_Status 1;
BA_ "WakeupSignal" SG_ 947 Backlit_LED_Status 1;
BA_ "U_CD542_MY2021_Rx" SG_ 947 FogLghtRearOn_B_Stat 1;
BA_ "U_T6_MCA_MY2020_Rx" SG_ 947 FogLghtRearOn_B_Stat 1;
BA_ "U_P702_MY2021_Rx" SG_ 947 FogLghtRearOn_B_Stat 1;
BA_ "U_CD542_MY2021_Rx" SG_ 947 ValetMode_D_Mem 1;
BA_ "U_T6_MCA_MY2020_Rx" SG_ 947 ValetMode_D_Mem 1;
BA_ "U_CX727_MY2021_Rx" SG_ 947 ValetMode_D_Mem 1;
BA_ "U_U55X_MY2022_Rx" SG_ 947 IgnKeyType_D_Actl 1;
BA_ "U_T6_MCA_MY2020_Rx" SG_ 947 IgnKeyType_D_Actl 1;
BA_ "U_P702_MY2021_Rx" SG_ 947 IgnKeyType_D_Actl 1;
BA_ "U_CX727_MY2021_Rx" SG_ 947 IgnKeyType_D_Actl 1;
BA_ "GenSigStartValue" SG_ 947 IgnKeyType_D_Actl 14;
BA_ "GenSigStartValueInteger" SG_ 947 IgnKeyType_D_Actl 14;
BA_ "U_CX727_MY2021_Rx" SG_ 947 TurnLghtRight_D_Rq 1;
BA_ "U_CD764_MY2022_Rx" SG_ 947 TurnLghtRight_D_Rq 1;
BA_ "U_U55X_MY2022_Rx" SG_ 947 TurnLghtRight_D_Rq 1;
BA_ "U_CD542_MY2021_Rx" SG_ 947 TurnLghtRight_D_Rq 1;
BA_ "U_T6_MCA_MY2020_Rx" SG_ 947 TurnLghtRight_D_Rq 1;
BA_ "U_P702_MY2021_Rx" SG_ 947 TurnLghtRight_D_Rq 1;
BA_ "WakeupSignal" SG_ 947 TurnLghtRight_D_Rq 1;
BA_ "U_CD764_MY2022_Rx" SG_ 947 Parklamp_Status 1;
BA_ "U_U55X_MY2022_Rx" SG_ 947 Parklamp_Status 1;
BA_ "U_CD542_MY2021_Rx" SG_ 947 Parklamp_Status 1;
BA_ "U_T6_MCA_MY2020_Rx" SG_ 947 Parklamp_Status 1;
BA_ "U_P702_MY2021_Rx" SG_ 947 Parklamp_Status 1;
BA_ "U_CX727_MY2021_Rx" SG_ 947 Parklamp_Status 1;
BA_ "GenSigStartValue" SG_ 947 Parklamp_Status 1;
BA_ "GenSigStartValueInteger" SG_ 947 Parklamp_Status 1;
BA_ "WakeupSignal" SG_ 947 Parklamp_Status 1;
BA_ "U_CX727_MY2021_Rx" SG_ 947 Litval 1;
BA_ "U_CD764_MY2022_Rx" SG_ 947 Litval 1;
BA_ "U_U55X_MY2022_Rx" SG_ 947 Litval 1;
BA_ "U_CD542_MY2021_Rx" SG_ 947 Litval 1;
BA_ "U_T6_MCA_MY2020_Rx" SG_ 947 Litval 1;
BA_ "U_P702_MY2021_Rx" SG_ 947 Litval 1;
BA_ "WakeupSignal" SG_ 947 Litval 1;
BA_ "U_CD764_MY2022_Rx" SG_ 947 Key_In_Ignition_Stat 1;
BA_ "U_CD542_MY2021_Rx" SG_ 947 Key_In_Ignition_Stat 1;
BA_ "U_U55X_MY2022_Rx" SG_ 947 Key_In_Ignition_Stat 1;
BA_ "U_T6_MCA_MY2020_Rx" SG_ 947 Key_In_Ignition_Stat 1;
BA_ "U_P702_MY2021_Rx" SG_ 947 Key_In_Ignition_Stat 1;
BA_ "U_CX727_MY2021_Rx" SG_ 947 Key_In_Ignition_Stat 1;
BA_ "WakeupSignal" SG_ 947 Key_In_Ignition_Stat 1;
BA_ "U_CX727_MY2021_Rx" SG_ 947 Ignition_Status 1;
BA_ "U_CD764_MY2022_Rx" SG_ 947 Ignition_Status 1;
BA_ "U_U55X_MY2022_Rx" SG_ 947 Ignition_Status 1;
BA_ "U_CD542_MY2021_Rx" SG_ 947 Ignition_Status 1;
BA_ "U_T6_MCA_MY2020_Rx" SG_ 947 Ignition_Status 1;
BA_ "U_P702_MY2021_Rx" SG_ 947 Ignition_Status 1;
BA_ "WakeupSignal" SG_ 947 Ignition_Status 1;
BA_ "U_CX727_MY2021_Rx" SG_ 947 Dimming_Lvl 1;
BA_ "U_CD764_MY2022_Rx" SG_ 947 Dimming_Lvl 1;
BA_ "U_U55X_MY2022_Rx" SG_ 947 Dimming_Lvl 1;
BA_ "U_CD542_MY2021_Rx" SG_ 947 Dimming_Lvl 1;
BA_ "U_T6_MCA_MY2020_Rx" SG_ 947 Dimming_Lvl 1;
BA_ "U_P702_MY2021_Rx" SG_ 947 Dimming_Lvl 1;
BA_ "GenSigStartValue" SG_ 947 Dimming_Lvl 12;
BA_ "GenSigStartValueInteger" SG_ 947 Dimming_Lvl 12;
BA_ "WakeupSignal" SG_ 947 Dimming_Lvl 1;
BA_ "U_CX727_MY2021_Rx" SG_ 947 Day_Night_Status 1;
BA_ "U_CD764_MY2022_Rx" SG_ 947 Day_Night_Status 1;
BA_ "U_U55X_MY2022_Rx" SG_ 947 Day_Night_Status 1;
BA_ "U_CD542_MY2021_Rx" SG_ 947 Day_Night_Status 1;
BA_ "U_T6_MCA_MY2020_Rx" SG_ 947 Day_Night_Status 1;
BA_ "U_P702_MY2021_Rx" SG_ 947 Day_Night_Status 1;
BA_ "WakeupSignal" SG_ 947 Day_Night_Status 1;
BA_ "U_CD764_MY2022_Rx" SG_ 947 Remote_Start_Status 1;
BA_ "U_CD542_MY2021_Rx" SG_ 947 Remote_Start_Status 1;
BA_ "U_U55X_MY2022_Rx" SG_ 947 Remote_Start_Status 1;
BA_ "U_T6_MCA_MY2020_Rx" SG_ 947 Remote_Start_Status 1;
BA_ "U_P702_MY2021_Rx" SG_ 947 Remote_Start_Status 1;
BA_ "U_CX727_MY2021_Rx" SG_ 947 Remote_Start_Status 1;
BA_ "WakeupSignal" SG_ 947 Remote_Start_Status 1;
BA_ "U_CD764_MY2022_Rx" SG_ 947 DrStatTgate_B_Actl 1;
BA_ "U_CD542_MY2021_Rx" SG_ 947 DrStatTgate_B_Actl 1;
BA_ "U_U55X_MY2022_Rx" SG_ 947 DrStatTgate_B_Actl 1;
BA_ "U_T6_MCA_MY2020_Rx" SG_ 947 DrStatTgate_B_Actl 1;
BA_ "U_P702_MY2021_Rx" SG_ 947 DrStatTgate_B_Actl 1;
BA_ "U_CX727_MY2021_Rx" SG_ 947 DrStatTgate_B_Actl 1;
BA_ "WakeupSignal" SG_ 947 DrStatTgate_B_Actl 1;
BA_ "U_CD764_MY2022_Rx" SG_ 947 DrStatRr_B_Actl 1;
BA_ "U_CD542_MY2021_Rx" SG_ 947 DrStatRr_B_Actl 1;
BA_ "U_U55X_MY2022_Rx" SG_ 947 DrStatRr_B_Actl 1;
BA_ "U_T6_MCA_MY2020_Rx" SG_ 947 DrStatRr_B_Actl 1;
BA_ "U_P702_MY2021_Rx" SG_ 947 DrStatRr_B_Actl 1;
BA_ "U_CX727_MY2021_Rx" SG_ 947 DrStatRr_B_Actl 1;
BA_ "WakeupSignal" SG_ 947 DrStatRr_B_Actl 1;
BA_ "U_CD764_MY2022_Rx" SG_ 947 DrStatRl_B_Actl 1;
BA_ "U_CD542_MY2021_Rx" SG_ 947 DrStatRl_B_Actl 1;
BA_ "U_U55X_MY2022_Rx" SG_ 947 DrStatRl_B_Actl 1;
BA_ "U_T6_MCA_MY2020_Rx" SG_ 947 DrStatRl_B_Actl 1;
BA_ "U_P702_MY2021_Rx" SG_ 947 DrStatRl_B_Actl 1;
BA_ "U_CX727_MY2021_Rx" SG_ 947 DrStatRl_B_Actl 1;
BA_ "WakeupSignal" SG_ 947 DrStatRl_B_Actl 1;
BA_ "U_CD764_MY2022_Rx" SG_ 947 DrStatPsngr_B_Actl 1;
BA_ "U_U55X_MY2022_Rx" SG_ 947 DrStatPsngr_B_Actl 1;
BA_ "U_CD542_MY2021_Rx" SG_ 947 DrStatPsngr_B_Actl 1;
BA_ "U_T6_MCA_MY2020_Rx" SG_ 947 DrStatPsngr_B_Actl 1;
BA_ "U_P702_MY2021_Rx" SG_ 947 DrStatPsngr_B_Actl 1;
BA_ "U_CX727_MY2021_Rx" SG_ 947 DrStatPsngr_B_Actl 1;
BA_ "WakeupSignal" SG_ 947 DrStatPsngr_B_Actl 1;
BA_ "U_CD764_MY2022_Rx" SG_ 947 DrStatInnrTgate_B_Actl 1;
BA_ "U_CD542_MY2021_Rx" SG_ 947 DrStatInnrTgate_B_Actl 1;
BA_ "U_U55X_MY2022_Rx" SG_ 947 DrStatInnrTgate_B_Actl 1;
BA_ "U_T6_MCA_MY2020_Rx" SG_ 947 DrStatInnrTgate_B_Actl 1;
BA_ "U_P702_MY2021_Rx" SG_ 947 DrStatInnrTgate_B_Actl 1;
BA_ "U_CX727_MY2021_Rx" SG_ 947 DrStatInnrTgate_B_Actl 1;
BA_ "WakeupSignal" SG_ 947 DrStatInnrTgate_B_Actl 1;
BA_ "U_U55X_MY2022_Rx" SG_ 947 DrStatHood_B_Actl 1;
BA_ "U_T6_MCA_MY2020_Rx" SG_ 947 DrStatHood_B_Actl 1;
BA_ "U_P702_MY2021_Rx" SG_ 947 DrStatHood_B_Actl 1;
BA_ "U_CX727_MY2021_Rx" SG_ 947 DrStatHood_B_Actl 1;
BA_ "WakeupSignal" SG_ 947 DrStatHood_B_Actl 1;
BA_ "U_CD764_MY2022_Rx" SG_ 947 DrStatDrv_B_Actl 1;
BA_ "U_U55X_MY2022_Rx" SG_ 947 DrStatDrv_B_Actl 1;
BA_ "U_CD542_MY2021_Rx" SG_ 947 DrStatDrv_B_Actl 1;
BA_ "U_T6_MCA_MY2020_Rx" SG_ 947 DrStatDrv_B_Actl 1;
BA_ "U_P702_MY2021_Rx" SG_ 947 DrStatDrv_B_Actl 1;
BA_ "U_CX727_MY2021_Rx" SG_ 947 DrStatDrv_B_Actl 1;
BA_ "WakeupSignal" SG_ 947 DrStatDrv_B_Actl 1;
BA_ "U_CX727_MY2021_Rx" SG_ 947 PrkBrkActv_B_Actl 1;
BA_ "ContentDependant" SG_ 947 PrkBrkActv_B_Actl 1;
BA_ "WakeupSignal" SG_ 947 PrkBrkActv_B_Actl 1;
BA_ "U_CX727_MY2021_Rx" SG_ 947 LifeCycMde_D_Actl 1;
BA_ "U_CD764_MY2022_Rx" SG_ 947 LifeCycMde_D_Actl 1;
BA_ "U_U55X_MY2022_Rx" SG_ 947 LifeCycMde_D_Actl 1;
BA_ "U_CD542_MY2021_Rx" SG_ 947 LifeCycMde_D_Actl 1;
BA_ "U_T6_MCA_MY2020_Rx" SG_ 947 LifeCycMde_D_Actl 1;
BA_ "U_P702_MY2021_Rx" SG_ 947 LifeCycMde_D_Actl 1;
BA_ "U_CX727_MY2021_Rx" SG_ 947 Delay_Accy 1;
BA_ "U_CD764_MY2022_Rx" SG_ 947 Delay_Accy 1;
BA_ "U_U55X_MY2022_Rx" SG_ 947 Delay_Accy 1;
BA_ "U_CD542_MY2021_Rx" SG_ 947 Delay_Accy 1;
BA_ "U_P702_MY2021_Rx" SG_ 947 Delay_Accy 1;
BA_ "WakeupSignal" SG_ 947 Delay_Accy 1;
BA_ "U_CX727_MY2021_Rx" SG_ 947 TurnLghtLeft_D_Rq 1;
BA_ "U_CD764_MY2022_Rx" SG_ 947 TurnLghtLeft_D_Rq 1;
BA_ "U_U55X_MY2022_Rx" SG_ 947 TurnLghtLeft_D_Rq 1;
BA_ "U_CD542_MY2021_Rx" SG_ 947 TurnLghtLeft_D_Rq 1;
BA_ "U_T6_MCA_MY2020_Rx" SG_ 947 TurnLghtLeft_D_Rq 1;
BA_ "U_P702_MY2021_Rx" SG_ 947 TurnLghtLeft_D_Rq 1;
BA_ "WakeupSignal" SG_ 947 TurnLghtLeft_D_Rq 1;
BA_ "U_CD764_MY2022_Rx" SG_ 947 CrashEvnt_D_Stat 1;
BA_ "U_U55X_MY2022_Rx" SG_ 947 CrashEvnt_D_Stat 1;
BA_ "U_CX727_MY2021_Rx" SG_ 947 CrashEvnt_D_Stat 1;
BA_ "U_CD542_MY2021_Rx" SG_ 947 CrashEvnt_D_Stat 1;
BA_ "U_T6_MCA_MY2020_Rx" SG_ 947 CrashEvnt_D_Stat 1;
BA_ "U_P702_MY2021_Rx" SG_ 947 CrashEvnt_D_Stat 1;
BA_ "GenSigStartValue" SG_ 947 CrashEvnt_D_Stat 3;
BA_ "GenSigStartValueInteger" SG_ 947 CrashEvnt_D_Stat 3;
BA_ "WakeupSignal" SG_ 947 CrashEvnt_D_Stat 1;
BA_ "U_CD764_MY2022_Rx" SG_ 947 FuelPmpInhbt_B_Stat 1;
BA_ "U_U55X_MY2022_Rx" SG_ 947 FuelPmpInhbt_B_Stat 1;
BA_ "U_CD542_MY2021_Rx" SG_ 947 FuelPmpInhbt_B_Stat 1;
BA_ "U_T6_MCA_MY2020_Rx" SG_ 947 FuelPmpInhbt_B_Stat 1;
BA_ "U_P702_MY2021_Rx" SG_ 947 FuelPmpInhbt_B_Stat 1;
BA_ "U_CX727_MY2021_Rx" SG_ 947 FuelPmpInhbt_B_Stat 1;
BA_ "U_CD764_MY2022_Tx" SG_ 293 ClmtCtrlSeat_SetStat_Psgr 1;
BA_ "U_CD542_MY2021_Tx" SG_ 293 ClmtCtrlSeat_SetStat_Psgr 1;
BA_ "U_T6_MCA_MY2020_Tx" SG_ 293 ClmtCtrlSeat_SetStat_Psgr 1;
BA_ "U_U55X_MY2022_Tx" SG_ 293 ClmtCtrlSeat_SetStat_Psgr 1;
BA_ "U_P702_MY2021_Tx" SG_ 293 ClmtCtrlSeat_SetStat_Psgr 1;
BA_ "U_CD764_MY2022_Rx" SG_ 293 ClmtCtrlSeat_SetStat_Psgr 1;
BA_ "U_U55X_MY2022_Rx" SG_ 293 ClmtCtrlSeat_SetStat_Psgr 1;
BA_ "U_CD542_MY2021_Rx" SG_ 293 ClmtCtrlSeat_SetStat_Psgr 1;
BA_ "U_T6_MCA_MY2020_Rx" SG_ 293 ClmtCtrlSeat_SetStat_Psgr 1;
BA_ "U_CX727_MY2021_Rx" SG_ 293 ClmtCtrlSeat_SetStat_Psgr 1;
BA_ "GenSigSendType" SG_ 293 ClmtCtrlSeat_SetStat_Psgr 3;
BA_ "U_CD764_MY2022_Tx" SG_ 293 ClmtCtrlSeat_SetStat_Dvr 1;
BA_ "U_CD542_MY2021_Tx" SG_ 293 ClmtCtrlSeat_SetStat_Dvr 1;
BA_ "U_T6_MCA_MY2020_Tx" SG_ 293 ClmtCtrlSeat_SetStat_Dvr 1;
BA_ "U_U55X_MY2022_Tx" SG_ 293 ClmtCtrlSeat_SetStat_Dvr 1;
BA_ "U_P702_MY2021_Tx" SG_ 293 ClmtCtrlSeat_SetStat_Dvr 1;
BA_ "U_CD764_MY2022_Rx" SG_ 293 ClmtCtrlSeat_SetStat_Dvr 1;
BA_ "U_U55X_MY2022_Rx" SG_ 293 ClmtCtrlSeat_SetStat_Dvr 1;
BA_ "U_CD542_MY2021_Rx" SG_ 293 ClmtCtrlSeat_SetStat_Dvr 1;
BA_ "U_T6_MCA_MY2020_Rx" SG_ 293 ClmtCtrlSeat_SetStat_Dvr 1;
BA_ "U_CX727_MY2021_Rx" SG_ 293 ClmtCtrlSeat_SetStat_Dvr 1;
BA_ "GenSigSendType" SG_ 293 ClmtCtrlSeat_SetStat_Dvr 3;
BA_ "GenSigSendType" SG_ 1841 TesterPhysicalReqANT 3;
BA_ "U_U55X_MY2022_Rx" SG_ 292 ClimtSeatRr_D_Rq 1;
BA_ "GenSigSendType" SG_ 292 ClimtSeatRr_D_Rq 3;
BA_ "U_U55X_MY2022_Rx" SG_ 292 ClimtSeatRl_D_Rq 1;
BA_ "GenSigSendType" SG_ 292 ClimtSeatRl_D_Rq 3;
BA_ "U_CD764_MY2022_Tx" SG_ 292 ClmtCtrlSeat_SetCmd_Psgr 1;
BA_ "U_U55X_MY2022_Tx" SG_ 292 ClmtCtrlSeat_SetCmd_Psgr 1;
BA_ "U_CD542_MY2021_Tx" SG_ 292 ClmtCtrlSeat_SetCmd_Psgr 1;
BA_ "U_T6_MCA_MY2020_Tx" SG_ 292 ClmtCtrlSeat_SetCmd_Psgr 1;
BA_ "U_P702_MY2021_Tx" SG_ 292 ClmtCtrlSeat_SetCmd_Psgr 1;
BA_ "U_CX727_MY2021_Tx" SG_ 292 ClmtCtrlSeat_SetCmd_Psgr 1;
BA_ "U_CD764_MY2022_Rx" SG_ 292 ClmtCtrlSeat_SetCmd_Psgr 1;
BA_ "U_CD542_MY2021_Rx" SG_ 292 ClmtCtrlSeat_SetCmd_Psgr 1;
BA_ "U_T6_MCA_MY2020_Rx" SG_ 292 ClmtCtrlSeat_SetCmd_Psgr 1;
BA_ "U_U55X_MY2022_Rx" SG_ 292 ClmtCtrlSeat_SetCmd_Psgr 1;
BA_ "U_P702_MY2021_Rx" SG_ 292 ClmtCtrlSeat_SetCmd_Psgr 1;
BA_ "GenSigSendType" SG_ 292 ClmtCtrlSeat_SetCmd_Psgr 3;
BA_ "U_CD764_MY2022_Tx" SG_ 292 ClmtCtrlSeat_SetCmd_Dvr 1;
BA_ "U_U55X_MY2022_Tx" SG_ 292 ClmtCtrlSeat_SetCmd_Dvr 1;
BA_ "U_CD542_MY2021_Tx" SG_ 292 ClmtCtrlSeat_SetCmd_Dvr 1;
BA_ "U_T6_MCA_MY2020_Tx" SG_ 292 ClmtCtrlSeat_SetCmd_Dvr 1;
BA_ "U_P702_MY2021_Tx" SG_ 292 ClmtCtrlSeat_SetCmd_Dvr 1;
BA_ "U_CX727_MY2021_Tx" SG_ 292 ClmtCtrlSeat_SetCmd_Dvr 1;
BA_ "U_CD764_MY2022_Rx" SG_ 292 ClmtCtrlSeat_SetCmd_Dvr 1;
BA_ "U_CD542_MY2021_Rx" SG_ 292 ClmtCtrlSeat_SetCmd_Dvr 1;
BA_ "U_T6_MCA_MY2020_Rx" SG_ 292 ClmtCtrlSeat_SetCmd_Dvr 1;
BA_ "U_U55X_MY2022_Rx" SG_ 292 ClmtCtrlSeat_SetCmd_Dvr 1;
BA_ "U_P702_MY2021_Rx" SG_ 292 ClmtCtrlSeat_SetCmd_Dvr 1;
BA_ "GenSigSendType" SG_ 292 ClmtCtrlSeat_SetCmd_Dvr 3;
BA_ "U_U55X_MY2022_Rx" SG_ 1126 GpsUtcYr_No_Actl 1;
BA_ "U_U55X_MY2022_Rx" SG_ 1126 GpsUtcMnth_No_Actl 1;
BA_ "GenSigStartValue" SG_ 1126 GpsUtcMnth_No_Actl 1;
BA_ "GenSigStartValueInteger" SG_ 1126 GpsUtcMnth_No_Actl 1;
BA_ "U_U55X_MY2022_Rx" SG_ 1126 GpsUtcDay_No_Actl 1;
BA_ "GenSigStartValue" SG_ 1126 GpsUtcDay_No_Actl 1;
BA_ "GenSigStartValueInteger" SG_ 1126 GpsUtcDay_No_Actl 1;
BA_ "U_U55X_MY2022_Rx" SG_ 1126 GPS_UTC_seconds 1;
BA_ "U_U55X_MY2022_Rx" SG_ 1126 GPS_UTC_minutes 1;
BA_ "U_U55X_MY2022_Rx" SG_ 1126 GPS_UTC_hours 1;
BA_ "U_U55X_MY2022_Rx" SG_ 1126 GPS_Pdop 1;
BA_ "U_U55X_MY2022_Rx" SG_ 1126 GPS_Compass_direction 1;
BA_ "U_U55X_MY2022_Rx" SG_ 1126 GPS_Actual_vs_Infer_pos 1;
BA_ "GenSigSendType" SG_ 1126 GPS_Actual_vs_Infer_pos 1;
BA_ "U_U55X_MY2022_Rx" SG_ 1126 Gps_B_Falt 1;
BA_ "U_U55X_MY2022_Rx" SG_ 1125 GpsHsphLongEast_D_Actl 1;
BA_ "GenSigSendType" SG_ 1125 GpsHsphLongEast_D_Actl 1;
BA_ "U_U55X_MY2022_Rx" SG_ 1125 GpsHsphLattSth_D_Actl 1;
BA_ "U_U55X_MY2022_Rx" SG_ 1125 GPS_Longitude_Minutes 1;
BA_ "U_U55X_MY2022_Rx" SG_ 1125 GPS_Longitude_Min_dec 1;
BA_ "U_U55X_MY2022_Rx" SG_ 1125 GPS_Longitude_Degrees 1;
BA_ "GenSigStartValueInteger" SG_ 1125 GPS_Longitude_Degrees 179;
BA_ "U_U55X_MY2022_Rx" SG_ 1125 GPS_Latitude_Minutes 1;
BA_ "U_U55X_MY2022_Rx" SG_ 1125 GPS_Latitude_Min_dec 1;
BA_ "U_U55X_MY2022_Rx" SG_ 1125 GPS_Latitude_Degrees 1;
BA_ "U_CD764_MY2022_Rx" SG_ 992 MsgCntrPersIndex_D_Rq 1;
BA_ "U_U55X_MY2022_Rx" SG_ 992 MsgCntrPersIndex_D_Rq 1;
BA_ "U_CD542_MY2021_Rx" SG_ 992 MsgCntrPersIndex_D_Rq 1;
BA_ "U_T6_MCA_MY2020_Rx" SG_ 992 MsgCntrPersIndex_D_Rq 1;
BA_ "U_P702_MY2021_Rx" SG_ 992 MsgCntrPersIndex_D_Rq 1;
BA_ "U_CX727_MY2021_Rx" SG_ 992 MsgCntrPersIndex_D_Rq 1;
BA_ "GenSigStartValue" SG_ 992 MsgCntrPersIndex_D_Rq 4;
BA_ "GenSigStartValueInteger" SG_ 992 MsgCntrPersIndex_D_Rq 4;
BA_ "U_CD764_MY2022_Rx" SG_ 992 MsgCntrFeatConfigRq 1;
BA_ "U_U55X_MY2022_Rx" SG_ 992 MsgCntrFeatConfigRq 1;
BA_ "U_CD542_MY2021_Rx" SG_ 992 MsgCntrFeatConfigRq 1;
BA_ "U_T6_MCA_MY2020_Rx" SG_ 992 MsgCntrFeatConfigRq 1;
BA_ "U_P702_MY2021_Rx" SG_ 992 MsgCntrFeatConfigRq 1;
BA_ "U_CX727_MY2021_Rx" SG_ 992 MsgCntrFeatConfigRq 1;
BA_ "U_CD764_MY2022_Rx" SG_ 992 MsgCntrFeatNoRq 1;
BA_ "U_U55X_MY2022_Rx" SG_ 992 MsgCntrFeatNoRq 1;
BA_ "U_CD542_MY2021_Rx" SG_ 992 MsgCntrFeatNoRq 1;
BA_ "U_T6_MCA_MY2020_Rx" SG_ 992 MsgCntrFeatNoRq 1;
BA_ "U_P702_MY2021_Rx" SG_ 992 MsgCntrFeatNoRq 1;
BA_ "U_CX727_MY2021_Rx" SG_ 992 MsgCntrFeatNoRq 1;
BA_ "U_CD764_MY2022_Rx" SG_ 992 MsgCntrDsplyOp_D_Rq 1;
BA_ "U_U55X_MY2022_Rx" SG_ 992 MsgCntrDsplyOp_D_Rq 1;
BA_ "U_CD542_MY2021_Rx" SG_ 992 MsgCntrDsplyOp_D_Rq 1;
BA_ "U_T6_MCA_MY2020_Rx" SG_ 992 MsgCntrDsplyOp_D_Rq 1;
BA_ "U_P702_MY2021_Rx" SG_ 992 MsgCntrDsplyOp_D_Rq 1;
BA_ "U_CX727_MY2021_Rx" SG_ 992 MsgCntrDsplyOp_D_Rq 1;
BA_ "U_U55X_MY2022_Rx" SG_ 1127 GPS_Vdop 1;
BA_ "GenSigSendType" SG_ 1127 GPS_Vdop 1;
BA_ "U_U55X_MY2022_Rx" SG_ 1127 GPS_Speed 1;
BA_ "U_U55X_MY2022_Rx" SG_ 1127 GPS_Sat_num_in_view 1;
BA_ "U_U55X_MY2022_Rx" SG_ 1127 GPS_MSL_altitude 1;
BA_ "U_U55X_MY2022_Rx" SG_ 1127 GPS_Heading 1;
BA_ "U_U55X_MY2022_Rx" SG_ 1127 GPS_Hdop 1;
BA_ "U_U55X_MY2022_Rx" SG_ 1127 GPS_dimension 1;
BA_ "U_CD764_MY2022_Rx" SG_ 861 SteWhlHeat_D_Stat 1;
BA_ "U_U55X_MY2022_Rx" SG_ 861 SteWhlHeat_D_Stat 1;
BA_ "U_CD542_MY2021_Rx" SG_ 861 SteWhlHeat_D_Stat 1;
BA_ "U_CX727_MY2021_Rx" SG_ 861 SteWhlHeat_D_Stat 1;
BA_ "GenSigSendType" SG_ 861 SteWhlHeat_D_Stat 3;
BA_ "U_U55X_MY2022_Tx" SG_ 1919 TesterPhysicalResSCMF 1;
BA_ "GenSigSendType" SG_ 1919 TesterPhysicalResSCMF 3;
BA_ "U_U55X_MY2022_Rx" SG_ 1911 TesterPhysicalReqSCMF 1;
BA_ "GenSigSendType" SG_ 1911 TesterPhysicalReqSCMF 3;
BA_ "U_CD764_MY2022_Tx" SG_ 999 FeatNoFcimActl 1;
BA_ "U_U55X_MY2022_Tx" SG_ 999 FeatNoFcimActl 1;
BA_ "U_CD542_MY2021_Tx" SG_ 999 FeatNoFcimActl 1;
BA_ "U_T6_MCA_MY2020_Tx" SG_ 999 FeatNoFcimActl 1;
BA_ "U_P702_MY2021_Tx" SG_ 999 FeatNoFcimActl 1;
BA_ "U_CX727_MY2021_Tx" SG_ 999 FeatNoFcimActl 1;
BA_ "GenSigSendType" SG_ 999 FeatNoFcimActl 3;
BA_ "U_CD764_MY2022_Tx" SG_ 999 FeatConfigFcimActl 1;
BA_ "U_U55X_MY2022_Tx" SG_ 999 FeatConfigFcimActl 1;
BA_ "U_CD542_MY2021_Tx" SG_ 999 FeatConfigFcimActl 1;
BA_ "U_T6_MCA_MY2020_Tx" SG_ 999 FeatConfigFcimActl 1;
BA_ "U_P702_MY2021_Tx" SG_ 999 FeatConfigFcimActl 1;
BA_ "U_CX727_MY2021_Tx" SG_ 999 FeatConfigFcimActl 1;
BA_ "GenSigSendType" SG_ 999 FeatConfigFcimActl 3;
BA_ "U_CD764_MY2022_Tx" SG_ 999 PersIndexFcim_D_Actl 1;
BA_ "U_U55X_MY2022_Tx" SG_ 999 PersIndexFcim_D_Actl 1;
BA_ "U_CD542_MY2021_Tx" SG_ 999 PersIndexFcim_D_Actl 1;
BA_ "U_T6_MCA_MY2020_Tx" SG_ 999 PersIndexFcim_D_Actl 1;
BA_ "U_P702_MY2021_Tx" SG_ 999 PersIndexFcim_D_Actl 1;
BA_ "U_CX727_MY2021_Tx" SG_ 999 PersIndexFcim_D_Actl 1;
BA_ "GenSigSendType" SG_ 999 PersIndexFcim_D_Actl 3;
BA_ "GenSigStartValue" SG_ 999 PersIndexFcim_D_Actl 4;
BA_ "GenSigStartValueInteger" SG_ 999 PersIndexFcim_D_Actl 4;
BA_ "GenSigSendType" SG_ 2027 TesterPhysicalResAHCM 3;
BA_ "GenSigSendType" SG_ 2019 TesterPhysicalReqAHCM 3;
BA_ "U_U55X_MY2022_Tx" SG_ 862 ApaSwtch_No_Cnt 1;
BA_ "U_T6_MCA_MY2020_Tx" SG_ 862 ApaSwtch_No_Cnt 1;
BA_ "MetaData" SG_ 862 ApaSwtch_No_Cnt 1;
BA_ "U_U55X_MY2022_Tx" SG_ 862 ApaSwtch_D_RqDrv 1;
BA_ "U_T6_MCA_MY2020_Tx" SG_ 862 ApaSwtch_D_RqDrv 1;
BA_ "GenSigSendType" SG_ 862 ApaSwtch_D_RqDrv 3;
BA_ "U_CD764_MY2022_Tx" SG_ 862 HvacBlwrFront_D_Stat 1;
BA_ "U_U55X_MY2022_Tx" SG_ 862 HvacBlwrFront_D_Stat 1;
BA_ "U_CD542_MY2021_Tx" SG_ 862 HvacBlwrFront_D_Stat 1;
BA_ "U_T6_MCA_MY2020_Tx" SG_ 862 HvacBlwrFront_D_Stat 1;
BA_ "U_P702_MY2021_Tx" SG_ 862 HvacBlwrFront_D_Stat 1;
BA_ "U_CX727_MY2021_Tx" SG_ 862 HvacBlwrFront_D_Stat 1;
BA_ "U_CX727_MY2021_Rx" SG_ 862 HvacBlwrFront_D_Stat 1;
BA_ "U_CD764_MY2022_Rx" SG_ 862 HvacBlwrFront_D_Stat 1;
BA_ "U_U55X_MY2022_Rx" SG_ 862 HvacBlwrFront_D_Stat 1;
BA_ "U_CD542_MY2021_Rx" SG_ 862 HvacBlwrFront_D_Stat 1;
BA_ "U_T6_MCA_MY2020_Rx" SG_ 862 HvacBlwrFront_D_Stat 1;
BA_ "U_P702_MY2021_Rx" SG_ 862 HvacBlwrFront_D_Stat 1;
BA_ "GenSigSendType" SG_ 862 HvacBlwrFront_D_Stat 3;
BA_ "U_T6_MCA_MY2020_Tx" SG_ 862 HvacBlwrRear_D_Stat 1;
BA_ "U_U55X_MY2022_Tx" SG_ 862 HvacBlwrRear_D_Stat 1;
BA_ "U_U55X_MY2022_Rx" SG_ 862 HvacBlwrRear_D_Stat 1;
BA_ "GenSigSendType" SG_ 862 HvacBlwrRear_D_Stat 3;
BA_ "U_CD764_MY2022_Tx" SG_ 862 HvacRemoteStrt_N_Rq 1;
BA_ "U_U55X_MY2022_Tx" SG_ 862 HvacRemoteStrt_N_Rq 1;
BA_ "U_CD542_MY2021_Tx" SG_ 862 HvacRemoteStrt_N_Rq 1;
BA_ "U_T6_MCA_MY2020_Tx" SG_ 862 HvacRemoteStrt_N_Rq 1;
BA_ "U_CX727_MY2021_Tx" SG_ 862 HvacRemoteStrt_N_Rq 1;
BA_ "GenSigSendType" SG_ 862 HvacRemoteStrt_N_Rq 3;
BA_ "U_CD764_MY2022_Tx" SG_ 862 EcoMde_D_RqDrv 1;
BA_ "U_U55X_MY2022_Tx" SG_ 862 EcoMde_D_RqDrv 1;
BA_ "U_CD542_MY2021_Tx" SG_ 862 EcoMde_D_RqDrv 1;
BA_ "U_T6_MCA_MY2020_Tx" SG_ 862 EcoMde_D_RqDrv 1;
BA_ "U_CX727_MY2021_Tx" SG_ 862 EcoMde_D_RqDrv 1;
BA_ "GenSigSendType" SG_ 862 EcoMde_D_RqDrv 3;
BA_ "U_CD764_MY2022_Tx" SG_ 862 ClimtThrmlLoad_No_Actl 1;
BA_ "U_U55X_MY2022_Tx" SG_ 862 ClimtThrmlLoad_No_Actl 1;
BA_ "U_CD542_MY2021_Tx" SG_ 862 ClimtThrmlLoad_No_Actl 1;
BA_ "U_T6_MCA_MY2020_Tx" SG_ 862 ClimtThrmlLoad_No_Actl 1;
BA_ "U_P702_MY2021_Tx" SG_ 862 ClimtThrmlLoad_No_Actl 1;
BA_ "U_CX727_MY2021_Tx" SG_ 862 ClimtThrmlLoad_No_Actl 1;
BA_ "GenSigSendType" SG_ 862 ClimtThrmlLoad_No_Actl 3;
BA_ "GenSigStartValue" SG_ 862 ClimtThrmlLoad_No_Actl 255;
BA_ "GenSigStartValueInteger" SG_ 862 ClimtThrmlLoad_No_Actl 255;
BA_ "U_CD764_MY2022_Tx" SG_ 862 HvacRec_Pc_Est 1;
BA_ "U_U55X_MY2022_Tx" SG_ 862 HvacRec_Pc_Est 1;
BA_ "U_CD542_MY2021_Tx" SG_ 862 HvacRec_Pc_Est 1;
BA_ "U_T6_MCA_MY2020_Tx" SG_ 862 HvacRec_Pc_Est 1;
BA_ "U_P702_MY2021_Tx" SG_ 862 HvacRec_Pc_Est 1;
BA_ "U_CX727_MY2021_Tx" SG_ 862 HvacRec_Pc_Est 1;
BA_ "GenSigSendType" SG_ 862 HvacRec_Pc_Est 3;
BA_ "U_CD764_MY2022_Tx" SG_ 862 HvacAir_Flw_Est 1;
BA_ "U_U55X_MY2022_Tx" SG_ 862 HvacAir_Flw_Est 1;
BA_ "U_CD542_MY2021_Tx" SG_ 862 HvacAir_Flw_Est 1;
BA_ "U_T6_MCA_MY2020_Tx" SG_ 862 HvacAir_Flw_Est 1;
BA_ "U_P702_MY2021_Tx" SG_ 862 HvacAir_Flw_Est 1;
BA_ "U_CX727_MY2021_Tx" SG_ 862 HvacAir_Flw_Est 1;
BA_ "GenSigSendType" SG_ 862 HvacAir_Flw_Est 3;
BA_ "U_CD764_MY2022_Tx" SG_ 862 CamraDefog_B_Actl 1;
BA_ "U_U55X_MY2022_Tx" SG_ 862 CamraDefog_B_Actl 1;
BA_ "U_CD542_MY2021_Tx" SG_ 862 CamraDefog_B_Actl 1;
BA_ "U_T6_MCA_MY2020_Tx" SG_ 862 CamraDefog_B_Actl 1;
BA_ "U_CX727_MY2021_Tx" SG_ 862 CamraDefog_B_Actl 1;
BA_ "GenSigSendType" SG_ 862 CamraDefog_B_Actl 3;
BA_ "U_CD764_MY2022_Tx" SG_ 862 CabnAmb_Te_Actl 1;
BA_ "U_U55X_MY2022_Tx" SG_ 862 CabnAmb_Te_Actl 1;
BA_ "U_CD542_MY2021_Tx" SG_ 862 CabnAmb_Te_Actl 1;
BA_ "U_T6_MCA_MY2020_Tx" SG_ 862 CabnAmb_Te_Actl 1;
BA_ "U_P702_MY2021_Tx" SG_ 862 CabnAmb_Te_Actl 1;
BA_ "U_CX727_MY2021_Tx" SG_ 862 CabnAmb_Te_Actl 1;
BA_ "U_P702_MY2021_Rx" SG_ 862 CabnAmb_Te_Actl 1;
BA_ "U_CD542_MY2021_Rx" SG_ 862 CabnAmb_Te_Actl 1;
BA_ "U_T6_MCA_MY2020_Rx" SG_ 862 CabnAmb_Te_Actl 1;
BA_ "U_CX727_MY2021_Rx" SG_ 862 CabnAmb_Te_Actl 1;
BA_ "U_CD764_MY2022_Rx" SG_ 862 CabnAmb_Te_Actl 1;
BA_ "U_U55X_MY2022_Rx" SG_ 862 CabnAmb_Te_Actl 1;
BA_ "GenSigSendType" SG_ 862 CabnAmb_Te_Actl 3;
BA_ "GenSigStartValueInteger" SG_ 862 CabnAmb_Te_Actl 114;
BA_ "U_CD764_MY2022_Tx" SG_ 862 AutoStpHvacDelta_I_Est 1;
BA_ "U_U55X_MY2022_Tx" SG_ 862 AutoStpHvacDelta_I_Est 1;
BA_ "U_CD542_MY2021_Tx" SG_ 862 AutoStpHvacDelta_I_Est 1;
BA_ "U_T6_MCA_MY2020_Tx" SG_ 862 AutoStpHvacDelta_I_Est 1;
BA_ "U_CX727_MY2021_Tx" SG_ 862 AutoStpHvacDelta_I_Est 1;
BA_ "GenSigSendType" SG_ 862 AutoStpHvacDelta_I_Est 3;
BA_ "GenSigStartValueInteger" SG_ 862 AutoStpHvacDelta_I_Est 192;
BA_ "U_CD764_MY2022_Tx" SG_ 828 DrvSpotLight_B_Rq 1;
BA_ "U_T6_MCA_MY2020_Tx" SG_ 828 DrvSpotLight_B_Rq 1;
BA_ "U_CD764_MY2022_Rx" SG_ 828 DrvSpotLight_B_Rq 1;
BA_ "U_CD542_MY2021_Rx" SG_ 828 DrvSpotLight_B_Rq 1;
BA_ "U_T6_MCA_MY2020_Rx" SG_ 828 DrvSpotLight_B_Rq 1;
BA_ "GenSigSendType" SG_ 828 DrvSpotLight_B_Rq 3;
BA_ "U_CD764_MY2022_Tx" SG_ 828 SpotLghtRight_D_Stat 1;
BA_ "U_T6_MCA_MY2020_Tx" SG_ 828 SpotLghtRight_D_Stat 1;
BA_ "U_CD764_MY2022_Rx" SG_ 828 SpotLghtRight_D_Stat 1;
BA_ "U_U55X_MY2022_Rx" SG_ 828 SpotLghtRight_D_Stat 1;
BA_ "U_CD542_MY2021_Rx" SG_ 828 SpotLghtRight_D_Stat 1;
BA_ "ECGUsedRxSignal" SG_ 828 SpotLghtRight_D_Stat 1;
BA_ "U_T6_MCA_MY2020_Rx" SG_ 828 SpotLghtRight_D_Stat 1;
BA_ "GenSigSendType" SG_ 828 SpotLghtRight_D_Stat 3;
BA_ "U_CD764_MY2022_Tx" SG_ 828 RearPassWindowPos 1;
BA_ "U_U55X_MY2022_Tx" SG_ 828 RearPassWindowPos 1;
BA_ "U_CD542_MY2021_Tx" SG_ 828 RearPassWindowPos 1;
BA_ "U_T6_MCA_MY2020_Tx" SG_ 828 RearPassWindowPos 1;
BA_ "U_P702_MY2021_Tx" SG_ 828 RearPassWindowPos 1;
BA_ "ECGUsedRxSignal" SG_ 828 RearPassWindowPos 1;
BA_ "U_CD764_MY2022_Rx" SG_ 828 RearPassWindowPos 1;
BA_ "U_U55X_MY2022_Rx" SG_ 828 RearPassWindowPos 1;
BA_ "U_CD542_MY2021_Rx" SG_ 828 RearPassWindowPos 1;
BA_ "U_T6_MCA_MY2020_Rx" SG_ 828 RearPassWindowPos 1;
BA_ "U_P702_MY2021_Rx" SG_ 828 RearPassWindowPos 1;
BA_ "U_CX727_MY2021_Rx" SG_ 828 RearPassWindowPos 1;
BA_ "GenSigSendType" SG_ 828 RearPassWindowPos 3;
BA_ "WakeupSignal" SG_ 828 RearPassWindowPos 1;
BA_ "U_CD764_MY2022_Tx" SG_ 828 PassWindowPosition 1;
BA_ "U_U55X_MY2022_Tx" SG_ 828 PassWindowPosition 1;
BA_ "U_CD542_MY2021_Tx" SG_ 828 PassWindowPosition 1;
BA_ "U_T6_MCA_MY2020_Tx" SG_ 828 PassWindowPosition 1;
BA_ "U_P702_MY2021_Tx" SG_ 828 PassWindowPosition 1;
BA_ "ECGUsedRxSignal" SG_ 828 PassWindowPosition 1;
BA_ "U_CD764_MY2022_Rx" SG_ 828 PassWindowPosition 1;
BA_ "U_U55X_MY2022_Rx" SG_ 828 PassWindowPosition 1;
BA_ "U_CD542_MY2021_Rx" SG_ 828 PassWindowPosition 1;
BA_ "U_T6_MCA_MY2020_Rx" SG_ 828 PassWindowPosition 1;
BA_ "U_P702_MY2021_Rx" SG_ 828 PassWindowPosition 1;
BA_ "U_CX727_MY2021_Rx" SG_ 828 PassWindowPosition 1;
BA_ "GenSigSendType" SG_ 828 PassWindowPosition 3;
BA_ "WakeupSignal" SG_ 828 PassWindowPosition 1;
BA_ "U_CD764_MY2022_Tx" SG_ 828 SpotLghtLeft_D_Stat 1;
BA_ "U_T6_MCA_MY2020_Tx" SG_ 828 SpotLghtLeft_D_Stat 1;
BA_ "U_CD764_MY2022_Rx" SG_ 828 SpotLghtLeft_D_Stat 1;
BA_ "U_U55X_MY2022_Rx" SG_ 828 SpotLghtLeft_D_Stat 1;
BA_ "U_CD542_MY2021_Rx" SG_ 828 SpotLghtLeft_D_Stat 1;
BA_ "ECGUsedRxSignal" SG_ 828 SpotLghtLeft_D_Stat 1;
BA_ "U_T6_MCA_MY2020_Rx" SG_ 828 SpotLghtLeft_D_Stat 1;
BA_ "GenSigSendType" SG_ 828 SpotLghtLeft_D_Stat 3;
BA_ "U_U55X_MY2022_Rx" SG_ 1894 TesterPhysicalReqRBM 1;
BA_ "U_P702_MY2021_Rx" SG_ 1894 TesterPhysicalReqRBM 1;
BA_ "GenSigSendType" SG_ 1894 TesterPhysicalReqRBM 3;
BA_ "U_U55X_MY2022_Rx" SG_ 1909 TesterPhysicalReqRGTM 1;
BA_ "U_CD542_MY2021_Rx" SG_ 1909 TesterPhysicalReqRGTM 1;
BA_ "U_T6_MCA_MY2020_Rx" SG_ 1909 TesterPhysicalReqRGTM 1;
BA_ "U_CX727_MY2021_Rx" SG_ 1909 TesterPhysicalReqRGTM 1;
BA_ "GenSigSendType" SG_ 1909 TesterPhysicalReqRGTM 3;
BA_ "U_U55X_MY2022_Tx" SG_ 1917 TesterPhysicalResRGTM 1;
BA_ "U_CD542_MY2021_Tx" SG_ 1917 TesterPhysicalResRGTM 1;
BA_ "U_T6_MCA_MY2020_Tx" SG_ 1917 TesterPhysicalResRGTM 1;
BA_ "U_CX727_MY2021_Tx" SG_ 1917 TesterPhysicalResRGTM 1;
BA_ "GenSigSendType" SG_ 1917 TesterPhysicalResRGTM 3;
BA_ "U_U55X_MY2022_Tx" SG_ 1902 TesterPhysicalResRBM 1;
BA_ "U_P702_MY2021_Tx" SG_ 1902 TesterPhysicalResRBM 1;
BA_ "GenSigSendType" SG_ 1902 TesterPhysicalResRBM 3;
BA_ "U_CD764_MY2022_Rx" SG_ 1860 TesterPhysicalReqDSM 1;
BA_ "U_U55X_MY2022_Rx" SG_ 1860 TesterPhysicalReqDSM 1;
BA_ "U_CD542_MY2021_Rx" SG_ 1860 TesterPhysicalReqDSM 1;
BA_ "U_T6_MCA_MY2020_Rx" SG_ 1860 TesterPhysicalReqDSM 1;
BA_ "U_P702_MY2021_Rx" SG_ 1860 TesterPhysicalReqDSM 1;
BA_ "U_CX727_MY2021_Rx" SG_ 1860 TesterPhysicalReqDSM 1;
BA_ "GenSigSendType" SG_ 1860 TesterPhysicalReqDSM 3;
BA_ "U_CD764_MY2022_Tx" SG_ 1868 TesterPhysicalResDSM 1;
BA_ "U_U55X_MY2022_Tx" SG_ 1868 TesterPhysicalResDSM 1;
BA_ "U_CD542_MY2021_Tx" SG_ 1868 TesterPhysicalResDSM 1;
BA_ "U_T6_MCA_MY2020_Tx" SG_ 1868 TesterPhysicalResDSM 1;
BA_ "U_P702_MY2021_Tx" SG_ 1868 TesterPhysicalResDSM 1;
BA_ "U_CX727_MY2021_Tx" SG_ 1868 TesterPhysicalResDSM 1;
BA_ "GenSigSendType" SG_ 1868 TesterPhysicalResDSM 3;
BA_ "U_U55X_MY2022_Tx" SG_ 1918 TesterPhysicalResSCME 1;
BA_ "U_P702_MY2021_Tx" SG_ 1918 TesterPhysicalResSCME 1;
BA_ "GenSigSendType" SG_ 1918 TesterPhysicalResSCME 3;
BA_ "U_U55X_MY2022_Rx" SG_ 1910 TesterPhysicalReqSCME 1;
BA_ "U_P702_MY2021_Rx" SG_ 1910 TesterPhysicalReqSCME 1;
BA_ "GenSigSendType" SG_ 1910 TesterPhysicalReqSCME 3;
BA_ "U_CD764_MY2022_Rx" SG_ 1814 TesterPhysicalReqGWM_M1 1;
BA_ "U_U55X_MY2022_Rx" SG_ 1814 TesterPhysicalReqGWM_M1 1;
BA_ "U_CD542_MY2021_Rx" SG_ 1814 TesterPhysicalReqGWM_M1 1;
BA_ "ECGUsedRxSignal" SG_ 1814 TesterPhysicalReqGWM_M1 1;
BA_ "U_T6_MCA_MY2020_Rx" SG_ 1814 TesterPhysicalReqGWM_M1 1;
BA_ "GenSigSendType" SG_ 1814 TesterPhysicalReqGWM_M1 3;
BA_ "U_CD764_MY2022_Tx" SG_ 1822 TesterPhysicalResGWM_M1 1;
BA_ "U_U55X_MY2022_Tx" SG_ 1822 TesterPhysicalResGWM_M1 1;
BA_ "U_CD542_MY2021_Tx" SG_ 1822 TesterPhysicalResGWM_M1 1;
BA_ "ECGUsedTxSignal" SG_ 1822 TesterPhysicalResGWM_M1 1;
BA_ "U_T6_MCA_MY2020_Tx" SG_ 1822 TesterPhysicalResGWM_M1 1;
BA_ "GenSigSendType" SG_ 1822 TesterPhysicalResGWM_M1 3;
BA_ "U_CD764_MY2022_Tx" SG_ 826 Memory_3_Sw_Stat 1;
BA_ "U_U55X_MY2022_Tx" SG_ 826 Memory_3_Sw_Stat 1;
BA_ "U_CD542_MY2021_Tx" SG_ 826 Memory_3_Sw_Stat 1;
BA_ "U_T6_MCA_MY2020_Tx" SG_ 826 Memory_3_Sw_Stat 1;
BA_ "U_P702_MY2021_Tx" SG_ 826 Memory_3_Sw_Stat 1;
BA_ "U_CX727_MY2021_Tx" SG_ 826 Memory_3_Sw_Stat 1;
BA_ "U_CD764_MY2022_Rx" SG_ 826 Memory_3_Sw_Stat 1;
BA_ "U_CD542_MY2021_Rx" SG_ 826 Memory_3_Sw_Stat 1;
BA_ "U_T6_MCA_MY2020_Rx" SG_ 826 Memory_3_Sw_Stat 1;
BA_ "U_P702_MY2021_Rx" SG_ 826 Memory_3_Sw_Stat 1;
BA_ "U_CX727_MY2021_Rx" SG_ 826 Memory_3_Sw_Stat 1;
BA_ "GenSigSendType" SG_ 826 Memory_3_Sw_Stat 3;
BA_ "WakeupSignal" SG_ 826 Memory_3_Sw_Stat 1;
BA_ "U_CD764_MY2022_Tx" SG_ 826 Memory_2_Sw_Stat 1;
BA_ "U_U55X_MY2022_Tx" SG_ 826 Memory_2_Sw_Stat 1;
BA_ "U_CD542_MY2021_Tx" SG_ 826 Memory_2_Sw_Stat 1;
BA_ "U_T6_MCA_MY2020_Tx" SG_ 826 Memory_2_Sw_Stat 1;
BA_ "U_P702_MY2021_Tx" SG_ 826 Memory_2_Sw_Stat 1;
BA_ "U_CX727_MY2021_Tx" SG_ 826 Memory_2_Sw_Stat 1;
BA_ "U_CD764_MY2022_Rx" SG_ 826 Memory_2_Sw_Stat 1;
BA_ "U_CD542_MY2021_Rx" SG_ 826 Memory_2_Sw_Stat 1;
BA_ "U_T6_MCA_MY2020_Rx" SG_ 826 Memory_2_Sw_Stat 1;
BA_ "U_P702_MY2021_Rx" SG_ 826 Memory_2_Sw_Stat 1;
BA_ "U_CX727_MY2021_Rx" SG_ 826 Memory_2_Sw_Stat 1;
BA_ "GenSigSendType" SG_ 826 Memory_2_Sw_Stat 3;
BA_ "WakeupSignal" SG_ 826 Memory_2_Sw_Stat 1;
BA_ "U_CD764_MY2022_Tx" SG_ 826 Memory_1_Sw_Stat 1;
BA_ "U_U55X_MY2022_Tx" SG_ 826 Memory_1_Sw_Stat 1;
BA_ "U_CD542_MY2021_Tx" SG_ 826 Memory_1_Sw_Stat 1;
BA_ "U_T6_MCA_MY2020_Tx" SG_ 826 Memory_1_Sw_Stat 1;
BA_ "U_P702_MY2021_Tx" SG_ 826 Memory_1_Sw_Stat 1;
BA_ "U_CX727_MY2021_Tx" SG_ 826 Memory_1_Sw_Stat 1;
BA_ "U_CD764_MY2022_Rx" SG_ 826 Memory_1_Sw_Stat 1;
BA_ "U_CD542_MY2021_Rx" SG_ 826 Memory_1_Sw_Stat 1;
BA_ "U_T6_MCA_MY2020_Rx" SG_ 826 Memory_1_Sw_Stat 1;
BA_ "U_P702_MY2021_Rx" SG_ 826 Memory_1_Sw_Stat 1;
BA_ "U_CX727_MY2021_Rx" SG_ 826 Memory_1_Sw_Stat 1;
BA_ "GenSigSendType" SG_ 826 Memory_1_Sw_Stat 3;
BA_ "WakeupSignal" SG_ 826 Memory_1_Sw_Stat 1;
BA_ "U_CD764_MY2022_Tx" SG_ 826 Mirror_Manual_Override 1;
BA_ "U_U55X_MY2022_Tx" SG_ 826 Mirror_Manual_Override 1;
BA_ "U_CD542_MY2021_Tx" SG_ 826 Mirror_Manual_Override 1;
BA_ "U_T6_MCA_MY2020_Tx" SG_ 826 Mirror_Manual_Override 1;
BA_ "U_P702_MY2021_Tx" SG_ 826 Mirror_Manual_Override 1;
BA_ "U_CX727_MY2021_Tx" SG_ 826 Mirror_Manual_Override 1;
BA_ "U_CD764_MY2022_Rx" SG_ 826 Mirror_Manual_Override 1;
BA_ "U_CD542_MY2021_Rx" SG_ 826 Mirror_Manual_Override 1;
BA_ "U_T6_MCA_MY2020_Rx" SG_ 826 Mirror_Manual_Override 1;
BA_ "U_P702_MY2021_Rx" SG_ 826 Mirror_Manual_Override 1;
BA_ "U_CX727_MY2021_Rx" SG_ 826 Mirror_Manual_Override 1;
BA_ "GenSigSendType" SG_ 826 Mirror_Manual_Override 3;
BA_ "WakeupSignal" SG_ 826 Mirror_Manual_Override 1;
BA_ "U_P702_MY2021_Rx" SG_ 1289 AHCM_Network_Mgmt 1;
BA_ "GenSigSendType" SG_ 1289 AHCM_Network_Mgmt 3;
BA_ "U_T6_MCA_MY2020_Tx" SG_ 1098 TrlrAidSwtch_D_RqDrv 1;
BA_ "U_P702_MY2021_Tx" SG_ 1098 TrlrAidSwtch_D_RqDrv 1;
BA_ "U_T6_MCA_MY2020_Tx" SG_ 1098 TrlrAidCtl_U_RqDrv 1;
BA_ "U_P702_MY2021_Tx" SG_ 1098 TrlrAidCtl_U_RqDrv 1;
BA_ "GenSigStartValue" SG_ 1098 TrlrAidCtl_U_RqDrv 4093;
BA_ "GenSigStartValueInteger" SG_ 1098 TrlrAidCtl_U_RqDrv 4094;
BA_ "GenSigSendType" SG_ 1326 SFMB_Network_Mgmt 3;
BA_ "GenSigSendType" SG_ 1325 SFMA_Network_Mgmt 3;
BA_ "U_U55X_MY2022_Tx" SG_ 1802 TesterPhysicalResSCMC 1;
BA_ "GenSigSendType" SG_ 1802 TesterPhysicalResSCMC 3;
BA_ "U_U55X_MY2022_Tx" SG_ 1385 SCMD_Network_Mgmt 1;
BA_ "GenSigSendType" SG_ 1385 SCMD_Network_Mgmt 3;
BA_ "U_U55X_MY2022_Tx" SG_ 1306 SCMC_Network_Mgmt 1;
BA_ "GenSigSendType" SG_ 1306 SCMC_Network_Mgmt 3;
BA_ "U_U55X_MY2022_Tx" SG_ 1115 ClimtSeatRr_D_Stat 1;
BA_ "GenSigSendType" SG_ 1115 ClimtSeatRr_D_Stat 3;
BA_ "U_U55X_MY2022_Tx" SG_ 1115 ClimtSeatRl_D_Stat 1;
BA_ "GenSigSendType" SG_ 1115 ClimtSeatRl_D_Stat 3;
BA_ "U_U55X_MY2022_Tx" SG_ 853 MdeMnu_Buttn_Stat 1;
BA_ "U_CD542_MY2021_Tx" SG_ 853 MdeMnu_Buttn_Stat 1;
BA_ "U_T6_MCA_MY2020_Tx" SG_ 853 MdeMnu_Buttn_Stat 1;
BA_ "U_P702_MY2021_Tx" SG_ 853 MdeMnu_Buttn_Stat 1;
BA_ "U_CX727_MY2021_Tx" SG_ 853 MdeMnu_Buttn_Stat 1;
BA_ "GenSigSendType" SG_ 853 MdeMnu_Buttn_Stat 3;
BA_ "U_CD764_MY2022_Tx" SG_ 853 Front_AUTO_Blwr_Lvl 1;
BA_ "U_U55X_MY2022_Tx" SG_ 853 Front_AUTO_Blwr_Lvl 1;
BA_ "U_CD542_MY2021_Tx" SG_ 853 Front_AUTO_Blwr_Lvl 1;
BA_ "U_T6_MCA_MY2020_Tx" SG_ 853 Front_AUTO_Blwr_Lvl 1;
BA_ "U_P702_MY2021_Tx" SG_ 853 Front_AUTO_Blwr_Lvl 1;
BA_ "U_CX727_MY2021_Tx" SG_ 853 Front_AUTO_Blwr_Lvl 1;
BA_ "GenSigSendType" SG_ 853 Front_AUTO_Blwr_Lvl 3;
BA_ "U_U55X_MY2022_Tx" SG_ 853 RearMnu_Buttn_Stat 1;
BA_ "U_CD542_MY2021_Tx" SG_ 853 RearMnu_Buttn_Stat 1;
BA_ "U_P702_MY2021_Tx" SG_ 853 RearMnu_Buttn_Stat 1;
BA_ "GenSigSendType" SG_ 853 RearMnu_Buttn_Stat 3;
BA_ "U_CD764_MY2022_Tx" SG_ 853 FrontMnu_Buttn_Stat 1;
BA_ "U_U55X_MY2022_Tx" SG_ 853 FrontMnu_Buttn_Stat 1;
BA_ "U_CD542_MY2021_Tx" SG_ 853 FrontMnu_Buttn_Stat 1;
BA_ "U_T6_MCA_MY2020_Tx" SG_ 853 FrontMnu_Buttn_Stat 1;
BA_ "U_P702_MY2021_Tx" SG_ 853 FrontMnu_Buttn_Stat 1;
BA_ "U_CX727_MY2021_Tx" SG_ 853 FrontMnu_Buttn_Stat 1;
BA_ "GenSigSendType" SG_ 853 FrontMnu_Buttn_Stat 3;
BA_ "U_CD764_MY2022_Tx" SG_ 853 DrvrFcsdMde_Btn_Stt 1;
BA_ "U_U55X_MY2022_Tx" SG_ 853 DrvrFcsdMde_Btn_Stt 1;
BA_ "U_CD542_MY2021_Tx" SG_ 853 DrvrFcsdMde_Btn_Stt 1;
BA_ "U_T6_MCA_MY2020_Tx" SG_ 853 DrvrFcsdMde_Btn_Stt 1;
BA_ "GenSigSendType" SG_ 853 DrvrFcsdMde_Btn_Stt 3;
BA_ "GenSigStartValue" SG_ 853 DrvrFcsdMde_Btn_Stt 2;
BA_ "U_CD764_MY2022_Tx" SG_ 853 RHS_Cond_Seat_Status 1;
BA_ "U_U55X_MY2022_Tx" SG_ 853 RHS_Cond_Seat_Status 1;
BA_ "U_CD542_MY2021_Tx" SG_ 853 RHS_Cond_Seat_Status 1;
BA_ "U_T6_MCA_MY2020_Tx" SG_ 853 RHS_Cond_Seat_Status 1;
BA_ "U_P702_MY2021_Tx" SG_ 853 RHS_Cond_Seat_Status 1;
BA_ "U_CX727_MY2021_Tx" SG_ 853 RHS_Cond_Seat_Status 1;
BA_ "GenSigSendType" SG_ 853 RHS_Cond_Seat_Status 3;
BA_ "U_CD764_MY2022_Tx" SG_ 853 LHS_Cond_Seat_Status 1;
BA_ "U_U55X_MY2022_Tx" SG_ 853 LHS_Cond_Seat_Status 1;
BA_ "U_CD542_MY2021_Tx" SG_ 853 LHS_Cond_Seat_Status 1;
BA_ "U_T6_MCA_MY2020_Tx" SG_ 853 LHS_Cond_Seat_Status 1;
BA_ "U_P702_MY2021_Tx" SG_ 853 LHS_Cond_Seat_Status 1;
BA_ "U_CX727_MY2021_Tx" SG_ 853 LHS_Cond_Seat_Status 1;
BA_ "GenSigSendType" SG_ 853 LHS_Cond_Seat_Status 3;
BA_ "U_CD764_MY2022_Tx" SG_ 853 Htd_Strg_Whl_Status 1;
BA_ "U_U55X_MY2022_Tx" SG_ 853 Htd_Strg_Whl_Status 1;
BA_ "U_CD542_MY2021_Tx" SG_ 853 Htd_Strg_Whl_Status 1;
BA_ "U_T6_MCA_MY2020_Tx" SG_ 853 Htd_Strg_Whl_Status 1;
BA_ "U_P702_MY2021_Tx" SG_ 853 Htd_Strg_Whl_Status 1;
BA_ "U_CX727_MY2021_Tx" SG_ 853 Htd_Strg_Whl_Status 1;
BA_ "GenSigSendType" SG_ 853 Htd_Strg_Whl_Status 3;
BA_ "GenSigStartValue" SG_ 853 Htd_Strg_Whl_Status 2;
BA_ "GenSigStartValueInteger" SG_ 853 Htd_Strg_Whl_Status 2;
BA_ "U_CD764_MY2022_Tx" SG_ 853 Htd_Strg_Whl_Btn_Stt 1;
BA_ "U_U55X_MY2022_Tx" SG_ 853 Htd_Strg_Whl_Btn_Stt 1;
BA_ "U_CD542_MY2021_Tx" SG_ 853 Htd_Strg_Whl_Btn_Stt 1;
BA_ "U_T6_MCA_MY2020_Tx" SG_ 853 Htd_Strg_Whl_Btn_Stt 1;
BA_ "U_P702_MY2021_Tx" SG_ 853 Htd_Strg_Whl_Btn_Stt 1;
BA_ "U_CX727_MY2021_Tx" SG_ 853 Htd_Strg_Whl_Btn_Stt 1;
BA_ "GenSigSendType" SG_ 853 Htd_Strg_Whl_Btn_Stt 3;
BA_ "GenSigStartValue" SG_ 853 Htd_Strg_Whl_Btn_Stt 2;
BA_ "GenSigStartValueInteger" SG_ 853 Htd_Strg_Whl_Btn_Stt 2;
BA_ "U_CD764_MY2022_Tx" SG_ 853 Defrost_Btn_Stt 1;
BA_ "U_U55X_MY2022_Tx" SG_ 853 Defrost_Btn_Stt 1;
BA_ "U_CD542_MY2021_Tx" SG_ 853 Defrost_Btn_Stt 1;
BA_ "U_T6_MCA_MY2020_Tx" SG_ 853 Defrost_Btn_Stt 1;
BA_ "U_P702_MY2021_Tx" SG_ 853 Defrost_Btn_Stt 1;
BA_ "U_CX727_MY2021_Tx" SG_ 853 Defrost_Btn_Stt 1;
BA_ "GenSigSendType" SG_ 853 Defrost_Btn_Stt 3;
BA_ "GenSigStartValue" SG_ 853 Defrost_Btn_Stt 2;
BA_ "GenSigStartValueInteger" SG_ 853 Defrost_Btn_Stt 2;
BA_ "U_CD764_MY2022_Tx" SG_ 853 CC_Fr_Btn_User_Adj 1;
BA_ "U_U55X_MY2022_Tx" SG_ 853 CC_Fr_Btn_User_Adj 1;
BA_ "U_CD542_MY2021_Tx" SG_ 853 CC_Fr_Btn_User_Adj 1;
BA_ "U_T6_MCA_MY2020_Tx" SG_ 853 CC_Fr_Btn_User_Adj 1;
BA_ "U_P702_MY2021_Tx" SG_ 853 CC_Fr_Btn_User_Adj 1;
BA_ "U_CX727_MY2021_Tx" SG_ 853 CC_Fr_Btn_User_Adj 1;
BA_ "GenSigSendType" SG_ 853 CC_Fr_Btn_User_Adj 3;
BA_ "U_CD764_MY2022_Tx" SG_ 853 RHS_Htd_Seat_Btn_Stt 1;
BA_ "U_U55X_MY2022_Tx" SG_ 853 RHS_Htd_Seat_Btn_Stt 1;
BA_ "U_CD542_MY2021_Tx" SG_ 853 RHS_Htd_Seat_Btn_Stt 1;
BA_ "U_T6_MCA_MY2020_Tx" SG_ 853 RHS_Htd_Seat_Btn_Stt 1;
BA_ "U_P702_MY2021_Tx" SG_ 853 RHS_Htd_Seat_Btn_Stt 1;
BA_ "U_CX727_MY2021_Tx" SG_ 853 RHS_Htd_Seat_Btn_Stt 1;
BA_ "GenSigSendType" SG_ 853 RHS_Htd_Seat_Btn_Stt 3;
BA_ "GenSigStartValue" SG_ 853 RHS_Htd_Seat_Btn_Stt 2;
BA_ "GenSigStartValueInteger" SG_ 853 RHS_Htd_Seat_Btn_Stt 2;
BA_ "U_CD764_MY2022_Tx" SG_ 853 RHS_Cld_Seat_Btn_Stt 1;
BA_ "U_U55X_MY2022_Tx" SG_ 853 RHS_Cld_Seat_Btn_Stt 1;
BA_ "U_CD542_MY2021_Tx" SG_ 853 RHS_Cld_Seat_Btn_Stt 1;
BA_ "U_T6_MCA_MY2020_Tx" SG_ 853 RHS_Cld_Seat_Btn_Stt 1;
BA_ "U_P702_MY2021_Tx" SG_ 853 RHS_Cld_Seat_Btn_Stt 1;
BA_ "U_CX727_MY2021_Tx" SG_ 853 RHS_Cld_Seat_Btn_Stt 1;
BA_ "GenSigSendType" SG_ 853 RHS_Cld_Seat_Btn_Stt 3;
BA_ "GenSigStartValue" SG_ 853 RHS_Cld_Seat_Btn_Stt 2;
BA_ "GenSigStartValueInteger" SG_ 853 RHS_Cld_Seat_Btn_Stt 2;
BA_ "U_CD764_MY2022_Tx" SG_ 853 Outside_Btn_Stt 1;
BA_ "U_U55X_MY2022_Tx" SG_ 853 Outside_Btn_Stt 1;
BA_ "U_CD542_MY2021_Tx" SG_ 853 Outside_Btn_Stt 1;
BA_ "U_T6_MCA_MY2020_Tx" SG_ 853 Outside_Btn_Stt 1;
BA_ "U_P702_MY2021_Tx" SG_ 853 Outside_Btn_Stt 1;
BA_ "U_CX727_MY2021_Tx" SG_ 853 Outside_Btn_Stt 1;
BA_ "GenSigSendType" SG_ 853 Outside_Btn_Stt 3;
BA_ "GenSigStartValue" SG_ 853 Outside_Btn_Stt 2;
BA_ "GenSigStartValueInteger" SG_ 853 Outside_Btn_Stt 2;
BA_ "U_CD764_MY2022_Tx" SG_ 853 LHS_Htd_Seat_Btn_Stt 1;
BA_ "U_U55X_MY2022_Tx" SG_ 853 LHS_Htd_Seat_Btn_Stt 1;
BA_ "U_CD542_MY2021_Tx" SG_ 853 LHS_Htd_Seat_Btn_Stt 1;
BA_ "U_T6_MCA_MY2020_Tx" SG_ 853 LHS_Htd_Seat_Btn_Stt 1;
BA_ "U_P702_MY2021_Tx" SG_ 853 LHS_Htd_Seat_Btn_Stt 1;
BA_ "U_CX727_MY2021_Tx" SG_ 853 LHS_Htd_Seat_Btn_Stt 1;
BA_ "GenSigSendType" SG_ 853 LHS_Htd_Seat_Btn_Stt 3;
BA_ "GenSigStartValue" SG_ 853 LHS_Htd_Seat_Btn_Stt 2;
BA_ "GenSigStartValueInteger" SG_ 853 LHS_Htd_Seat_Btn_Stt 2;
BA_ "U_CD764_MY2022_Tx" SG_ 853 LHS_Cld_Seat_Btn_Stt 1;
BA_ "U_U55X_MY2022_Tx" SG_ 853 LHS_Cld_Seat_Btn_Stt 1;
BA_ "U_CD542_MY2021_Tx" SG_ 853 LHS_Cld_Seat_Btn_Stt 1;
BA_ "U_T6_MCA_MY2020_Tx" SG_ 853 LHS_Cld_Seat_Btn_Stt 1;
BA_ "U_P702_MY2021_Tx" SG_ 853 LHS_Cld_Seat_Btn_Stt 1;
BA_ "U_CX727_MY2021_Tx" SG_ 853 LHS_Cld_Seat_Btn_Stt 1;
BA_ "GenSigSendType" SG_ 853 LHS_Cld_Seat_Btn_Stt 3;
BA_ "GenSigStartValue" SG_ 853 LHS_Cld_Seat_Btn_Stt 2;
BA_ "GenSigStartValueInteger" SG_ 853 LHS_Cld_Seat_Btn_Stt 2;
BA_ "U_CD764_MY2022_Tx" SG_ 853 Htd_Frt_Wsh_Btn_Stt 1;
BA_ "U_U55X_MY2022_Tx" SG_ 853 Htd_Frt_Wsh_Btn_Stt 1;
BA_ "U_CD542_MY2021_Tx" SG_ 853 Htd_Frt_Wsh_Btn_Stt 1;
BA_ "U_T6_MCA_MY2020_Tx" SG_ 853 Htd_Frt_Wsh_Btn_Stt 1;
BA_ "U_P702_MY2021_Tx" SG_ 853 Htd_Frt_Wsh_Btn_Stt 1;
BA_ "U_CX727_MY2021_Tx" SG_ 853 Htd_Frt_Wsh_Btn_Stt 1;
BA_ "GenSigSendType" SG_ 853 Htd_Frt_Wsh_Btn_Stt 3;
BA_ "GenSigStartValue" SG_ 853 Htd_Frt_Wsh_Btn_Stt 2;
BA_ "GenSigStartValueInteger" SG_ 853 Htd_Frt_Wsh_Btn_Stt 2;
BA_ "U_CD764_MY2022_Tx" SG_ 853 Auto_Recirc_Btn_Stt 1;
BA_ "U_U55X_MY2022_Tx" SG_ 853 Auto_Recirc_Btn_Stt 1;
BA_ "U_CD542_MY2021_Tx" SG_ 853 Auto_Recirc_Btn_Stt 1;
BA_ "U_T6_MCA_MY2020_Tx" SG_ 853 Auto_Recirc_Btn_Stt 1;
BA_ "U_P702_MY2021_Tx" SG_ 853 Auto_Recirc_Btn_Stt 1;
BA_ "U_CX727_MY2021_Tx" SG_ 853 Auto_Recirc_Btn_Stt 1;
BA_ "GenSigSendType" SG_ 853 Auto_Recirc_Btn_Stt 3;
BA_ "GenSigStartValue" SG_ 853 Auto_Recirc_Btn_Stt 2;
BA_ "GenSigStartValueInteger" SG_ 853 Auto_Recirc_Btn_Stt 2;
BA_ "U_CD764_MY2022_Tx" SG_ 853 Recirc_Btn_Stt 1;
BA_ "U_U55X_MY2022_Tx" SG_ 853 Recirc_Btn_Stt 1;
BA_ "U_CD542_MY2021_Tx" SG_ 853 Recirc_Btn_Stt 1;
BA_ "U_T6_MCA_MY2020_Tx" SG_ 853 Recirc_Btn_Stt 1;
BA_ "U_P702_MY2021_Tx" SG_ 853 Recirc_Btn_Stt 1;
BA_ "U_CX727_MY2021_Tx" SG_ 853 Recirc_Btn_Stt 1;
BA_ "U_CD542_MY2021_Rx" SG_ 853 Recirc_Btn_Stt 1;
BA_ "U_T6_MCA_MY2020_Rx" SG_ 853 Recirc_Btn_Stt 1;
BA_ "U_CX727_MY2021_Rx" SG_ 853 Recirc_Btn_Stt 1;
BA_ "GenSigSendType" SG_ 853 Recirc_Btn_Stt 3;
BA_ "GenSigStartValue" SG_ 853 Recirc_Btn_Stt 2;
BA_ "GenSigStartValueInteger" SG_ 853 Recirc_Btn_Stt 2;
BA_ "U_CD764_MY2022_Tx" SG_ 853 Rear_Defrost_Btn_Stt 1;
BA_ "U_U55X_MY2022_Tx" SG_ 853 Rear_Defrost_Btn_Stt 1;
BA_ "U_CD542_MY2021_Tx" SG_ 853 Rear_Defrost_Btn_Stt 1;
BA_ "U_T6_MCA_MY2020_Tx" SG_ 853 Rear_Defrost_Btn_Stt 1;
BA_ "U_P702_MY2021_Tx" SG_ 853 Rear_Defrost_Btn_Stt 1;
BA_ "U_CX727_MY2021_Tx" SG_ 853 Rear_Defrost_Btn_Stt 1;
BA_ "GenSigSendType" SG_ 853 Rear_Defrost_Btn_Stt 3;
BA_ "GenSigStartValue" SG_ 853 Rear_Defrost_Btn_Stt 2;
BA_ "GenSigStartValueInteger" SG_ 853 Rear_Defrost_Btn_Stt 2;
BA_ "U_CD764_MY2022_Tx" SG_ 853 My_Temp_Btn_Stt 1;
BA_ "U_U55X_MY2022_Tx" SG_ 853 My_Temp_Btn_Stt 1;
BA_ "U_CD542_MY2021_Tx" SG_ 853 My_Temp_Btn_Stt 1;
BA_ "U_T6_MCA_MY2020_Tx" SG_ 853 My_Temp_Btn_Stt 1;
BA_ "U_P702_MY2021_Tx" SG_ 853 My_Temp_Btn_Stt 1;
BA_ "U_CX727_MY2021_Tx" SG_ 853 My_Temp_Btn_Stt 1;
BA_ "GenSigSendType" SG_ 853 My_Temp_Btn_Stt 3;
BA_ "GenSigStartValue" SG_ 853 My_Temp_Btn_Stt 2;
BA_ "GenSigStartValueInteger" SG_ 853 My_Temp_Btn_Stt 2;
BA_ "U_CD764_MY2022_Tx" SG_ 853 Max_Defrost_Btn_Stt 1;
BA_ "U_U55X_MY2022_Tx" SG_ 853 Max_Defrost_Btn_Stt 1;
BA_ "U_CD542_MY2021_Tx" SG_ 853 Max_Defrost_Btn_Stt 1;
BA_ "U_T6_MCA_MY2020_Tx" SG_ 853 Max_Defrost_Btn_Stt 1;
BA_ "U_P702_MY2021_Tx" SG_ 853 Max_Defrost_Btn_Stt 1;
BA_ "U_CX727_MY2021_Tx" SG_ 853 Max_Defrost_Btn_Stt 1;
BA_ "GenSigSendType" SG_ 853 Max_Defrost_Btn_Stt 3;
BA_ "GenSigStartValue" SG_ 853 Max_Defrost_Btn_Stt 2;
BA_ "GenSigStartValueInteger" SG_ 853 Max_Defrost_Btn_Stt 2;
BA_ "U_CD764_MY2022_Tx" SG_ 853 Max_AC_Btn_Stt 1;
BA_ "U_U55X_MY2022_Tx" SG_ 853 Max_AC_Btn_Stt 1;
BA_ "U_CD542_MY2021_Tx" SG_ 853 Max_AC_Btn_Stt 1;
BA_ "U_T6_MCA_MY2020_Tx" SG_ 853 Max_AC_Btn_Stt 1;
BA_ "U_P702_MY2021_Tx" SG_ 853 Max_AC_Btn_Stt 1;
BA_ "U_CX727_MY2021_Tx" SG_ 853 Max_AC_Btn_Stt 1;
BA_ "GenSigSendType" SG_ 853 Max_AC_Btn_Stt 3;
BA_ "GenSigStartValue" SG_ 853 Max_AC_Btn_Stt 2;
BA_ "GenSigStartValueInteger" SG_ 853 Max_AC_Btn_Stt 2;
BA_ "U_CD764_MY2022_Tx" SG_ 853 Front_AUTO_Label 1;
BA_ "U_U55X_MY2022_Tx" SG_ 853 Front_AUTO_Label 1;
BA_ "U_CD542_MY2021_Tx" SG_ 853 Front_AUTO_Label 1;
BA_ "U_T6_MCA_MY2020_Tx" SG_ 853 Front_AUTO_Label 1;
BA_ "U_P702_MY2021_Tx" SG_ 853 Front_AUTO_Label 1;
BA_ "U_CX727_MY2021_Tx" SG_ 853 Front_AUTO_Label 1;
BA_ "GenSigSendType" SG_ 853 Front_AUTO_Label 3;
BA_ "GenSigStartValue" SG_ 853 Front_AUTO_Label 2;
BA_ "GenSigStartValueInteger" SG_ 853 Front_AUTO_Label 2;
BA_ "U_CD764_MY2022_Tx" SG_ 853 Windscreen_Btn_Stt 1;
BA_ "U_U55X_MY2022_Tx" SG_ 853 Windscreen_Btn_Stt 1;
BA_ "U_CD542_MY2021_Tx" SG_ 853 Windscreen_Btn_Stt 1;
BA_ "U_T6_MCA_MY2020_Tx" SG_ 853 Windscreen_Btn_Stt 1;
BA_ "U_P702_MY2021_Tx" SG_ 853 Windscreen_Btn_Stt 1;
BA_ "U_CX727_MY2021_Tx" SG_ 853 Windscreen_Btn_Stt 1;
BA_ "GenSigSendType" SG_ 853 Windscreen_Btn_Stt 3;
BA_ "GenSigStartValue" SG_ 853 Windscreen_Btn_Stt 2;
BA_ "GenSigStartValueInteger" SG_ 853 Windscreen_Btn_Stt 2;
BA_ "U_CD764_MY2022_Tx" SG_ 853 Panel_Btn_Stt 1;
BA_ "U_U55X_MY2022_Tx" SG_ 853 Panel_Btn_Stt 1;
BA_ "U_CD542_MY2021_Tx" SG_ 853 Panel_Btn_Stt 1;
BA_ "U_T6_MCA_MY2020_Tx" SG_ 853 Panel_Btn_Stt 1;
BA_ "U_P702_MY2021_Tx" SG_ 853 Panel_Btn_Stt 1;
BA_ "U_CX727_MY2021_Tx" SG_ 853 Panel_Btn_Stt 1;
BA_ "GenSigSendType" SG_ 853 Panel_Btn_Stt 3;
BA_ "GenSigStartValue" SG_ 853 Panel_Btn_Stt 2;
BA_ "GenSigStartValueInteger" SG_ 853 Panel_Btn_Stt 2;
BA_ "U_CD764_MY2022_Tx" SG_ 853 Front_Power_Btn_Stt 1;
BA_ "U_U55X_MY2022_Tx" SG_ 853 Front_Power_Btn_Stt 1;
BA_ "U_CD542_MY2021_Tx" SG_ 853 Front_Power_Btn_Stt 1;
BA_ "U_T6_MCA_MY2020_Tx" SG_ 853 Front_Power_Btn_Stt 1;
BA_ "U_P702_MY2021_Tx" SG_ 853 Front_Power_Btn_Stt 1;
BA_ "U_CX727_MY2021_Tx" SG_ 853 Front_Power_Btn_Stt 1;
BA_ "GenSigSendType" SG_ 853 Front_Power_Btn_Stt 3;
BA_ "GenSigStartValue" SG_ 853 Front_Power_Btn_Stt 2;
BA_ "GenSigStartValueInteger" SG_ 853 Front_Power_Btn_Stt 2;
BA_ "U_CD764_MY2022_Tx" SG_ 853 Front_AUTO_Btn_Stt 1;
BA_ "U_U55X_MY2022_Tx" SG_ 853 Front_AUTO_Btn_Stt 1;
BA_ "U_CD542_MY2021_Tx" SG_ 853 Front_AUTO_Btn_Stt 1;
BA_ "U_T6_MCA_MY2020_Tx" SG_ 853 Front_AUTO_Btn_Stt 1;
BA_ "U_P702_MY2021_Tx" SG_ 853 Front_AUTO_Btn_Stt 1;
BA_ "U_CX727_MY2021_Tx" SG_ 853 Front_AUTO_Btn_Stt 1;
BA_ "GenSigSendType" SG_ 853 Front_AUTO_Btn_Stt 3;
BA_ "GenSigStartValue" SG_ 853 Front_AUTO_Btn_Stt 2;
BA_ "GenSigStartValueInteger" SG_ 853 Front_AUTO_Btn_Stt 2;
BA_ "U_CD764_MY2022_Tx" SG_ 853 Floor_Btn_Stt 1;
BA_ "U_U55X_MY2022_Tx" SG_ 853 Floor_Btn_Stt 1;
BA_ "U_CD542_MY2021_Tx" SG_ 853 Floor_Btn_Stt 1;
BA_ "U_T6_MCA_MY2020_Tx" SG_ 853 Floor_Btn_Stt 1;
BA_ "U_P702_MY2021_Tx" SG_ 853 Floor_Btn_Stt 1;
BA_ "U_CX727_MY2021_Tx" SG_ 853 Floor_Btn_Stt 1;
BA_ "GenSigSendType" SG_ 853 Floor_Btn_Stt 3;
BA_ "GenSigStartValue" SG_ 853 Floor_Btn_Stt 2;
BA_ "GenSigStartValueInteger" SG_ 853 Floor_Btn_Stt 2;
BA_ "U_CD764_MY2022_Tx" SG_ 853 Dual_Button_Stt 1;
BA_ "U_U55X_MY2022_Tx" SG_ 853 Dual_Button_Stt 1;
BA_ "U_CD542_MY2021_Tx" SG_ 853 Dual_Button_Stt 1;
BA_ "U_T6_MCA_MY2020_Tx" SG_ 853 Dual_Button_Stt 1;
BA_ "U_P702_MY2021_Tx" SG_ 853 Dual_Button_Stt 1;
BA_ "U_CX727_MY2021_Tx" SG_ 853 Dual_Button_Stt 1;
BA_ "GenSigSendType" SG_ 853 Dual_Button_Stt 3;
BA_ "GenSigStartValue" SG_ 853 Dual_Button_Stt 2;
BA_ "GenSigStartValueInteger" SG_ 853 Dual_Button_Stt 2;
BA_ "U_CD764_MY2022_Tx" SG_ 853 AC_Btn_Stt 1;
BA_ "U_U55X_MY2022_Tx" SG_ 853 AC_Btn_Stt 1;
BA_ "U_CD542_MY2021_Tx" SG_ 853 AC_Btn_Stt 1;
BA_ "U_T6_MCA_MY2020_Tx" SG_ 853 AC_Btn_Stt 1;
BA_ "U_P702_MY2021_Tx" SG_ 853 AC_Btn_Stt 1;
BA_ "U_CX727_MY2021_Tx" SG_ 853 AC_Btn_Stt 1;
BA_ "GenSigSendType" SG_ 853 AC_Btn_Stt 3;
BA_ "GenSigStartValue" SG_ 853 AC_Btn_Stt 2;
BA_ "GenSigStartValueInteger" SG_ 853 AC_Btn_Stt 2;
BA_ "U_CD764_MY2022_Rx" SG_ 1034 VehicleGGCCData 1;
BA_ "U_P702_MY2021_Rx" SG_ 1034 VehicleGGCCData 1;
BA_ "U_U55X_MY2022_Rx" SG_ 1034 VehicleGGCCData 1;
BA_ "U_CD542_MY2021_Rx" SG_ 1034 VehicleGGCCData 1;
BA_ "U_T6_MCA_MY2020_Rx" SG_ 1034 VehicleGGCCData 1;
BA_ "U_CX727_MY2021_Rx" SG_ 1034 VehicleGGCCData 1;
BA_ "U_CD764_MY2022_Rx" SG_ 956 PwSrcULoFalt_D_Stat_UB 1;
BA_ "U_U55X_MY2022_Rx" SG_ 956 PwSrcULoFalt_D_Stat_UB 1;
BA_ "U_CD542_MY2021_Rx" SG_ 956 PwSrcULoFalt_D_Stat_UB 1;
BA_ "U_T6_MCA_MY2020_Rx" SG_ 956 PwSrcULoFalt_D_Stat_UB 1;
BA_ "U_P702_MY2021_Rx" SG_ 956 PwSrcULoFalt_D_Stat_UB 1;
BA_ "U_CX727_MY2021_Rx" SG_ 956 PwSrcULoFalt_D_Stat_UB 1;
BA_ "U_CD764_MY2022_Rx" SG_ 956 PwSrcULo_Pc_Mx_UB 1;
BA_ "U_U55X_MY2022_Rx" SG_ 956 PwSrcULo_Pc_Mx_UB 1;
BA_ "U_CD542_MY2021_Rx" SG_ 956 PwSrcULo_Pc_Mx_UB 1;
BA_ "U_T6_MCA_MY2020_Rx" SG_ 956 PwSrcULo_Pc_Mx_UB 1;
BA_ "U_P702_MY2021_Rx" SG_ 956 PwSrcULo_Pc_Mx_UB 1;
BA_ "U_CX727_MY2021_Rx" SG_ 956 PwSrcULo_Pc_Mx_UB 1;
BA_ "U_CD764_MY2022_Rx" SG_ 956 PwSrcULo_Pc_Mx 1;
BA_ "U_U55X_MY2022_Rx" SG_ 956 PwSrcULo_Pc_Mx 1;
BA_ "U_CD542_MY2021_Rx" SG_ 956 PwSrcULo_Pc_Mx 1;
BA_ "U_T6_MCA_MY2020_Rx" SG_ 956 PwSrcULo_Pc_Mx 1;
BA_ "U_P702_MY2021_Rx" SG_ 956 PwSrcULo_Pc_Mx 1;
BA_ "U_CX727_MY2021_Rx" SG_ 956 PwSrcULo_Pc_Mx 1;
BA_ "U_CD764_MY2022_Rx" SG_ 956 WndwFrontHeat_B_Rq_UB 1;
BA_ "U_U55X_MY2022_Rx" SG_ 956 WndwFrontHeat_B_Rq_UB 1;
BA_ "U_CD542_MY2021_Rx" SG_ 956 WndwFrontHeat_B_Rq_UB 1;
BA_ "U_CX727_MY2021_Rx" SG_ 956 WndwFrontHeat_B_Rq_UB 1;
BA_ "U_CD764_MY2022_Rx" SG_ 956 WndwFrontHeat_B_Rq 1;
BA_ "U_U55X_MY2022_Rx" SG_ 956 WndwFrontHeat_B_Rq 1;
BA_ "U_CD542_MY2021_Rx" SG_ 956 WndwFrontHeat_B_Rq 1;
BA_ "U_CX727_MY2021_Rx" SG_ 956 WndwFrontHeat_B_Rq 1;
BA_ "U_CD764_MY2022_Rx" SG_ 956 BattTrac_Te_Actl_UB 1;
BA_ "U_U55X_MY2022_Rx" SG_ 956 BattTrac_Te_Actl_UB 1;
BA_ "U_CD542_MY2021_Rx" SG_ 956 BattTrac_Te_Actl_UB 1;
BA_ "U_T6_MCA_MY2020_Rx" SG_ 956 BattTrac_Te_Actl_UB 1;
BA_ "U_CX727_MY2021_Rx" SG_ 956 BattTrac_Te_Actl_UB 1;
BA_ "U_CD764_MY2022_Rx" SG_ 956 BattTrac_Te_Actl 1;
BA_ "U_U55X_MY2022_Rx" SG_ 956 BattTrac_Te_Actl 1;
BA_ "U_CD542_MY2021_Rx" SG_ 956 BattTrac_Te_Actl 1;
BA_ "U_T6_MCA_MY2020_Rx" SG_ 956 BattTrac_Te_Actl 1;
BA_ "U_CX727_MY2021_Rx" SG_ 956 BattTrac_Te_Actl 1;
BA_ "GenSigStartValue" SG_ 956 BattTrac_Te_Actl 150;
BA_ "GenSigStartValueInteger" SG_ 956 BattTrac_Te_Actl 150;
BA_ "U_CD764_MY2022_Rx" SG_ 956 PwSrcULoFalt_D_Stat 1;
BA_ "U_U55X_MY2022_Rx" SG_ 956 PwSrcULoFalt_D_Stat 1;
BA_ "U_CD542_MY2021_Rx" SG_ 956 PwSrcULoFalt_D_Stat 1;
BA_ "U_T6_MCA_MY2020_Rx" SG_ 956 PwSrcULoFalt_D_Stat 1;
BA_ "U_P702_MY2021_Rx" SG_ 956 PwSrcULoFalt_D_Stat 1;
BA_ "U_CX727_MY2021_Rx" SG_ 956 PwSrcULoFalt_D_Stat 1;
BA_ "U_CD764_MY2022_Rx" SG_ 956 PrkBrkStatus 1;
BA_ "U_U55X_MY2022_Rx" SG_ 956 PrkBrkStatus 1;
BA_ "U_CD542_MY2021_Rx" SG_ 956 PrkBrkStatus 1;
BA_ "U_T6_MCA_MY2020_Rx" SG_ 956 PrkBrkStatus 1;
BA_ "U_CX727_MY2021_Rx" SG_ 956 PrkBrkStatus 1;
BA_ "GenSigStartValue" SG_ 956 PrkBrkStatus 7;
BA_ "GenSigStartValueInteger" SG_ 956 PrkBrkStatus 7;
BA_ "U_CD764_MY2022_Rx" SG_ 956 GearLvrPos_D_Actl_UB 1;
BA_ "U_U55X_MY2022_Rx" SG_ 956 GearLvrPos_D_Actl_UB 1;
BA_ "U_CD542_MY2021_Rx" SG_ 956 GearLvrPos_D_Actl_UB 1;
BA_ "U_T6_MCA_MY2020_Rx" SG_ 956 GearLvrPos_D_Actl_UB 1;
BA_ "U_P702_MY2021_Rx" SG_ 956 GearLvrPos_D_Actl_UB 1;
BA_ "U_CX727_MY2021_Rx" SG_ 956 GearLvrPos_D_Actl_UB 1;
BA_ "U_CD764_MY2022_Rx" SG_ 956 PrkBrkStatus_UB 1;
BA_ "U_U55X_MY2022_Rx" SG_ 956 PrkBrkStatus_UB 1;
BA_ "U_CD542_MY2021_Rx" SG_ 956 PrkBrkStatus_UB 1;
BA_ "U_T6_MCA_MY2020_Rx" SG_ 956 PrkBrkStatus_UB 1;
BA_ "U_CX727_MY2021_Rx" SG_ 956 PrkBrkStatus_UB 1;
BA_ "U_CD764_MY2022_Rx" SG_ 956 ApedPos_Pc_ActlArb 1;
BA_ "U_U55X_MY2022_Rx" SG_ 956 ApedPos_Pc_ActlArb 1;
BA_ "U_CD542_MY2021_Rx" SG_ 956 ApedPos_Pc_ActlArb 1;
BA_ "U_T6_MCA_MY2020_Rx" SG_ 956 ApedPos_Pc_ActlArb 1;
BA_ "U_P702_MY2021_Rx" SG_ 956 ApedPos_Pc_ActlArb 1;
BA_ "U_CX727_MY2021_Rx" SG_ 956 ApedPos_Pc_ActlArb 1;
BA_ "U_CD764_MY2022_Rx" SG_ 956 ApedPos_Pc_ActlArb_UB 1;
BA_ "U_U55X_MY2022_Rx" SG_ 956 ApedPos_Pc_ActlArb_UB 1;
BA_ "U_CD542_MY2021_Rx" SG_ 956 ApedPos_Pc_ActlArb_UB 1;
BA_ "U_T6_MCA_MY2020_Rx" SG_ 956 ApedPos_Pc_ActlArb_UB 1;
BA_ "U_P702_MY2021_Rx" SG_ 956 ApedPos_Pc_ActlArb_UB 1;
BA_ "U_CX727_MY2021_Rx" SG_ 956 ApedPos_Pc_ActlArb_UB 1;
BA_ "U_CD764_MY2022_Rx" SG_ 956 GearLvrPos_D_Actl 1;
BA_ "U_U55X_MY2022_Rx" SG_ 956 GearLvrPos_D_Actl 1;
BA_ "U_CD542_MY2021_Rx" SG_ 956 GearLvrPos_D_Actl 1;
BA_ "U_T6_MCA_MY2020_Rx" SG_ 956 GearLvrPos_D_Actl 1;
BA_ "U_P702_MY2021_Rx" SG_ 956 GearLvrPos_D_Actl 1;
BA_ "U_CX727_MY2021_Rx" SG_ 956 GearLvrPos_D_Actl 1;
BA_ "GenSigStartValue" SG_ 956 GearLvrPos_D_Actl 14;
BA_ "GenSigStartValueInteger" SG_ 956 GearLvrPos_D_Actl 14;
BA_ "U_CD764_MY2022_Tx" SG_ 831 MirrorTelescopic_D_Rq 1;
BA_ "U_T6_MCA_MY2020_Tx" SG_ 831 MirrorTelescopic_D_Rq 1;
BA_ "U_T6_MCA_MY2020_Rx" SG_ 831 MirrorTelescopic_D_Rq 1;
BA_ "GenSigSendType" SG_ 831 MirrorTelescopic_D_Rq 3;
BA_ "U_CD764_MY2022_Tx" SG_ 831 RearPassWindowLockCmd 1;
BA_ "U_U55X_MY2022_Tx" SG_ 831 RearPassWindowLockCmd 1;
BA_ "U_CD542_MY2021_Tx" SG_ 831 RearPassWindowLockCmd 1;
BA_ "U_T6_MCA_MY2020_Tx" SG_ 831 RearPassWindowLockCmd 1;
BA_ "U_P702_MY2021_Tx" SG_ 831 RearPassWindowLockCmd 1;
BA_ "U_CX727_MY2021_Tx" SG_ 831 RearPassWindowLockCmd 1;
BA_ "U_CD764_MY2022_Rx" SG_ 831 RearPassWindowLockCmd 1;
BA_ "U_U55X_MY2022_Rx" SG_ 831 RearPassWindowLockCmd 1;
BA_ "U_CD542_MY2021_Rx" SG_ 831 RearPassWindowLockCmd 1;
BA_ "U_T6_MCA_MY2020_Rx" SG_ 831 RearPassWindowLockCmd 1;
BA_ "U_P702_MY2021_Rx" SG_ 831 RearPassWindowLockCmd 1;
BA_ "GenSigSendType" SG_ 831 RearPassWindowLockCmd 3;
BA_ "U_CD764_MY2022_Tx" SG_ 831 RearPassWindowCmd 1;
BA_ "U_U55X_MY2022_Tx" SG_ 831 RearPassWindowCmd 1;
BA_ "U_CD542_MY2021_Tx" SG_ 831 RearPassWindowCmd 1;
BA_ "U_T6_MCA_MY2020_Tx" SG_ 831 RearPassWindowCmd 1;
BA_ "U_P702_MY2021_Tx" SG_ 831 RearPassWindowCmd 1;
BA_ "U_CX727_MY2021_Tx" SG_ 831 RearPassWindowCmd 1;
BA_ "U_CD764_MY2022_Rx" SG_ 831 RearPassWindowCmd 1;
BA_ "U_U55X_MY2022_Rx" SG_ 831 RearPassWindowCmd 1;
BA_ "U_CD542_MY2021_Rx" SG_ 831 RearPassWindowCmd 1;
BA_ "U_T6_MCA_MY2020_Rx" SG_ 831 RearPassWindowCmd 1;
BA_ "U_P702_MY2021_Rx" SG_ 831 RearPassWindowCmd 1;
BA_ "GenSigSendType" SG_ 831 RearPassWindowCmd 3;
BA_ "WakeupSignal" SG_ 831 RearPassWindowCmd 1;
BA_ "U_CD764_MY2022_Tx" SG_ 831 PassWindowCmd 1;
BA_ "U_U55X_MY2022_Tx" SG_ 831 PassWindowCmd 1;
BA_ "U_CD542_MY2021_Tx" SG_ 831 PassWindowCmd 1;
BA_ "U_T6_MCA_MY2020_Tx" SG_ 831 PassWindowCmd 1;
BA_ "U_P702_MY2021_Tx" SG_ 831 PassWindowCmd 1;
BA_ "U_CX727_MY2021_Tx" SG_ 831 PassWindowCmd 1;
BA_ "U_CD764_MY2022_Rx" SG_ 831 PassWindowCmd 1;
BA_ "U_U55X_MY2022_Rx" SG_ 831 PassWindowCmd 1;
BA_ "U_CD542_MY2021_Rx" SG_ 831 PassWindowCmd 1;
BA_ "U_T6_MCA_MY2020_Rx" SG_ 831 PassWindowCmd 1;
BA_ "U_P702_MY2021_Rx" SG_ 831 PassWindowCmd 1;
BA_ "GenSigSendType" SG_ 831 PassWindowCmd 3;
BA_ "WakeupSignal" SG_ 831 PassWindowCmd 1;
BA_ "U_CD764_MY2022_Tx" SG_ 831 PassMirrorCmd 1;
BA_ "U_U55X_MY2022_Tx" SG_ 831 PassMirrorCmd 1;
BA_ "U_CD542_MY2021_Tx" SG_ 831 PassMirrorCmd 1;
BA_ "U_T6_MCA_MY2020_Tx" SG_ 831 PassMirrorCmd 1;
BA_ "U_P702_MY2021_Tx" SG_ 831 PassMirrorCmd 1;
BA_ "U_CX727_MY2021_Tx" SG_ 831 PassMirrorCmd 1;
BA_ "U_CD764_MY2022_Rx" SG_ 831 PassMirrorCmd 1;
BA_ "U_U55X_MY2022_Rx" SG_ 831 PassMirrorCmd 1;
BA_ "U_CD542_MY2021_Rx" SG_ 831 PassMirrorCmd 1;
BA_ "U_T6_MCA_MY2020_Rx" SG_ 831 PassMirrorCmd 1;
BA_ "U_P702_MY2021_Rx" SG_ 831 PassMirrorCmd 1;
BA_ "GenSigSendType" SG_ 831 PassMirrorCmd 3;
BA_ "WakeupSignal" SG_ 831 PassMirrorCmd 1;
BA_ "U_CD764_MY2022_Tx" SG_ 831 DipMirrorPosPassenger 1;
BA_ "U_U55X_MY2022_Tx" SG_ 831 DipMirrorPosPassenger 1;
BA_ "U_CD542_MY2021_Tx" SG_ 831 DipMirrorPosPassenger 1;
BA_ "U_T6_MCA_MY2020_Tx" SG_ 831 DipMirrorPosPassenger 1;
BA_ "U_P702_MY2021_Tx" SG_ 831 DipMirrorPosPassenger 1;
BA_ "U_CX727_MY2021_Tx" SG_ 831 DipMirrorPosPassenger 1;
BA_ "U_CD764_MY2022_Rx" SG_ 831 DipMirrorPosPassenger 1;
BA_ "U_CD542_MY2021_Rx" SG_ 831 DipMirrorPosPassenger 1;
BA_ "U_T6_MCA_MY2020_Rx" SG_ 831 DipMirrorPosPassenger 1;
BA_ "U_P702_MY2021_Rx" SG_ 831 DipMirrorPosPassenger 1;
BA_ "GenSigSendType" SG_ 831 DipMirrorPosPassenger 3;
BA_ "U_CD764_MY2022_Tx" SG_ 831 ActiveStoragePassenger 1;
BA_ "U_U55X_MY2022_Tx" SG_ 831 ActiveStoragePassenger 1;
BA_ "U_CD542_MY2021_Tx" SG_ 831 ActiveStoragePassenger 1;
BA_ "U_T6_MCA_MY2020_Tx" SG_ 831 ActiveStoragePassenger 1;
BA_ "U_P702_MY2021_Tx" SG_ 831 ActiveStoragePassenger 1;
BA_ "U_CX727_MY2021_Tx" SG_ 831 ActiveStoragePassenger 1;
BA_ "U_CD764_MY2022_Rx" SG_ 831 ActiveStoragePassenger 1;
BA_ "U_CD542_MY2021_Rx" SG_ 831 ActiveStoragePassenger 1;
BA_ "U_T6_MCA_MY2020_Rx" SG_ 831 ActiveStoragePassenger 1;
BA_ "U_P702_MY2021_Rx" SG_ 831 ActiveStoragePassenger 1;
BA_ "GenSigSendType" SG_ 831 ActiveStoragePassenger 3;
BA_ "U_CD764_MY2022_Tx" SG_ 831 RearDriverWindowPos 1;
BA_ "U_U55X_MY2022_Tx" SG_ 831 RearDriverWindowPos 1;
BA_ "U_CD542_MY2021_Tx" SG_ 831 RearDriverWindowPos 1;
BA_ "U_T6_MCA_MY2020_Tx" SG_ 831 RearDriverWindowPos 1;
BA_ "U_P702_MY2021_Tx" SG_ 831 RearDriverWindowPos 1;
BA_ "U_CX727_MY2021_Tx" SG_ 831 RearDriverWindowPos 1;
BA_ "ECGUsedRxSignal" SG_ 831 RearDriverWindowPos 1;
BA_ "U_CD764_MY2022_Rx" SG_ 831 RearDriverWindowPos 1;
BA_ "U_U55X_MY2022_Rx" SG_ 831 RearDriverWindowPos 1;
BA_ "U_CD542_MY2021_Rx" SG_ 831 RearDriverWindowPos 1;
BA_ "U_T6_MCA_MY2020_Rx" SG_ 831 RearDriverWindowPos 1;
BA_ "U_P702_MY2021_Rx" SG_ 831 RearDriverWindowPos 1;
BA_ "U_CX727_MY2021_Rx" SG_ 831 RearDriverWindowPos 1;
BA_ "GenSigSendType" SG_ 831 RearDriverWindowPos 3;
BA_ "WakeupSignal" SG_ 831 RearDriverWindowPos 1;
BA_ "U_CD764_MY2022_Tx" SG_ 831 DriverWindowPosition 1;
BA_ "U_U55X_MY2022_Tx" SG_ 831 DriverWindowPosition 1;
BA_ "U_CD542_MY2021_Tx" SG_ 831 DriverWindowPosition 1;
BA_ "U_T6_MCA_MY2020_Tx" SG_ 831 DriverWindowPosition 1;
BA_ "U_P702_MY2021_Tx" SG_ 831 DriverWindowPosition 1;
BA_ "U_CX727_MY2021_Tx" SG_ 831 DriverWindowPosition 1;
BA_ "ECGUsedRxSignal" SG_ 831 DriverWindowPosition 1;
BA_ "U_CD764_MY2022_Rx" SG_ 831 DriverWindowPosition 1;
BA_ "U_U55X_MY2022_Rx" SG_ 831 DriverWindowPosition 1;
BA_ "U_CD542_MY2021_Rx" SG_ 831 DriverWindowPosition 1;
BA_ "U_T6_MCA_MY2020_Rx" SG_ 831 DriverWindowPosition 1;
BA_ "U_P702_MY2021_Rx" SG_ 831 DriverWindowPosition 1;
BA_ "U_CX727_MY2021_Rx" SG_ 831 DriverWindowPosition 1;
BA_ "GenSigSendType" SG_ 831 DriverWindowPosition 3;
BA_ "WakeupSignal" SG_ 831 DriverWindowPosition 1;
BA_ "GenSigSendType" SG_ 1820 TesterPhysicalResHSWM 3;
BA_ "GenSigSendType" SG_ 1812 TesterPhysicalReqHSWM 3;
BA_ "U_U55X_MY2022_Tx" SG_ 787 DrLckCnt_No_ActlTgate 1;
BA_ "U_CD542_MY2021_Tx" SG_ 787 DrLckCnt_No_ActlTgate 1;
BA_ "U_T6_MCA_MY2020_Tx" SG_ 787 DrLckCnt_No_ActlTgate 1;
BA_ "U_CX727_MY2021_Tx" SG_ 787 DrLckCnt_No_ActlTgate 1;
BA_ "WakeupSignal" SG_ 787 DrLckCnt_No_ActlTgate 1;
BA_ "GenSigSendType" SG_ 787 PwTgateStepMsgTxt_B_Rq 3;
BA_ "U_CD542_MY2021_Tx" SG_ 787 PwTgateMsgTxt_B_Rq 1;
BA_ "U_T6_MCA_MY2020_Tx" SG_ 787 PwTgateMsgTxt_B_Rq 1;
BA_ "GenSigSendType" SG_ 787 PwTgateMsgTxt_B_Rq 3;
BA_ "U_CD542_MY2021_Tx" SG_ 787 PwTgateLamp_B_Rq 1;
BA_ "U_T6_MCA_MY2020_Tx" SG_ 787 PwTgateLamp_B_Rq 1;
BA_ "GenSigSendType" SG_ 787 PwTgateLamp_B_Rq 3;
BA_ "U_U55X_MY2022_Tx" SG_ 787 DrTgateChime2_D_Rq 1;
BA_ "U_CD542_MY2021_Tx" SG_ 787 DrTgateChime2_D_Rq 1;
BA_ "U_T6_MCA_MY2020_Tx" SG_ 787 DrTgateChime2_D_Rq 1;
BA_ "U_CX727_MY2021_Tx" SG_ 787 DrTgateChime2_D_Rq 1;
BA_ "GenSigSendType" SG_ 787 DrTgateChime2_D_Rq 3;
BA_ "WakeupSignal" SG_ 787 DrTgateChime2_D_Rq 1;
BA_ "U_U55X_MY2022_Tx" SG_ 787 DrTGate_D_Rq 1;
BA_ "U_CD542_MY2021_Tx" SG_ 787 DrTGate_D_Rq 1;
BA_ "U_T6_MCA_MY2020_Tx" SG_ 787 DrTGate_D_Rq 1;
BA_ "U_CX727_MY2021_Tx" SG_ 787 DrTGate_D_Rq 1;
BA_ "U_CD764_MY2022_Rx" SG_ 787 DrTGate_D_Rq 1;
BA_ "U_U55X_MY2022_Rx" SG_ 787 DrTGate_D_Rq 1;
BA_ "U_CD542_MY2021_Rx" SG_ 787 DrTGate_D_Rq 1;
BA_ "U_T6_MCA_MY2020_Rx" SG_ 787 DrTGate_D_Rq 1;
BA_ "U_CX727_MY2021_Rx" SG_ 787 DrTGate_D_Rq 1;
BA_ "GenSigSendType" SG_ 787 DrTGate_D_Rq 3;
BA_ "WakeupSignal" SG_ 787 DrTGate_D_Rq 1;
BA_ "U_U55X_MY2022_Tx" SG_ 787 PwLftgtIntSw_B_Stat 1;
BA_ "U_CD542_MY2021_Tx" SG_ 787 PwLftgtIntSw_B_Stat 1;
BA_ "U_T6_MCA_MY2020_Tx" SG_ 787 PwLftgtIntSw_B_Stat 1;
BA_ "U_CX727_MY2021_Tx" SG_ 787 PwLftgtIntSw_B_Stat 1;
BA_ "GenSigSendType" SG_ 787 PwLftgtIntSw_B_Stat 3;
BA_ "WakeupSignal" SG_ 787 PwLftgtIntSw_B_Stat 1;
BA_ "U_U55X_MY2022_Tx" SG_ 787 Power_Liftgate_Mode_Stt 1;
BA_ "U_CD542_MY2021_Tx" SG_ 787 Power_Liftgate_Mode_Stt 1;
BA_ "U_T6_MCA_MY2020_Tx" SG_ 787 Power_Liftgate_Mode_Stt 1;
BA_ "U_CX727_MY2021_Tx" SG_ 787 Power_Liftgate_Mode_Stt 1;
BA_ "GenSigSendType" SG_ 787 Power_Liftgate_Mode_Stt 3;
VAL_ 806 ClimtCoolRear_B_Rq 1 "On" 0 "Off" ;
VAL_ 806 ClimtHeatRear_D_Rq 7 "NotUsed4" 6 "NotUsed3" 5 "HtrCoreClntFlwOnly" 4 "PtcHtrTestMde" 3 "Defrost_Defog" 2 "FastTempPullDownHeatingReq" 1 "OpportunisticHeatingReq" 0 "NoHeatingRequest" ;
VAL_ 806 SnowPlowMde_B_Enbl 1 "Enable" 0 "Disable" ;
VAL_ 806 ClimtDeltaLoad_Pw_Actl 63 "Faulty" 62 "NoDataExists" ;
VAL_ 806 StopStrtDrvMde_B_RqBtn 1 "Pressed" 0 "Not_Pressed" ;
VAL_ 806 WndwFrontHeat_B_Stat 1 "On" 0 "Off" ;
VAL_ 806 HtrCorePump_B_Rq 1 "On" 0 "Off" ;
VAL_ 806 ClimtHeat_D_Rq 7 "NotUsed4" 6 "NotUsed3" 5 "HtrCoreClntFlwOnly" 4 "PtcHtrTestMde" 3 "Defrost_Defog" 2 "FastTempPullDownHeatingReq" 1 "OpportunisticHeatingReq" 0 "NoHeatingRequest" ;
VAL_ 806 ClimtCool_D_Rq 7 "NotUsed4" 6 "NotUsed3" 5 "NotUsed2" 4 "ElACTestMde" 3 "Defrost_Defog" 2 "FastTempPullDownCoolReq" 1 "OpportunisticCoolingReq" 0 "NoCoolingRequest" ;
VAL_ 806 HvacEvap_Te_Actl 1023 "Fault" ;
VAL_ 806 HvacAirCond_B_Rq 1 "Yes" 0 "No" ;
VAL_ 806 ClimtPw_B_Rq 1 "Yes" 0 "No" ;
VAL_ 950 Modulation_Ctrl 3 "Unused" 2 "FSK" 1 "ASK_FSK" 0 "ASK" ;
VAL_ 950 TirePress_Filter_Ctrl 3 "Streaming" 2 "Filter" 1 "Not_Used" 0 "Null" ;
VAL_ 857 LHS_Temp_Disp_Digit3 2 "_5" 1 "_0" 0 "OFF" ;
VAL_ 857 Front_Blower_Ind 15 "Display_Blank" 14 "14_Indicators_On" 13 "13_Indicators_On" 12 "12_Indicators_On" 11 "11_Indicators_On" 10 "10_Indicators_On" 9 "9_Indicators_On" 8 "8_Indicators_On" 7 "7_Indicators_On" 6 "6_Indicators_On" 5 "5_Indicators_On" 4 "4_Indicators_On" 3 "3_Indicators_On" 2 "2_Indicators_On" 1 "1_Indicator_On" 0 "Indicators_Off" ;
VAL_ 857 EATC_LHS_Unit 2 "Fahrenheit" 1 "Celsius" 0 "Off" ;
VAL_ 856 Frt_Blower_Speed2 15 "NotUsed_6" 14 "NotUsed_5" 13 "NotUsed_4" 12 "NotUsed_3" 11 "NotUsed_2" 10 "Zero_Blower" 9 "Max_Blower" 8 "Min_Blower" 7 "Blower_Speed_7" 6 "Blower_Speed_6" 5 "Blower_Speed_5" 4 "Blower_Speed_4" 3 "Blower_Speed_3" 2 "Blower_Speed_2" 1 "Blower_Speed_1" 0 "No_Request" ;
VAL_ 856 Psngr_Set_Temp 31 "HI" 30 "_29_5" 29 "_29_0" 28 "_28_5" 27 "_28_0" 26 "_27_5" 25 "_27_0" 24 "_26_5" 23 "_26_0" 22 "_25_5" 21 "_25_0" 20 "_24_5" 19 "_24_0" 18 "_23_5" 17 "_23_0" 16 "_22_5" 15 "_22_0" 14 "_21_5" 13 "_21_0" 12 "_20_5" 11 "_20_0" 10 "_19_5" 9 "_19_0" 8 "_18_5" 7 "_18_0" 6 "_17_5" 5 "_17_0" 4 "_16_5" 3 "_16_0" 2 "_15_5" 1 "LO" 0 "No_Request" ;
VAL_ 856 SnowPlowOn_B_Rq 1 "On" 0 "Off" ;
VAL_ 856 ClimtRearView_D_Stat 3 "ThirdRow" 2 "SecondRow" 1 "Both" 0 "NotDisplayed" ;
VAL_ 856 Rr_Btn_Status_2nd 31 "NotUsed_7" 30 "NotUsed_6" 29 "NotUsed_5" 28 "NotUsed_4" 27 "NotUsed_3" 26 "NotUsed_2" 25 "NotUsed_1" 24 "Third_Sync_Pressed" 23 "Third_Rr_Pwr_Pressed" 22 "Third_Auto_Pressed" 21 "Third_Pnl_Flr_Pressed" 20 "Third_Floor_Pressed" 19 "Third_Panel_Pressed" 18 "Third_Blwr_Dec_Pressed" 17 "Third_Blwr_Inc_Pressed" 16 "Rear_Lock_Pressed" 15 "RHS_Cld_Seat_Pressed" 14 "LHS_Cld_Seat_Pressed" 13 "RHS_Htd_Seat_Pressed" 12 "LHS_Htd_Seat_Pressed" 11 "Rear_Power_Pressed" 10 "AUTO_Pressed" 9 "Blwr_Dec_Pressed" 8 "Blwr_Inc_Pressed" 7 "RHS_Temp_Dec_Pressed" 6 "RHS_Temp_Inc_Pressed" 5 "LHS_Temp_Dec_Pressed" 4 "LHS_Temp_Inc_Pressed" 3 "Floor_Pressed" 2 "Panel_Floor_Pressed" 1 "Panel_Pressed" 0 "None_Pressed" ;
VAL_ 856 Rr_Btn_Status_1st 31 "NotUsed_7" 30 "NotUsed_6" 29 "NotUsed_5" 28 "NotUsed_4" 27 "NotUsed_3" 26 "NotUsed_2" 25 "NotUsed_1" 24 "Third_Sync_Pressed" 23 "Third_Rr_Pwr_Pressed" 22 "Third_Auto_Pressed" 21 "Third_Pnl_Flr_Pressed" 20 "Third_Floor_Pressed" 19 "Third_Panel_Pressed" 18 "Third_Blwr_Dec_Pressed" 17 "Third_Blwr_Inc_Pressed" 16 "Rear_Lock_Pressed" 15 "RHS_Cld_Seat_Pressed" 14 "LHS_Cld_Seat_Pressed" 13 "RHS_Htd_Seat_Pressed" 12 "LHS_Htd_Seat_Pressed" 11 "Rear_Power_Pressed" 10 "AUTO_Pressed" 9 "Blwr_Dec_Pressed" 8 "Blwr_Inc_Pressed" 7 "RHS_Temp_Dec_Pressed" 6 "RHS_Temp_Inc_Pressed" 5 "LHS_Temp_Dec_Pressed" 4 "LHS_Temp_Inc_Pressed" 3 "Floor_Pressed" 2 "Panel_Floor_Pressed" 1 "Panel_Pressed" 0 "None_Pressed" ;
VAL_ 856 Frt_Btn_Status_2nd 4 "Floor_Ws_Pressed" 5 "AC_Pressed" 6 "Dual_Pressed" 7 "LHS_Temp_Inc_Pressed" 0 "None_Pressed" 1 "Panel_Pressed" 2 "Panel_Floor_Pressed" 3 "Floor_Pressed" 8 "LHS_Temp_Dec_Pressed" 9 "RHS_Temp_Inc_Pressed" 10 "RHS_Temp_Dec_Pressed" 11 "Blwr_Inc_Pressed" 12 "Blwr_Dec_Pressed" 13 "AUTO_Pressed" 14 "Max_AC_Pressed" 15 "Recirc_Pressed" 16 "Outside_Pressed" 17 "Auto_Recirc_Pressed" 18 "Htd_Frt_Wsh_Pressed" 19 "Windscreen_Pressed" 20 "Pnl_Ws_Pressed" 21 "Pnl_Flr_Ws_Pressed" 22 "Rear_Defrost_Pressed" 23 "Front_Power_Pressed" 24 "My_Temp_Pressed" 25 "Max_Defrost_Pressed" 26 "LHS_Htd_Seat_Pressed" 27 "RHS_Htd_Seat_Pressed" 28 "LHS_Cld_Seat_Pressed" 29 "RHS_Cld_Seat_Pressed" 30 "Htg_Strg_Whl_Pressed" 31 "Defrost_Pressed" 37 "DrvrFcsdMde_PRessed" 38 "LHS_Seat_Off_Pressed" 39 "LHS_Htd_Seat1_Pressed" 40 "LHS_Htd_Seat2_Pressed" 41 "LHS_Htd_Seat3_Pressed" 42 "LHS_Auto_Seat_Pressed" 43 "RHS_Seat_Off_Pressed" 44 "RHS_Htd_Seat1_Pressed" 45 "RHS_Htd_Seat2_Pressed" 46 "RHS_Htd_Seat3_Pressed" 47 "RHS_Auto_Seat_Pressed" 48 "LHS_Cld_Seat1_Pressed" 49 "LHS_Cld_Seat2_Pressed" 50 "LHS_Cld_Seat3_Pressed" 51 "RHS_Cld_Seat1_Pressed" 52 "RHS_Cld_Seat2_Pressed" 53 "RHS_Cld_Seat3_Pressed" 54 "AUTO_Lo_Pressed" 55 "AUTO_Med_Pressed" 56 "AUTO_Hi_Pressed" 57 "AUTO_Inc_Pressed" 58 "AUTO_Dec_Pressed" 59 "NotUsed_6" 60 "NotUsed_7" 61 "NotUsed_8" 62 "NotUsed_9" 63 "NotUsed_10" 32 "FrontMnu_Pressed" 33 "RearMnu_Pressed" 34 "Heat_Pressed" 35 "AAR_Pressed" 36 "MdeMnu_Pressed" ;
VAL_ 856 Frt_Btn_Status_1st 4 "Floor_Ws_Pressed" 5 "AC_Pressed" 6 "Dual_Pressed" 7 "LHS_Temp_Inc_Pressed" 0 "None_Pressed" 1 "Panel_Pressed" 2 "Panel_Floor_Pressed" 3 "Floor_Pressed" 8 "LHS_Temp_Dec_Pressed" 9 "RHS_Temp_Inc_Pressed" 10 "RHS_Temp_Dec_Pressed" 11 "Blwr_Inc_Pressed" 12 "Blwr_Dec_Pressed" 13 "AUTO_Pressed" 14 "Max_AC_Pressed" 15 "Recirc_Pressed" 16 "Outside_Pressed" 17 "Auto_Recirc_Pressed" 18 "Htd_Frt_Wsh_Pressed" 19 "Windscreen_Pressed" 20 "Pnl_Ws_Pressed" 21 "Pnl_Flr_Ws_Pressed" 22 "Rear_Defrost_Pressed" 23 "Front_Power_Pressed" 24 "My_Temp_Pressed" 25 "Max_Defrost_Pressed" 26 "LHS_Htd_Seat_Pressed" 27 "RHS_Htd_Seat_Pressed" 28 "LHS_Cld_Seat_Pressed" 29 "RHS_Cld_Seat_Pressed" 30 "Htg_Strg_Whl_Pressed" 31 "Defrost_Pressed" 37 "DrvrFcsdMde_PRessed" 38 "LHS_Seat_Off_Pressed" 39 "LHS_Htd_Seat1_Pressed" 40 "LHS_Htd_Seat2_Pressed" 41 "LHS_Htd_Seat3_Pressed" 42 "LHS_Auto_Seat_Pressed" 43 "RHS_Seat_Off_Pressed" 44 "RHS_Htd_Seat1_Pressed" 45 "RHS_Htd_Seat2_Pressed" 46 "RHS_Htd_Seat3_Pressed" 47 "RHS_Auto_Seat_Pressed" 48 "LHS_Cld_Seat1_Pressed" 49 "LHS_Cld_Seat2_Pressed" 50 "LHS_Cld_Seat3_Pressed" 51 "RHS_Cld_Seat1_Pressed" 52 "RHS_Cld_Seat2_Pressed" 53 "RHS_Cld_Seat3_Pressed" 54 "AUTO_Lo_Pressed" 55 "AUTO_Med_Pressed" 56 "AUTO_Hi_Pressed" 57 "AUTO_Inc_Pressed" 58 "AUTO_Dec_Pressed" 59 "NotUsed_6" 60 "NotUsed_7" 61 "NotUsed_8" 62 "NotUsed_9" 63 "NotUsed_10" 32 "FrontMnu_Pressed" 33 "RearMnu_Pressed" 34 "Heat_Pressed" 35 "AAR_Pressed" 36 "MdeMnu_Pressed" ;
VAL_ 856 Frt_Blower_Speed 3 "NotUsed" 2 "Max_Blower" 1 "Min_Blower" 0 "No_Request" ;
VAL_ 856 Drv_Set_Temp 31 "HI" 30 "29_5" 29 "29_0" 28 "28_5" 27 "28_0" 26 "27_5" 25 "27_0" 24 "26_5" 23 "26_0" 22 "25_5" 21 "25_0" 20 "24_5" 19 "24_0" 18 "23_5" 17 "23_0" 16 "22_5" 15 "22_0" 14 "21_5" 13 "21_0" 12 "20_5" 11 "20_0" 10 "19_5" 9 "19_0" 8 "18_5" 7 "18_0" 6 "17_5" 5 "17_0" 4 "16_5" 3 "16_0" 2 "15_5" 1 "LO" 0 "No_Request" ;
VAL_ 855 Rr_Temp_Detents 15 "Unused5" 14 "Unused4" 13 "Unused3" 12 "Unused2" 11 "Unused1" 10 "Display_Blank" 9 "_4_Heat_Bars" 8 "_3_Heat_Bars" 7 "_2_Heat_Bars" 6 "_1_Heat_Bar" 5 "Neutral_Bar_Only" 4 "_1_Cool_Bar" 3 "_2_Cool_Bars" 2 "_3_Cool_Bars" 1 "_4_Cool_Bars" 0 "No_Bars" ;
VAL_ 855 Rr_Power_Btn_Stt 3 "Unused" 2 "Disabled" 1 "Active" 0 "Enabled_Inactive" ;
VAL_ 855 Rr_RH_Cond_Seat_Stat 7 "Unused" 6 "Level_3_Heating" 5 "Level_2_Heating" 4 "Level_1_Heating" 3 "Level_3_Cooling" 2 "Level_2_Cooling" 1 "Level_1_Cooling" 0 "Off" ;
VAL_ 855 Rr_Pnl_Flr_Btn_Stt 3 "Unused" 2 "Disabled" 1 "Active" 0 "Enabled_Inactive" ;
VAL_ 855 Rr_LH_Cond_Seat_Stat 7 "Unused" 6 "Level_3_Heating" 5 "Level_2_Heating" 4 "Level_1_Heating" 3 "Level_3_Cooling" 2 "Level_2_Cooling" 1 "Level_1_Cooling" 0 "Off" ;
VAL_ 855 CC_Rr_Stat_User_Adj 15 "Unused9" 14 "Unused8" 13 "Unused7" 12 "Unused6" 11 "Unused5" 10 "Unused4" 9 "Unused3" 8 "Unused2" 7 "Unused1" 6 "Rr_Auto_Selection" 5 "Rr_Control_Selection" 4 "Rr_Power_Selection" 3 "Rr_Blwr_Spd_Selection" 2 "RRHS_SetPt_Selection" 1 "RLHS_SetPt_Selection" 0 "None" ;
VAL_ 855 Rr_Set_Temp_Units 2 "Fahrenheit" 1 "Celsius" 0 "Off" ;
VAL_ 855 Rr_RHS_Set_Temp_Dig3 2 "_5" 1 "_0" 0 "Off" ;
VAL_ 855 Rr_RHS_Set_Temp_Dig2 15 "Blank2" 14 "Blank1" 13 "I" 12 "H" 11 "O" 10 "L" 9 "_9" 8 "_8" 7 "_7" 6 "_6" 5 "_5" 4 "_4" 3 "_3" 2 "_2" 1 "_1" 0 "_0" ;
VAL_ 855 Rr_RHS_Set_Temp_Dig1 15 "Blank2" 14 "Blank1" 13 "I" 12 "H" 11 "O" 10 "L" 9 "_9" 8 "_8" 7 "_7" 6 "_6" 5 "_5" 4 "_4" 3 "_3" 2 "_2" 1 "_1" 0 "_0" ;
VAL_ 855 Rr_RH_Htd_Seat_Btn_Stt 3 "Unused" 2 "Disabled" 1 "Active" 0 "Enabled_Inactive" ;
VAL_ 855 Rr_RH_Cld_Seat_Btn_Stt 3 "Unused" 2 "Disabled" 1 "Active" 0 "Enabled_Inactive" ;
VAL_ 855 Rr_Panel_Btn_Stt 3 "Unused" 2 "Disabled" 1 "Active" 0 "Enabled_Inactive" ;
VAL_ 855 Rr_On_Indicator 1 "On" 0 "Off" ;
VAL_ 855 Rr_LHS_Set_Temp_Dig3 2 "_5" 1 "_0" 0 "Off" ;
VAL_ 855 Rr_LHS_Set_Temp_Dig2 15 "Blank2" 14 "Blank1" 13 "I" 12 "H" 11 "O" 10 "L" 9 "_9" 8 "_8" 7 "_7" 6 "_6" 5 "_5" 4 "_4" 3 "_3" 2 "_2" 1 "_1" 0 "_0" ;
VAL_ 855 Rr_LHS_Set_Temp_Dig1 15 "Blank2" 14 "Blank1" 13 "I" 12 "H" 11 "O" 10 "L" 9 "_9" 8 "_8" 7 "_7" 6 "_6" 5 "_5" 4 "_4" 3 "_3" 2 "_2" 1 "_1" 0 "_0" ;
VAL_ 855 Rr_LH_Htd_Seat_Btn_Stt 3 "Unused" 2 "Disabled" 1 "Active" 0 "Enabled_Inactive" ;
VAL_ 855 Rr_LH_Cld_Seat_Btn_Stt 3 "Unused" 2 "Disabled" 1 "Active" 0 "Enabled_Inactive" ;
VAL_ 855 Rr_Floor_Btn_Stt 3 "Unused" 2 "Disabled" 1 "Active" 0 "Enabled_Inactive" ;
VAL_ 855 Rr_Control_Btn_Stt 3 "Unused" 2 "Disabled" 1 "Active" 0 "Enabled_Inactive" ;
VAL_ 855 Rr_Blower_Indicate 15 "Display_Blank" 14 "14_Indicators_On" 13 "13_Indicators_On" 12 "12_Indicators_On" 11 "11_Indicators_On" 10 "10_Indicators_On" 9 "9_Indicators_On" 8 "8_Indicators_On" 7 "7_Indicators_On" 6 "6_Indicators_On" 5 "5_Indicators_On" 4 "4_Indicators_On" 3 "3_Indicators_On" 2 "2_Indicators_On" 1 "1_Indicator_On" 0 "Indicators_Off" ;
VAL_ 855 Rr_AUTO_Btn_Stt 3 "Unused" 2 "Disabled" 1 "Active" 0 "Enabled_Inactive" ;
VAL_ 854 Dsp_RotAddrBtnEv_St 15 "NotUsed_1" 14 "Pos_7Steps" 13 "Pos_6Steps" 12 "Pos_5Steps" 11 "Pos_4Steps" 10 "Pos_3Steps" 9 "Pos_2Steps" 8 "Pos_1Step" 7 "NotPressed" 6 "Neg_1Steps" 5 "Neg_2Steps" 4 "Neg_3Steps" 3 "Neg_4Steps" 2 "Neg_5Steps" 1 "Neg_6Steps" 0 "Neg_7Steps" ;
VAL_ 854 SelDrvMdeButtn_B_Stat 1 "Pressed" 0 "Not_Pressed" ;
VAL_ 854 SteEffortButtn_B_Stat 1 "Pressed" 0 "Not_Pressed" ;
VAL_ 854 LHS_Auto_Seat_Btn_Stt 3 "Unused" 2 "Disabled" 1 "Active" 0 "Enabled_Inactive" ;
VAL_ 854 RHS_Auto_Seat_Btn_Stt 3 "Unused" 2 "Disabled" 1 "Active" 0 "Enabled_Inactive" ;
VAL_ 854 SelDrvMdeSwtch_D_Stat2 3 "Faulty" 2 "SwitchState2" 1 "SwitchState1" 0 "NotPressed" ;
VAL_ 854 CC_Fr_Stat_User_Adj 7 "Unused4" 6 "RHS_AUTO_St_Selection" 5 "LHS_AUTO_St_Selection" 4 "DrvrFcsdMde_Selection" 3 "Fr_Blwr_Spd_Selection" 2 "FRHS_SetPt_Selection" 1 "FLHS_SetPt_Selection" 0 "None" ;
VAL_ 854 EngExhMdeQuiet_B_RqDrv 1 "Pressed" 0 "Not_Pressed" ;
VAL_ 854 LnchCtlSys_B_RqDrv 1 "Pressed" 0 "Not_Pressed" ;
VAL_ 854 Front_Blower_Indicate 15 "Display_Blank" 14 "14_Indicators_On" 13 "13_Indicators_On" 12 "12_Indicators_On" 11 "11_Indicators_On" 10 "10_Indicators_On" 9 "9_Indicators_On" 8 "8_Indicators_On" 7 "7_Indicators_On" 6 "6_Indicators_On" 5 "5_Indicators_On" 4 "4_Indicators_On" 3 "3_Indicators_On" 2 "2_Indicators_On" 1 "1_Indicator_On" 0 "Indicators_Off" ;
VAL_ 854 CC_Diagnostics_Active 1 "Yes" 0 "No" ;
VAL_ 854 RHS_Temp_Display_Digit3 2 "_5" 1 "_0" 0 "OFF" ;
VAL_ 854 LHS_Temp_Display_Digit3 2 "_5" 1 "_0" 0 "OFF" ;
VAL_ 854 EATC_RHS_Units 2 "Fahrenheit" 1 "Celsius" 0 "Off" ;
VAL_ 854 EATC_LHS_Units 2 "Fahrenheit" 1 "Celsius" 0 "Off" ;
VAL_ 534 WhlDirRr_D_Actl 3 "Faulty" 2 "NoDataExists" 1 "Backward" 0 "Forward" ;
VAL_ 534 WhlDirRl_D_Actl 3 "Faulty" 2 "NoDataExists" 1 "Backward" 0 "Forward" ;
VAL_ 534 WhlDirFr_D_Actl 3 "Faulty" 2 "NoDataExists" 1 "Backward" 0 "Forward" ;
VAL_ 534 WhlDirFl_D_Actl 3 "Faulty" 2 "NoDataExists" 1 "Backward" 0 "Forward" ;
VAL_ 772 SeatScrnDrvOn_B_Rq 1 "On" 0 "Off" ;
VAL_ 772 PwRnngBoardT_D_Stat 3 "NotUsed" 2 "Timer2" 1 "Timer1" 0 "Inactive" ;
VAL_ 772 PwRnngBoardSwtch_D_Stat 3 "NotUsed" 2 "DeployUnlocked" 1 "AlwaysActive" 0 "Inactive" ;
VAL_ 772 SeatSlprPosMsgTxt_B_Rq 1 "On" 0 "Off" ;
VAL_ 772 SeatPos_D_Stat 7 "NotUsed3" 6 "NotUsed2" 5 "Error" 4 "Drive" 3 "Moving" 2 "Pending" 1 "EasyEntry" 0 "Null" ;
VAL_ 772 MemDrvDeny_B_Stat 1 "Yes" 0 "No" ;
VAL_ 772 SeatSlprPosPsngr_D_Stat 3 "Faulty" 2 "Sleeper" 1 "Upright" 0 "Null" ;
VAL_ 772 Memory_Feedback_Rqst 1 "Yes" 0 "No" ;
VAL_ 772 Easy_Entry_Rqst 2 "Easy_Entry" 1 "Drive" 0 "Null" ;
VAL_ 772 Memory_Cmd 7 "Recall_3" 4 "Store_4" 3 "Store_3" 6 "Recall_2" 5 "Recall_1" 2 "Store_2" 1 "Store_1" 0 "Null" 8 "Recall_4" ;
VAL_ 772 Cancel_Auto_Movement 1 "Cancel" 0 "Null" ;
VAL_ 935 LcwaRight_D_Stat 7 "Faulty" 6 "NotUsed_3" 5 "NotUsed_2" 4 "NotUsed_1" 3 "Disabled" 2 "TemporaryUnavailable" 1 "SensorBlocked" 0 "Available" ;
VAL_ 935 LcwaDetctRight1_B_Stat 1 "Yes" 0 "No" ;
VAL_ 935 SodInnrRight_D_Stat 3 "Reporting" 2 "Not_Reporting" 1 "System_Standby" 0 "Initialization" ;
VAL_ 935 RbaCtaRight_D_Stat 7 "Faulty" 6 "NotUsed_2" 5 "NotUsed_1" 4 "Invalid" 3 "Disabled" 2 "On" 1 "Trailer_Tow_Off" 0 "Off" ;
VAL_ 935 LcwaDetctRight2_B_Stat 1 "Yes" 0 "No" ;
VAL_ 935 CtaInnrRight_D_Stat 3 "Reporting" 2 "Not_Reporting" 1 "System_Standby" 0 "Initialization" ;
VAL_ 935 CtaAlrtRight2_D_Stat 7 "NotUsed3" 6 "NotUsed2" 5 "NotUsed1" 4 "AlertZone4" 3 "AlertZone3" 2 "AlertZone2" 1 "AlertZone1" 0 "Off" ;
VAL_ 935 BttRight_D_Stat 7 "NotUsed" 6 "Disabled" 5 "Off" 4 "OffTemp" 3 "NotConnected" 2 "Pending" 1 "Connected" 0 "NotDetermined" ;
VAL_ 935 BttRight_D_RqDrv 3 "NotUsed" 2 "Request" 1 "NoRequest" 0 "Null" ;
VAL_ 935 CtaBrkRightMsgTxt_B_Rq 1 "Enable" 0 "Disable" ;
VAL_ 935 CtaRightBrkEnbl_B_Rq 1 "Enable" 0 "Disable" ;
VAL_ 935 CtaRightBrkDecel_B_Rq 1 "Enable" 0 "Disable" ;
VAL_ 935 CtaSnsRight_D_Stat 3 "Invalid" 2 "System_Failure" 1 "Blocked" 0 "Clear" ;
VAL_ 935 CtaAlrtRight_D_Stat 1 "On" 0 "Off" ;
VAL_ 935 CtaRight_D_Stat 7 "NotUsed_3" 6 "NotUsed_2" 5 "NotUsed_1" 4 "Invalid" 3 "Disabled" 2 "On" 1 "Trailer_Tow_Off" 0 "Off" ;
VAL_ 935 SodRight_D_Stat 7 "NotUsed_3" 6 "NotUsed_2" 5 "NotUsed_1" 4 "Invalid" 3 "Disabled" 2 "On" 1 "Trailer_Tow_Off" 0 "Off" ;
VAL_ 935 SodSnsRight_D_Stat 3 "Second_Warning_Audio" 2 "System_Failure" 1 "Blocked" 0 "Clear" ;
VAL_ 935 SodAlrtRight_D_Stat 3 "Bulb_Proveout" 2 "Flash" 1 "On" 0 "Off" ;
VAL_ 935 SodDetctRight_D_Stat 4 "Sensor_Blocked" 3 "Sensor_Fault" 2 "Flash_On" 1 "Alert_On" 0 "AlertOff_FlashOff_SensrClr" ;
VAL_ 934 RbaCtaLeft_D_Stat 7 "Faulty" 6 "NotUsed_2" 5 "NotUsed_1" 4 "Invalid" 3 "Disabled" 2 "On" 1 "Trailer_Tow_Off" 0 "Off" ;
VAL_ 934 SodInnrLeft_D_Stat 3 "Reporting" 2 "Not_Reporting" 1 "System_Standby" 0 "Initialization" ;
VAL_ 934 CtaInnrLeft_D_Stat 3 "Reporting" 2 "Not_Reporting" 1 "System_Standby" 0 "Initialization" ;
VAL_ 934 LcwaLeft_D_Stat 7 "Faulty" 6 "NotUsed_3" 5 "NotUsed_2" 4 "NotUsed_1" 3 "Disabled" 2 "TemporaryUnavailable" 1 "SensorBlocked" 0 "Available" ;
VAL_ 934 LcwaDetctLeft2_B_Stat 1 "Yes" 0 "No" ;
VAL_ 934 LcwaDetctLeft1_B_Stat 1 "Yes" 0 "No" ;
VAL_ 934 CtaAlrtLeft2_D_Stat 7 "NotUsed3" 6 "NotUsed2" 5 "NotUsed1" 4 "AlertZone4" 3 "AlertZone3" 2 "AlertZone2" 1 "AlertZone1" 0 "Off" ;
VAL_ 934 CtaBrkLeftMsgTxt_B_Rq 1 "Enable" 0 "Disable" ;
VAL_ 934 CtaLeftBrkDecel_B_Rq 1 "Enable" 0 "Disable" ;
VAL_ 934 CtaLeftBrkEnbl_B_Rq 1 "Enable" 0 "Disable" ;
VAL_ 934 BttLeft_D_Stat 7 "NotUsed" 6 "Disabled" 5 "Off" 4 "OffTemp" 3 "NotConnected" 2 "Pending" 1 "Connected" 0 "NotDetermined" ;
VAL_ 934 BttLeft_D_RqDrv 3 "NotUsed" 2 "Request" 1 "NoRequest" 0 "Null" ;
VAL_ 934 CtaSnsLeft_D_Stat 3 "Invalid" 2 "System_Failure" 1 "Blocked" 0 "Clear" ;
VAL_ 934 SodDetctLeft_D_Stat 4 "Sensor_Blocked" 3 "Sensor_Fault" 2 "Flash_On" 1 "Alert_On" 0 "AlertOff_FlashOff_SensrClr" ;
VAL_ 934 CtaLeft_D_Stat 7 "NotUsed_3" 6 "NotUsed_2" 5 "NotUsed_1" 4 "Invalid" 3 "Disabled" 2 "On" 1 "Trailer_Tow_Off" 0 "Off" ;
VAL_ 934 CtaAlrtLeft_D_Stat 1 "On" 0 "Off" ;
VAL_ 934 SodLeft_D_Stat 7 "NotUsed_3" 6 "NotUsed_2" 5 "NotUsed_1" 4 "Invalid" 3 "Disabled" 2 "On" 1 "Trailer_Tow_Off" 0 "Off" ;
VAL_ 934 SodSnsLeft_D_Stat 3 "Second_Warning_Audio" 2 "System_Failure" 1 "Blocked" 0 "Clear" ;
VAL_ 934 SodAlrtLeft_D_Stat 3 "Bulb_Proveout" 2 "Flash" 1 "On" 0 "Off" ;
VAL_ 969 WndwQtrRrDown_B_Stat 1 "Yes" 0 "No" ;
VAL_ 969 WndwQtrRlDown_B_Stat 1 "Yes" 0 "No" ;
VAL_ 969 Dimming_Level_Stat 3 "Low" 2 "Not_Used" 1 "High" 0 "Null" ;
VAL_ 969 Current_Color_Stat 15 "NotUsed7" 14 "NotUsed6" 13 "NotUsed5" 12 "NotUsed4" 11 "NotUsed3" 10 "NotUsed2" 9 "NotUsed1" 8 "Null" 7 "Color7" 6 "Color6" 5 "Color5" 4 "Color4" 3 "Color3" 2 "Color2" 1 "Color1" 0 "Off" ;
VAL_ 969 BlendedColorRed_Stat 15 "NotUsed10" 14 "NotUsed9" 13 "NotUsed8" 12 "NotUsed7" 11 "NotUsed6" 10 "NotUsed5" 9 "NotUsed4" 8 "NotUsed3" 7 "NotUsed2" 6 "NotUsed1" 5 "_5" 4 "_4" 3 "_3" 2 "_2" 1 "_1" 0 "Null" ;
VAL_ 969 BlendedColorGreen_Stat 15 "NotUsed10" 14 "NotUsed9" 13 "NotUsed8" 12 "NotUsed7" 11 "NotUsed6" 10 "NotUsed5" 9 "NotUsed4" 8 "NotUsed3" 7 "NotUsed2" 6 "NotUsed1" 5 "_5" 4 "_4" 3 "_3" 2 "_2" 1 "_1" 0 "Null" ;
VAL_ 969 BlendedColorBlue_Stat 15 "NotUsed10" 14 "NotUsed9" 13 "NotUsed8" 12 "NotUsed7" 11 "NotUsed6" 10 "NotUsed5" 9 "NotUsed4" 8 "NotUsed3" 7 "NotUsed2" 6 "NotUsed1" 5 "_5" 4 "_4" 3 "_3" 2 "_2" 1 "_1" 0 "Null" ;
VAL_ 969 BlendedColor_Stat 3 "NotUsed" 2 "Null" 1 "On" 0 "Off" ;
VAL_ 969 TurnLampRrOut_B_Stat 1 "Out" 0 "Null" ;
VAL_ 969 TurnLampRlOut_B_Stat 1 "Out" 0 "Null" ;
VAL_ 1070 StopStrtStdby_D_Indic_UB 1 "Fresh_data" 0 "Unchanged_data" ;
VAL_ 1070 PassRstrnInd_Req_UB 1 "Fresh_data" 0 "Unchanged_data" ;
VAL_ 1070 HiElPwInhbt_B_Stat_UB 1 "Fresh_data" 0 "Unchanged_data" ;
VAL_ 1070 HiElPwInhbt_B_Stat 1 "Inhibit" 0 "No_Inibit" ;
VAL_ 1070 StopStrtStdby_D_Indic 6 "Telltale_On_Grey" 5 "Telltale_Struck_Out" 4 "Telltale_Flashing_Amber" 3 "Telltale_On_Amber" 2 "Telltale_Flashing_Green" 1 "Telltale_On_Green" 0 "Telltale_Off" 7 "NotUsed3" ;
VAL_ 1070 CoolantFanStepAct_UB 1 "Fresh_data" 0 "Unchanged_data" ;
VAL_ 1070 CoolantFanStepAct 31 "Unused7" 30 "Unused6" 29 "Unused5" 28 "Unused4" 27 "Unused3" 26 "Unused2" 25 "Unused1" 23 "Step23" 22 "Step22" 21 "Step21" 20 "Step20" 19 "Step19" 18 "Step18" 17 "Step17" 16 "Step16" 15 "Step15" 14 "Step14" 13 "Step13" 12 "Step12" 11 "Step11" 10 "Step10" 9 "Step9" 8 "Step8" 7 "Step7" 6 "Step6" 5 "Step5" 4 "Step4" 3 "Step3" 2 "Step2" 1 "Step1" 24 "Max_Fan_Speed_Req" 0 "Fan_Cmd_Off" ;
VAL_ 1070 Reserve_UB 1 "Fresh_data" 0 "Unchanged_data" ;
VAL_ 1070 RstrnImpactEvntStatus_UB 1 "Fresh_data" 0 "Unchanged_data" ;
VAL_ 1070 EngAirIn_Te_Actl_UB 1 "Fresh_data" 0 "Unchanged_data" ;
VAL_ 1070 RstrnImpactEvntStatus 7 "Invalid" 6 "Not_Used_4" 5 "Threshold_2_Exceeded" 4 "Not_Used_3" 3 "Threshold_1_Exceeded" 2 "Not_Used_2" 1 "Not_Used_1" 0 "Normal" ;
VAL_ 1070 EngAirIn_Te_Actl 1023 "Fault" 1022 "Unknown" ;
VAL_ 1070 EngAout_N_Actl_UB 1 "Fresh_data" 0 "Unchanged_data" ;
VAL_ 1070 VehVActlEng_D_Qf 3 "OK" 2 "Not_Within_Specifications" 1 "No_Data_Exists" 0 "Faulty" ;
VAL_ 1070 Veh_V_ActlEng_UB 1 "Fresh_data" 0 "Unchanged_data" ;
VAL_ 1070 PassRstrnInd_Req 3 "ABOnNotIllum_OffNotIllum" 2 "AirbagOnNot_Illum_OffIllum" 1 "AirbagOn_Illum_OffNotIllum" 0 "AirbagOn_Illum_Off_Illum" ;
VAL_ 1050 CamraRearBttn_D_Stat 1 "Pressed" 0 "Not_Pressed" ;
VAL_ 1050 TrailCtlSwtch_B_Stat 1 "Pressed" 0 "Not_Pressed" ;
VAL_ 1050 CamraFrntBttn_D_Stat 1 "Pressed" 0 "Not_Pressed" ;
VAL_ 1050 AutoHoldSwtch_D_Stat 3 "Faulty" 2 "NotUsed" 1 "Pressed" 0 "Not_Pressed" ;
VAL_ 1050 EcoInhbt_B_RqHvac 1 "Yes" 0 "No" ;
VAL_ 1050 LpdbPtc3_B_Rq 1 "On" 0 "Off" ;
VAL_ 1050 LpdbPtc2_B_Rq 1 "On" 0 "Off" ;
VAL_ 1050 LpdbPtc1_B_Rq 1 "On" 0 "Off" ;
VAL_ 1050 LpdbHeatWiprPrk_B_Rq 1 "On" 0 "Off" ;
VAL_ 1050 LpdbDfrstRearOn_B_Rq 1 "On" 0 "Off" ;
VAL_ 1050 LpdbDfrstFrOn_B_Rq 1 "On" 0 "Off" ;
VAL_ 1050 LpdbDfrstFlOn_B_Rq 1 "On" 0 "Off" ;
VAL_ 1050 LpdbAuxBlwr_B_Rq 1 "On" 0 "Off" ;
VAL_ 1050 PrkAidSwtch_D_RqDrv 1 "Pressed" 0 "Not_Pressed" ;
VAL_ 1050 SteWhlHeat_D_Rq 15 "NotUsed6" 14 "NotUsed5" 13 "NotUsed4" 12 "NotUsed3" 11 "NotUsed2" 10 "NotUsed1" 9 "Reserved_3" 8 "Reserved_2" 7 "Reserved_1" 6 "Level_3_Heating" 5 "Level_3_Heating_LS" 4 "Level_2_Heating" 3 "Level_2_Heating_LS" 2 "Level_1_Heating" 1 "Level_1_Heating_LS" 0 "Off" ;
VAL_ 1050 MirrorHeatOn_B_Rq 1 "True" 0 "False" ;
VAL_ 1050 Remote_Start_QuietMode 1 "Quiet" 0 "Not_Quiet" ;
VAL_ 1050 DrvSlipCtlMde_B_Rq 1 "Pressed" 0 "Not_Pressed" ;
VAL_ 1050 Outside_Air_Temp_Stat 255 "Invalid" 254 "Unknown" ;
VAL_ 947 DrStatDrvErrCnt_B_Stat 1 "Yes" 0 "No" ;
VAL_ 947 TurnLghtRightOn_B_Stat 1 "On" 0 "Off" ;
VAL_ 947 TurnLghtLeftOn_B_Stat 1 "On" 0 "Off" ;
VAL_ 947 Backlit_LED_Status 15 "Unused3" 14 "Unused2" 13 "Unused1" 12 "Night_12" 11 "Night_11" 10 "Night_10" 9 "Night_9" 8 "Night_8" 7 "Night_7" 6 "Night_6" 5 "Night_5" 4 "Night_4" 3 "Night_3" 2 "Night_2" 1 "Night_1" 0 "Off" ;
VAL_ 947 FogLghtRearOn_B_Stat 1 "On" 0 "Off" ;
VAL_ 947 ValetMode_D_Mem 1 "On" 0 "Off" ;
VAL_ 947 IgnKeyType_D_Actl 15 "Invalid" 14 "Unknown" 3 "Key_Not_Prgrm_Read_Failure" 2 "Key_In_Ign_My_Key" 1 "Key_In_Ign_Standard_Key" 0 "Key_Read_In_Progress" ;
VAL_ 947 TurnLghtRight_D_Rq 3 "Seq" 2 "On" 1 "Off" 0 "Null" ;
VAL_ 947 Parklamp_Status 3 "Invalid" 2 "Unknown" 1 "On" 0 "Off" ;
VAL_ 947 Litval 255 "Invalid" 254 "Unknown" 5 "Day" 4 "Twilight_4" 3 "Twilight_3" 2 "Twilight_2" 1 "Twilight_1" 0 "Night" ;
VAL_ 947 Key_In_Ignition_Stat 1 "In" 0 "Out" ;
VAL_ 947 Ignition_Status 0 "Unknown" 1 "Off" 15 "Invalid" 8 "Start" 4 "Run" 2 "Accessory" ;
VAL_ 947 Dimming_Lvl 255 "Invalid" 254 "Unknown" 18 "Day_6" 17 "Day_5" 16 "Day_4" 15 "Day_3" 14 "Day_2" 13 "Day_1" 12 "Night_12" 11 "Night_11" 10 "Night_10" 9 "Night_9" 8 "Night_8" 7 "Night_7" 6 "Night_6" 5 "Night_5" 4 "Night_4" 3 "Night_3" 2 "Night_2" 1 "Night_1" 0 "Off" ;
VAL_ 947 Day_Night_Status 3 "NotUsed" 2 "Night" 1 "Day" 0 "Null" ;
VAL_ 947 Remote_Start_Status 3 "Invalid" 2 "Unknown" 1 "Remote" 0 "Null" ;
VAL_ 947 DrStatTgate_B_Actl 1 "Ajar" 0 "Closed" ;
VAL_ 947 DrStatRr_B_Actl 1 "Ajar" 0 "Closed" ;
VAL_ 947 DrStatRl_B_Actl 1 "Ajar" 0 "Closed" ;
VAL_ 947 DrStatPsngr_B_Actl 1 "Ajar" 0 "Closed" ;
VAL_ 947 DrStatInnrTgate_B_Actl 1 "Ajar" 0 "Closed" ;
VAL_ 947 DrStatHood_B_Actl 1 "Ajar" 0 "Closed" ;
VAL_ 947 DrStatDrv_B_Actl 1 "Ajar" 0 "Closed" ;
VAL_ 947 PrkBrkActv_B_Actl 1 "Active" 0 "Inactive" ;
VAL_ 947 LifeCycMde_D_Actl 3 "Transport" 2 "NotUsed" 1 "Factory" 0 "Normal" ;
VAL_ 947 Delay_Accy 1 "On" 0 "Off" ;
VAL_ 947 FogLghtFrontOn_B_Stat 1 "On" 0 "Off" ;
VAL_ 947 TurnLghtLeft_D_Rq 3 "Seq" 2 "On" 1 "Off" 0 "Null" ;
VAL_ 947 CrashEvnt_D_Stat 3 "Invalid" 2 "Fuel_Cutoff_Event" 1 "Deploy_Event" 0 "No_Event" ;
VAL_ 947 FuelPmpInhbt_B_Stat 1 "Inhibit" 0 "No_Inibit" ;
VAL_ 947 BodySrvcRqd_B_Rq 1 "Yes" 0 "No" ;
VAL_ 293 ClmtCtrlSeat_SetStat_Psgr 128 "H3_High_Heat__MAX" 64 "H2_Medium_Heat" 32 "H1_Low_Heat" 16 "C3_High_Cool__MAX" 8 "C2_Medium_Cool" 4 "C1_Low_Cool" 2 "Off" ;
VAL_ 293 ClmtCtrlSeat_SetStat_Dvr 128 "H3_High_Heat__MAX" 64 "H2_Medium_Heat" 32 "H1_Low_Heat" 16 "C3_High_Cool__MAX" 8 "C2_Medium_Cool" 4 "C1_Low_Cool" 2 "Off" ;
VAL_ 292 ClimtSeatRr_D_Rq 128 "H3_High_Heat__MAX" 64 "H2_Medium_Heat" 32 "H1_Low_Heat" 16 "C3_High_Cool__MAX" 8 "C2_Medium_Cool" 4 "C1_Low_Cool" 2 "Off" ;
VAL_ 292 ClimtSeatRl_D_Rq 128 "H3_High_Heat__MAX" 64 "H2_Medium_Heat" 32 "H1_Low_Heat" 16 "C3_High_Cool__MAX" 8 "C2_Medium_Cool" 4 "C1_Low_Cool" 2 "Off" ;
VAL_ 292 ClmtCtrlSeat_SetCmd_Psgr 128 "H3_High_Heat__MAX" 64 "H2_Medium_Heat" 32 "H1_Low_Heat" 16 "C3_High_Cool__MAX" 8 "C2_Medium_Cool" 4 "C1_Low_Cool" 2 "Off" ;
VAL_ 292 ClmtCtrlSeat_SetCmd_Dvr 128 "H3_High_Heat__MAX" 64 "H2_Medium_Heat" 32 "H1_Low_Heat" 16 "C3_High_Cool__MAX" 8 "C2_Medium_Cool" 4 "C1_Low_Cool" 2 "Off" ;
VAL_ 1126 GpsUtcYr_No_Actl 31 "Fault" ;
VAL_ 1126 GpsUtcMnth_No_Actl 15 "Fault" ;
VAL_ 1126 GPS_UTC_seconds 63 "Fault" 62 "Unknown" ;
VAL_ 1126 GPS_UTC_minutes 63 "Fault" 62 "Unknown" ;
VAL_ 1126 GPS_UTC_hours 31 "Invalid" 30 "Unknown" ;
VAL_ 1126 GPS_Pdop 31 "Invalid" 30 "Unknown" ;
VAL_ 1126 GPS_Compass_direction 7 "NorthWest" 6 "West" 5 "SouthWest" 4 "South" 3 "SouthEast" 2 "East" 1 "NorthEast" 0 "North" ;
VAL_ 1126 GPS_Actual_vs_Infer_pos 1 "Inferred_Position" 0 "Actual_Postition" ;
VAL_ 1126 Gps_B_Falt 1 "Yes" 0 "No" ;
VAL_ 1125 GpsHsphLongEast_D_Actl 0 "Invalid" 1 "Eastern" 2 "Western" 3 "Fault" ;
VAL_ 1125 GpsHsphLattSth_D_Actl 3 "Fault" 2 "Northern" 1 "Southern" 0 "Invalid" ;
VAL_ 1125 GPS_Longitude_Minutes 63 "Fault" 62 "Unknown" ;
VAL_ 1125 GPS_Longitude_Min_dec 16383 "Invalid" 16382 "Unknown" ;
VAL_ 1125 GPS_Longitude_Degrees 511 "Fault" 510 "Unknown" ;
VAL_ 1125 GPS_Latitude_Minutes 63 "Fault" 62 "Unknown" ;
VAL_ 1125 GPS_Latitude_Min_dec 16383 "Invalid" 16382 "Unknown" ;
VAL_ 1125 GPS_Latitude_Degrees 255 "Invalid" 254 "Unknown" ;
VAL_ 992 MsgCntrPersIndex_D_Rq 7 "Unused_3" 6 "Unused_2" 5 "Unused_1" 4 "Vehicle" 3 "PERS_4" 2 "PERS_3" 1 "PERS_2" 0 "PERS_1" ;
VAL_ 992 MsgCntrDsplyOp_D_Rq 7 "Unused_2" 6 "Unused_1" 5 "Copy" 4 "Restore" 3 "Upload" 2 "Set" 1 "Query" 0 "Null" ;
VAL_ 1127 GPS_Vdop 31 "Invalid" 30 "Unknown" ;
VAL_ 1127 GPS_Speed 255 "Invalid" 254 "Unknown" ;
VAL_ 1127 GPS_Sat_num_in_view 31 "Invalid" 30 "Unknown" ;
VAL_ 1127 GPS_MSL_altitude 4095 "Fault" 4094 "Unknown" ;
VAL_ 1127 GPS_Heading 65535 "Fault" 65534 "Unknown" ;
VAL_ 1127 GPS_Hdop 31 "Invalid" 30 "Unknown" ;
VAL_ 1127 GPS_dimension 2 "_3D" 1 "_2D" 0 "No_Fix" ;
VAL_ 861 SteWhlHeat_D_Stat 15 "NotUsed6" 14 "NotUsed5" 13 "NotUsed4" 12 "NotUsed3" 11 "NotUsed2" 10 "NotUsed1" 9 "Reserved_3" 8 "Reserved_2" 7 "Reserved_1" 6 "Level_3_Heating" 5 "Level_3_Heating_LS" 4 "Level_2_Heating" 3 "Level_2_Heating_LS" 2 "Level_1_Heating" 1 "Level_1_Heating_LS" 0 "Off" ;
VAL_ 999 PersIndexFcim_D_Actl 7 "Unused_3" 6 "Unused_2" 5 "Unused_1" 4 "Vehicle" 3 "PERS_4" 2 "PERS_3" 1 "PERS_2" 0 "PERS_1" ;
VAL_ 862 TwHlGrdAsst_B_RqTrn 1 "On" 0 "Off" ;
VAL_ 862 ApaSwtch_D_RqDrv 3 "NotUsed2" 2 "NotUsed1" 1 "Pressed" 0 "Not_Pressed" ;
VAL_ 862 HvacBlwrFront_D_Stat 31 "Not_Used" 20 "Full_On" 19 "95_Percent" 18 "90_Percent" 17 "85_Percent" 16 "80_Percent" 15 "75_Percent" 14 "70_Percent" 13 "65_Percent" 12 "60_Percent" 11 "55_Percent" 10 "50_Percent" 9 "45_Percent" 8 "40_Percent" 7 "35_Percent" 6 "30_Percent" 5 "25_Percent" 4 "20_Percent" 3 "15_Percent" 2 "10_Percent" 1 "5_Percent" 0 "Off" ;
VAL_ 862 HvacBlwrRear_D_Stat 31 "Not_Used" 20 "Full_On" 19 "95_Percent" 18 "90_Percent" 17 "85_Percent" 16 "80_Percent" 15 "75_Percent" 14 "70_Percent" 13 "65_Percent" 12 "60_Percent" 11 "55_Percent" 10 "50_Percent" 9 "45_Percent" 8 "40_Percent" 7 "35_Percent" 6 "30_Percent" 5 "25_Percent" 4 "20_Percent" 3 "15_Percent" 2 "10_Percent" 1 "5_Percent" 0 "Off" ;
VAL_ 862 EcoMde_D_RqDrv 3 "Faulty" 2 "On" 1 "Off" 0 "Null" ;
VAL_ 862 ClimtThrmlLoad_No_Actl 255 "Fault" ;
VAL_ 862 CamraDefog_B_Actl 1 "On" 0 "Off" ;
VAL_ 862 CabnAmb_Te_Actl 255 "Fault" ;
VAL_ 862 AutoStpHvacDelta_I_Est 255 "Fault" ;
VAL_ 828 DrvSpotLight_B_Rq 1 "Yes" 0 "No" ;
VAL_ 828 SpotLghtRight_D_Stat 1 "On" 0 "Off" ;
VAL_ 828 RearPassWindowPos 7 "Unused2" 6 "Unused1" 5 "Fully_Open" 4 "Bet60Percent_FullyOpen" 3 "Bet10Percent_60Percent" 2 "BetFully_10PercentOpen" 1 "Fully_Closed" 0 "Undefined" ;
VAL_ 828 PassWindowPosition 7 "Unused2" 6 "Unused1" 5 "Fully_Open" 4 "Bet60Percent_FullyOpen" 3 "Bet10Percent_60Percent" 2 "BetFully_10PercentOpen" 1 "Fully_Closed" 0 "Undefined" ;
VAL_ 828 SpotLghtLeft_D_Stat 1 "On" 0 "Off" ;
VAL_ 826 Memory_3_Sw_Stat 1 "Pressed" 0 "Null" ;
VAL_ 826 Memory_2_Sw_Stat 1 "Pressed" 0 "Null" ;
VAL_ 826 Memory_1_Sw_Stat 1 "Pressed" 0 "Null" ;
VAL_ 826 Mirror_Manual_Override 1 "Override" 0 "Null" ;
VAL_ 1098 TrlrAidSwtch_D_RqDrv 3 "Faulty" 2 "NotUsed" 1 "Pressed" 0 "Not_Pressed" ;
VAL_ 1098 TrlrAidCtl_U_RqDrv 4095 "Faulty" 4094 "NoDataExists" ;
VAL_ 1115 ClimtSeatRr_D_Stat 128 "H3_High_Heat__MAX" 64 "H2_Medium_Heat" 32 "H1_Low_Heat" 16 "C3_High_Cool__MAX" 8 "C2_Medium_Cool" 4 "C1_Low_Cool" 2 "Off" ;
VAL_ 1115 ClimtSeatRl_D_Stat 128 "H3_High_Heat__MAX" 64 "H2_Medium_Heat" 32 "H1_Low_Heat" 16 "C3_High_Cool__MAX" 8 "C2_Medium_Cool" 4 "C1_Low_Cool" 2 "Off" ;
VAL_ 853 MdeMnu_Buttn_Stat 1 "Pressed" 0 "Not_Pressed" ;
VAL_ 853 Front_AUTO_Blwr_Lvl 3 "High" 2 "Medium" 1 "Low" 0 "Off" ;
VAL_ 853 RearMnu_Buttn_Stat 1 "Pressed" 0 "Not_Pressed" ;
VAL_ 853 FrontMnu_Buttn_Stat 1 "Pressed" 0 "Not_Pressed" ;
VAL_ 853 DrvrFcsdMde_Btn_Stt 3 "Unused" 2 "Disabled" 1 "Active" 0 "Enabled_Inactive" ;
VAL_ 853 RHS_Cond_Seat_Status 7 "Unused" 6 "Level_3_Heating" 5 "Level_2_Heating" 4 "Level_1_Heating" 3 "Level_3_Cooling" 2 "Level_2_Cooling" 1 "Level_1_Cooling" 0 "Off" ;
VAL_ 853 LHS_Cond_Seat_Status 7 "Unused" 6 "Level_3_Heating" 5 "Level_2_Heating" 4 "Level_1_Heating" 3 "Level_3_Cooling" 2 "Level_2_Cooling" 1 "Level_1_Cooling" 0 "Off" ;
VAL_ 853 Htd_Strg_Whl_Status 3 "Level_3_Heating" 2 "Level_2_Heating" 1 "Level_1_Heating" 0 "Off" ;
VAL_ 853 Htd_Strg_Whl_Btn_Stt 3 "Unused" 2 "Disabled" 1 "Active" 0 "Enabled_Inactive" ;
VAL_ 853 Defrost_Btn_Stt 3 "Unused" 2 "Disabled" 1 "Active" 0 "Enabled_Inactive" ;
VAL_ 853 CC_Fr_Btn_User_Adj 31 "Unused15" 30 "Unused14" 29 "Unused13" 28 "Unused12" 27 "Unused11" 26 "Unused10" 25 "Unused9" 24 "Unused8" 23 "Unused7" 22 "Unused6" 21 "RHS_Cld_St_Selection" 20 "LHS_Cld_St_Selection" 19 "UFC_Interrupted" 18 "UFC_Complete" 17 "UFC_Active" 16 "Htd_WS_Selection" 15 "RHS_Htd_St_Selection" 14 "LHS_Htd_St_Selection" 13 "HSW_Selection" 12 "Dual_Selection" 11 "Rear_Defrost_Selection" 10 "Max_Defrost_Selection" 9 "Defrost_Selection" 8 "Fr_Air_Dist_Selection" 7 "Max_AC_Selection" 6 "Fr_Power_Selection" 5 "Recirc_Selection" 4 "AC_Selection" 3 "Fr_Auto_Selection" 2 "Use_MyTemp_Selection" 1 "Save_MyTemp_Selection" 0 "None" ;
VAL_ 853 RHS_Htd_Seat_Btn_Stt 3 "Unused" 2 "Disabled" 1 "Active" 0 "Enabled_Inactive" ;
VAL_ 853 RHS_Cld_Seat_Btn_Stt 3 "Unused" 2 "Disabled" 1 "Active" 0 "Enabled_Inactive" ;
VAL_ 853 Outside_Btn_Stt 3 "Unused" 2 "Disabled" 1 "Active" 0 "Enabled_Inactive" ;
VAL_ 853 LHS_Htd_Seat_Btn_Stt 3 "Unused" 2 "Disabled" 1 "Active" 0 "Enabled_Inactive" ;
VAL_ 853 LHS_Cld_Seat_Btn_Stt 3 "Unused" 2 "Disabled" 1 "Active" 0 "Enabled_Inactive" ;
VAL_ 853 Htd_Frt_Wsh_Btn_Stt 3 "Unused" 2 "Disabled" 1 "Active" 0 "Enabled_Inactive" ;
VAL_ 853 Auto_Recirc_Btn_Stt 3 "Unused" 2 "Disabled" 1 "Active" 0 "Enabled_Inactive" ;
VAL_ 853 Recirc_Btn_Stt 3 "Unused" 2 "Disabled" 1 "Active" 0 "Enabled_Inactive" ;
VAL_ 853 Rear_Defrost_Btn_Stt 3 "Unused" 2 "Disabled" 1 "Active" 0 "Enabled_Inactive" ;
VAL_ 853 My_Temp_Btn_Stt 3 "Unused" 2 "Disabled" 1 "Active" 0 "Enabled_Inactive" ;
VAL_ 853 Max_Defrost_Btn_Stt 3 "Unused" 2 "Disabled" 1 "Active" 0 "Enabled_Inactive" ;
VAL_ 853 Max_AC_Btn_Stt 3 "Unused" 2 "Disabled" 1 "Active" 0 "Enabled_Inactive" ;
VAL_ 853 Front_AUTO_Label 3 "Full" 2 "Mode" 1 "Blower" 0 "Off" ;
VAL_ 853 Windscreen_Btn_Stt 3 "Unused" 2 "Disabled" 1 "Active" 0 "Enabled_Inactive" ;
VAL_ 853 Panel_Btn_Stt 3 "Unused" 2 "Disabled" 1 "Active" 0 "Enabled_Inactive" ;
VAL_ 853 Front_Power_Btn_Stt 3 "Unused" 2 "Disabled" 1 "Active" 0 "Enabled_Inactive" ;
VAL_ 853 Front_AUTO_Btn_Stt 3 "Unused" 2 "Disabled" 1 "Active" 0 "Enabled_Inactive" ;
VAL_ 853 Floor_Btn_Stt 3 "Unused" 2 "Disabled" 1 "Active" 0 "Enabled_Inactive" ;
VAL_ 853 Dual_Button_Stt 3 "Unused" 2 "Disabled" 1 "Active" 0 "Enabled_Inactive" ;
VAL_ 853 AC_Btn_Stt 3 "Unused" 2 "Disabled" 1 "Active" 0 "Enabled_Inactive" ;
VAL_ 956 PwSrcULoFalt_D_Stat_UB 1 "Fresh_data" 0 "Unchanged_data" ;
VAL_ 956 PwSrcULo_Pc_Mx_UB 1 "Fresh_data" 0 "Unchanged_data" ;
VAL_ 956 PwSrcULo_Pc_Mx 255 "Fault" ;
VAL_ 956 WndwFrontHeat_B_Rq_UB 1 "Fresh_data" 0 "Unchanged_data" ;
VAL_ 956 WndwFrontHeat_B_Rq 1 "On" 0 "Off" ;
VAL_ 956 BattTrac_Te_Actl_UB 1 "Fresh_data" 0 "Unchanged_data" ;
VAL_ 956 BattTrac_Te_Actl 1023 "Fault" 1022 "Unknown" ;
VAL_ 956 PwSrcULoFalt_D_Stat 3 "Fault_No_Output" 2 "Fault_Reduced_Output" 1 "Fault_NonSpecific" 0 "No_Fault" ;
VAL_ 956 PrkBrkStatus 7 "GeneralFault_MaintenceMode" 6 "ECD_by_Brake_ECU_Active" 5 "EPB_Limphome_Active" 4 "Rear_Caliper_Open" 3 "RWU_By_EPB_Active" 2 "Rear_Caliper_Transition" 1 "Rear_Caliper_Closed" 0 "Not_Supported" ;
VAL_ 956 GearLvrPos_D_Actl_UB 1 "Fresh_data" 0 "Unchanged_data" ;
VAL_ 956 PrkBrkStatus_UB 1 "Fresh_data" 0 "Unchanged_data" ;
VAL_ 956 ApedPos_Pc_ActlArb_UB 1 "Fresh_data" 0 "Unchanged_data" ;
VAL_ 956 GearLvrPos_D_Actl 15 "Fault" 14 "Unknown_Position" 13 "Undefined_Treat_as__Fault" 12 "Undefined_Treat_as_Fault" 11 "sixth" 10 "fifth" 9 "fourth" 8 "third" 7 "second" 6 "first" 5 "Low" 4 "Sport_DriveSport" 3 "Drive" 2 "Neutral" 1 "Reverse" 0 "Park" ;
VAL_ 831 MirrorTelescopic_D_Rq 3 "NotUsed" 2 "Retract" 1 "Extend" 0 "Null" ;
VAL_ 831 RearPassWindowLockCmd 1 "Enable" 0 "Disable" ;
VAL_ 831 RearPassWindowCmd 7 "Unused2" 6 "Unused1" 5 "NotDefined" 4 "Audo_Down" 3 "Manual_Down" 2 "Auto_Up" 1 "Manual_Up" 0 "Idle" ;
VAL_ 831 PassWindowCmd 7 "Unused2" 6 "Unused1" 5 "NotDefined" 4 "Audo_Down" 3 "Manual_Down" 2 "Auto_Up" 1 "Manual_Up" 0 "Idle" ;
VAL_ 831 PassMirrorCmd 7 "Unused" 6 "Unfold" 5 "Fold" 4 "Right" 3 "Left" 2 "Down" 1 "Up" 0 "Idle" ;
VAL_ 831 DipMirrorPosPassenger 1 "Dipped" 0 "Off" ;
VAL_ 831 ActiveStoragePassenger 7 "Unused3" 6 "Unused2" 5 "Unused1" 4 "StoreDipMemoryButton4" 3 "StoreDipMemoryButton3" 2 "StoreDipMemoryButton2" 1 "StoreDipMemoryButton1" 0 "Off" ;
VAL_ 831 RearDriverWindowPos 7 "Unused2" 6 "Unused1" 5 "Fully_Open" 4 "Bet60Percent_FullyOpen" 3 "Bet10Percent_60Percent" 2 "BetFully_10PercentOpen" 1 "Fully_Closed" 0 "Undefined" ;
VAL_ 831 DriverWindowPosition 7 "Unused2" 6 "Unused1" 5 "Fully_Open" 4 "Bet60Percent_FullyOpen" 3 "Bet10Percent_60Percent" 2 "BetFully_10PercentOpen" 1 "Fully_Closed" 0 "Undefined" ;
VAL_ 787 PwTgateInhbtMsgTxt_B_Rq 1 "DisplayMessage" 0 "NoMessage" ;
VAL_ 787 PwTgateStepMsgTxt_B_Rq 1 "DisplayMessage" 0 "NoMessage" ;
VAL_ 787 PwTgateMsgTxt_B_Rq 1 "DisplayMessage" 0 "NoMessage" ;
VAL_ 787 PwTgateLamp_B_Rq 1 "On" 0 "Off" ;
VAL_ 787 DrTgateChime2_D_Rq 7 "NotUsed3" 6 "NotUsed2" 5 "NotUsed1" 4 "Long_Repeated" 3 "Fast" 2 "Short" 1 "Long" 0 "Off" ;
VAL_ 787 DrTGate_D_Rq 3 "NotUsed" 2 "Closing" 1 "Opening" 0 "Not_Moving" ;
VAL_ 787 PwLftgtIntSw_B_Stat 1 "Pressed" 0 "Null" ;
VAL_ 787 Power_Liftgate_Mode_Stt 2 "Unused" 3 "Not_Supported" 1 "Enabled" 0 "Disabled" ;
